// *************************************************************************** *
// *                                                                           *
// *                      Mentor Graphics Corporation                          *
// *                          All rights reserved                              *
// *                                                                           *
// *************************************************************************** *
// *                                                                           *
// * Description:         CANDB File                                           *
// * Generated at:        2021-09-06 14:00                                     *
// * System:              LPCsystem_MAIN                                       *
// * Network:             LPC1CAN                                              *
// *                                                                           *
// *************************************************************************** *
// *                                                                           *
// *             THIS CONFIGURATION MIGHT CONTAIN SOME ERRORS                  *
// *              IF THE INPUT MODEL WAS NOT PROPERLY FORMED!                  *
// *                    Do Not Use this File directly!                         *
// *                                                                           *
// *************************************************************************** *
VERSION "LPC1CAN"

NS_ :

BS_ :

BU_ :  LPC LPCdp LPCETC

BO_ 336 LpcdpLpc1canFr01_100ms : 48 LPCdp
 SG_ AccrPedlPsdSts : 360|1@0+ (1,0) [0|1] "" LPC
 SG_ AccrPedlPsdSts_UB : 361|1@0+ (1,0) [0|1] "" LPC
 SG_ BltRmnTelltl : 26|1@0+ (1,0) [0|1] "" LPC
 SG_ BltRmnTelltl_UB : 25|1@0+ (1,0) [0|1] "" LPC
 SG_ ChdProtnActvnReq_UB : 113|1@0+ (1,0) [0|1] "" LPC
 SG_ ChdProtnActvnReqDoorDrvrRe : 116|1@0+ (1,0) [0|1] "" LPC
 SG_ ChdProtnActvnReqDoorPass : 115|1@0+ (1,0) [0|1] "" LPC
 SG_ ChdProtnActvnReqDoorPassRe : 114|1@0+ (1,0) [0|1] "" LPC
 SG_ DblLckDi : 100|1@0+ (1,0) [0|1] "" LPC
 SG_ DblLckDi_UB : 99|1@0+ (1,0) [0|1] "" LPC
 SG_ DrvrDesDir1 : 108|3@0+ (1,0) [0|7] "" LPC
 SG_ DrvrDesDir1_UB : 105|1@0+ (1,0) [0|1] "" LPC
 SG_ DynCfgStrWhlPosnForUSS : 98|1@0+ (1,0) [0|1] "" LPC
 SG_ DynCfgStrWhlPosnForUSS_UB : 205|1@0+ (1,0) [0|1] "" LPC
 SG_ DynCfgVehTypForUSS : 311|16@0+ (1,0) [0|65535] "" LPC
 SG_ DynCfgVehTypForUSS_UB : 327|1@0+ (1,0) [0|1] "" LPC
 SG_ FrntWiprReq : 1|2@0+ (1,0) [0|3] "" LPC
 SG_ FrntWiprReq_UB : 2|1@0+ (1,0) [0|1] "" LPC
 SG_ FwdLookCamHeatingReq : 6|1@0+ (1,0) [0|1] "" LPC
 SG_ FwdLookCamHeatingReq_UB : 7|1@0+ (1,0) [0|1] "" LPC
 SG_ GlobalRealTimeGS : 279|32@0+ (1.0,0.0) [0.0|4294967295.0] "Unitless" LPC
 SG_ GlobalRealTimeGS_UB : 206|1@0+ (1,0) [0|1] "" LPC
 SG_ GlvBoxRelsBtnPsd : 23|1@0+ (1,0) [0|1] "" LPC
 SG_ GlvBoxRelsBtnPsd_UB : 24|1@0+ (1,0) [0|1] "" LPC
 SG_ HMISts : 84|2@0+ (1,0) [0|3] "" LPC
 SG_ HMISts_UB : 207|1@0+ (1,0) [0|1] "" LPC
 SG_ LcmaIndcnDrvr : 4|2@0+ (1,0) [0|3] "" LPC
 SG_ LcmaIndcnDrvr_UB : 5|1@0+ (1,0) [0|1] "" LPC
 SG_ LcmaIndcnPass : 39|2@0+ (1,0) [0|3] "" LPC
 SG_ LcmaIndcnPass_UB : 33|1@0+ (1,0) [0|1] "" LPC
 SG_ LockgExtReq_UB : 326|1@0+ (1,0) [0|1] "" LPC
 SG_ LockgExtReqLockActv : 351|4@0+ (1,0) [0|15] "" LPC
 SG_ LockgExtReqLockDly : 359|8@0+ (0.01,0.0) [0.0|2.5500000000000003] "Unitless" LPC
 SG_ LockgExtReqLockRep : 347|4@0- (1.0,0.0) [-8.0|7.0] "Unitless" LPC
 SG_ LockgPrsnlReq : 9|2@0+ (1,0) [0|3] "" LPC
 SG_ LockgPrsnlReq_UB : 10|1@0+ (1,0) [0|1] "" LPC
 SG_ LockgSetgFb_UB : 80|1@0+ (1,0) [0|1] "" LPC
 SG_ LockgSetgFbAudibleFeedback : 82|1@0+ (1,0) [0|1] "" LPC
 SG_ LockgSetgFbVisibleFeedback : 81|1@0+ (1,0) [0|1] "" LPC
 SG_ LockgSetgPas_UB : 91|1@0+ (1,0) [0|1] "" LPC
 SG_ LockgSetgPasLockBySpeed : 95|1@0+ (1,0) [0|1] "" LPC
 SG_ LockgSetgPasLockWalkAway : 94|1@0+ (1,0) [0|1] "" LPC
 SG_ LockgSetgPasUnlockApproach : 93|1@0+ (1,0) [0|1] "" LPC
 SG_ LockgSetgSngDoorUnlck : 92|1@0+ (1,0) [0|1] "" LPC
 SG_ LockgSetgSngDoorUnlck_UB : 32|1@0+ (1,0) [0|1] "" LPC
 SG_ MirrAutoDimSetg : 31|1@0+ (1,0) [0|1] "" LPC
 SG_ MirrAutoDimSetg_UB : 30|1@0+ (1,0) [0|1] "" LPC
 SG_ MirrCmdRecAtDrvr_UB : 16|1@0+ (1,0) [0|1] "" LPC
 SG_ MirrCmdRecAtDrvrMirrFoldCmd : 12|2@0+ (1,0) [0|3] "" LPC
 SG_ MirrCmdRecAtDrvrMirrPosAdjCmd : 15|3@0+ (1,0) [0|7] "" LPC
 SG_ MirrCmdRecAtPass_UB : 22|1@0+ (1,0) [0|1] "" LPC
 SG_ MirrCmdRecAtPassMirrFoldCmd : 21|2@0+ (1,0) [0|3] "" LPC
 SG_ MirrCmdRecAtPassMirrPosAdjCmd : 19|3@0+ (1,0) [0|7] "" LPC
 SG_ MirrDfrstType : 179|2@0+ (1,0) [0|3] "" LPC
 SG_ MirrDfrstType_UB : 177|1@0+ (1,0) [0|1] "" LPC
 SG_ MirrorDefrosterReq : 28|2@0+ (1,0) [0|3] "" LPC
 SG_ MirrorDefrosterReq_UB : 29|1@0+ (1,0) [0|1] "" LPC
 SG_ MirrorFuncCarCfg_UB : 180|1@0+ (1,0) [0|1] "" LPC
 SG_ MirrorFuncCarCfgExtRearViewMirrorType : 191|3@0+ (1,0) [0|7] "" LPC
 SG_ MirrorFuncCarCfgRearViewMirrorDimType : 188|3@0+ (1,0) [0|7] "" LPC
 SG_ MirrorFuncCarCfgRearViewMirrorMemType : 185|2@0+ (1,0) [0|3] "" LPC
 SG_ MirrPosnSensTrgtValDrvr_UB : 117|1@0+ (1,0) [0|1] "" LPC
 SG_ MirrPosnSensTrgtValDrvrMirrSensXPos : 127|16@0+ (1.0,0.0) [0.0|65535.0] "Unitless" LPC
 SG_ MirrPosnSensTrgtValDrvrMirrSensYPos : 143|16@0+ (1.0,0.0) [0.0|65535.0] "Unitless" LPC
 SG_ MirrPosnSensTrgtValPass_UB : 118|1@0+ (1,0) [0|1] "" LPC
 SG_ MirrPosnSensTrgtValPassMirrSensXPos : 47|16@0+ (1.0,0.0) [0.0|65535.0] "Unitless" LPC
 SG_ MirrPosnSensTrgtValPassMirrSensYPos : 63|16@0+ (1.0,0.0) [0.0|65535.0] "Unitless" LPC
 SG_ OutsideTemperatureGS : 335|16@0+ (1.0,0.0) [0.0|65535.0] "Unitless" LPC
 SG_ OutsideTemperatureGS_UB : 325|1@0+ (1,0) [0|1] "" LPC
 SG_ PassAirbLmpReq_UB : 176|1@0+ (1,0) [0|1] "" LPC
 SG_ PassAirbLmpReqChks : 152|8@1+ (1.0,0.0) [0.0|255.0] "Unitless" LPC
 SG_ PassAirbLmpReqCntr : 160|4@1+ (1.0,0.0) [0.0|15.0] "Unitless" LPC
 SG_ PassAirbLmpReqPassAirbLmpReq : 168|2@1+ (1,0) [0|3] "" LPC
 SG_ RainSnsrLiThdCmd : 323|4@0+ (5.0,-40.0) [-40.0|35.0] "%" LPC
 SG_ RainSnsrLiThdCmd_UB : 324|1@0+ (1,0) [0|1] "" LPC
 SG_ SnsrLiSnvty : 103|3@0+ (1,0) [0|7] "" LPC
 SG_ SnsrLiSnvty_UB : 119|1@0+ (1,0) [0|1] "" LPC
 SG_ SteerWhlLocCarCfgForDCU : 183|2@0+ (1,0) [0|3] "" LPC
 SG_ SteerWhlLocCarCfgForDCU_UB : 181|1@0+ (1,0) [0|1] "" LPC
 SG_ TotalDistanceGS : 215|32@0+ (1.0,0.0) [0.0|4294967295.0] "Unitless" LPC
 SG_ TotalDistanceGS_UB : 112|1@0+ (1,0) [0|1] "" LPC
 SG_ TrlrLampChkReq : 79|2@0+ (1,0) [0|3] "" LPC
 SG_ TrlrLampChkReq_UB : 77|1@0+ (1,0) [0|1] "" LPC
 SG_ TrOpenerBtnAcvtnReq : 97|2@0+ (1,0) [0|3] "" LPC
 SG_ TrOpenerBtnAcvtnReq_UB : 104|1@0+ (1,0) [0|1] "" LPC
 SG_ TwbrFoldFromHMI : 86|2@0+ (1,0) [0|3] "" LPC
 SG_ TwbrFoldFromHMI_UB : 87|1@0+ (1,0) [0|1] "" LPC
 SG_ TwliBriSts : 76|1@0+ (1,0) [0|1] "" LPC
 SG_ TwliBriSts_UB : 75|1@0+ (1,0) [0|1] "" LPC
 SG_ UsageModeGS : 247|8@0+ (1.0,0.0) [0.0|255.0] "Unitless" LPC
 SG_ UsageModeGS_UB : 201|1@0+ (1,0) [0|1] "" LPC
 SG_ VehAlrmDstbc : 271|8@0+ (1.0,0.0) [0.0|255.0] "Unitless" LPC
 SG_ VehAlrmDstbc_UB : 204|1@0+ (1,0) [0|1] "" LPC
 SG_ VehAlrmExtReq : 110|2@0+ (1,0) [0|3] "" LPC
 SG_ VehAlrmExtReq_UB : 111|1@0+ (1,0) [0|1] "" LPC
 SG_ VehAlrmPasDeactvnReq : 73|2@0+ (1,0) [0|3] "" LPC
 SG_ VehAlrmPasDeactvnReq_UB : 74|1@0+ (1,0) [0|1] "" LPC
 SG_ VehAlrmRednSts : 89|2@0+ (1,0) [0|3] "" LPC
 SG_ VehAlrmRednSts_UB : 90|1@0+ (1,0) [0|1] "" LPC
 SG_ VehicleBatteryVoltageGS : 255|8@0+ (1.0,0.0) [0.0|255.0] "Unitless" LPC
 SG_ VehicleBatteryVoltageGS_UB : 202|1@0+ (1,0) [0|1] "" LPC
 SG_ VehicleSpeedGS : 263|8@0+ (1.0,0.0) [0.0|255.0] "Unitless" LPC
 SG_ VehicleSpeedGS_UB : 203|1@0+ (1,0) [0|1] "" LPC
 SG_ VehTypeIfSPA2 : 37|3@0+ (1,0) [0|7] "" LPC
 SG_ VehTypeIfSPA2_UB : 34|1@0+ (1,0) [0|1] "" LPC
 SG_ WindowsFuncCarCfg_UB : 200|1@0+ (1,0) [0|1] "" LPC
 SG_ WindowsFuncCarCfgPinchProtectionLvl : 199|2@0+ (1,0) [0|3] "" LPC
 SG_ WindowsFuncCarCfgReserved0 : 197|2@0+ (1,0) [0|3] "" LPC
 SG_ WindowsFuncCarCfgTailgateWindowTintType : 195|2@0+ (1,0) [0|3] "" LPC
 SG_ WindowsFuncCarCfgWindowsGlassType : 193|2@0+ (1,0) [0|3] "" LPC

BO_ 338 LpcdpLpc1canFr02_10ms : 64 LPCdp
 SG_ ApduRespLpcFromIntrEth_UB : 449|1@0+ (1,0) [0|1] "" LPC
 SG_ ApduRespLpcFromIntrEthByte0 : 31|8@0+ (1.0,0.0) [0.0|255.0] "Unitless" LPC
 SG_ ApduRespLpcFromIntrEthByte1 : 39|8@0+ (1.0,0.0) [0.0|255.0] "Unitless" LPC
 SG_ ApduRespLpcFromIntrEthByte2 : 47|8@0+ (1.0,0.0) [0.0|255.0] "Unitless" LPC
 SG_ ApduRespLpcFromIntrEthByte3 : 55|8@0+ (1.0,0.0) [0.0|255.0] "Unitless" LPC
 SG_ ApduRespLpcFromIntrEthByte4 : 63|8@0+ (1.0,0.0) [0.0|255.0] "Unitless" LPC
 SG_ ApduRespLpcFromIntrEthByte5 : 71|8@0+ (1.0,0.0) [0.0|255.0] "Unitless" LPC
 SG_ ApduRespLpcFromIntrEthByte6 : 79|8@0+ (1.0,0.0) [0.0|255.0] "Unitless" LPC
 SG_ ApduRespLpcFromIntrEthByte7 : 87|8@0+ (1.0,0.0) [0.0|255.0] "Unitless" LPC
 SG_ ApplIdStsIntrEth : 379|3@0+ (1,0) [0|7] "" LPC
 SG_ ApplIdStsIntrEth_UB : 376|1@0+ (1,0) [0|1] "" LPC
 SG_ BltLockStDrvr : 419|1@0+ (1,0) [0|1] "" LPC
 SG_ BltLockStDrvr_UB : 418|1@0+ (1,0) [0|1] "" LPC
 SG_ CarModeSync_UB : 424|1@0+ (1,0) [0|1] "" LPC
 SG_ CarModeSyncCarMode : 431|4@0+ (1,0) [0|15] "" LPC
 SG_ CarModeSyncCarModeSubtype : 427|3@0+ (1,0) [0|7] "" LPC
 SG_ CrashModeSync : 417|1@0+ (1,0) [0|1] "" LPC
 SG_ CrashModeSync_UB : 416|1@0+ (1,0) [0|1] "" LPC
 SG_ GearLvlIndcn : 434|3@0+ (1,0) [0|7] "" LPC
 SG_ GearLvlIndcn_UB : 435|1@0+ (1,0) [0|1] "" LPC
 SG_ IntrBriStsAmb : 367|4@0+ (1.0,0.0) [0.0|15.0] "Unitless" LPC
 SG_ IntrBriStsAmb_UB : 445|1@0+ (1,0) [0|1] "" LPC
 SG_ IntrBriStsCsd : 363|4@0+ (1.0,0.0) [0.0|15.0] "Unitless" LPC
 SG_ IntrBriStsCsd_UB : 444|1@0+ (1,0) [0|1] "" LPC
 SG_ IntrBriStsDim : 375|4@0+ (1.0,0.0) [0.0|15.0] "Unitless" LPC
 SG_ IntrBriStsDim_UB : 443|1@0+ (1,0) [0|1] "" LPC
 SG_ IntrBriStsHud : 371|4@0+ (1.0,0.0) [0.0|15.0] "Unitless" LPC
 SG_ IntrBriStsHud_UB : 442|1@0+ (1,0) [0|1] "" LPC
 SG_ IntrBriStsSwt : 383|4@0+ (1.0,0.0) [0.0|15.0] "Unitless" LPC
 SG_ IntrBriStsSwt_UB : 441|1@0+ (1,0) [0|1] "" LPC
 SG_ IntrLiUsrPrsnt_UB : 440|1@0+ (1,0) [0|1] "" LPC
 SG_ IntrLiUsrPrsntDrvrSeat : 391|2@0+ (1,0) [0|3] "" LPC
 SG_ IntrLiUsrPrsntPassSeat : 389|2@0+ (1,0) [0|3] "" LPC
 SG_ IntrLiUsrPrsntReCentrSeat2nd : 387|2@0+ (1,0) [0|3] "" LPC
 SG_ IntrLiUsrPrsntReDrvrSeat2nd : 385|2@0+ (1,0) [0|3] "" LPC
 SG_ IntrLiUsrPrsntReDrvrSeat3nd : 399|2@0+ (1,0) [0|3] "" LPC
 SG_ IntrLiUsrPrsntRePassSeat2nd : 397|2@0+ (1,0) [0|3] "" LPC
 SG_ IntrLiUsrPrsntRePassSeat3nd : 395|2@0+ (1,0) [0|3] "" LPC
 SG_ IntrLiUsrPrsntTrAr : 393|2@0+ (1,0) [0|3] "" LPC
 SG_ PinionAg_UB : 7|1@0+ (1,0) [0|1] "" LPC
 SG_ PinionAgPinionSteerAg1 : 6|15@0- (0.0009765625,0.0) [-14.5|14.5] "rad" LPC
 SG_ PinionAgPinionSteerAg1Qf : 17|2@0+ (1,0) [0|3] "" LPC
 SG_ PowerControllerRlySync_UB : 454|1@0+ (1,0) [0|1] "" LPC
 SG_ PowerControllerRlySyncADPMWakeUpSync : 168|1@1+ (1,0) [0|1] "" LPC
 SG_ PowerControllerRlySyncAUDWakeUpSync : 169|1@1+ (1,0) [0|1] "" LPC
 SG_ PowerControllerRlySyncChks : 152|8@1+ (1.0,0.0) [0.0|255.0] "Unitless" LPC
 SG_ PowerControllerRlySyncClimateActuatorRelaySync : 170|1@1+ (1,0) [0|1] "" LPC
 SG_ PowerControllerRlySyncCntr : 160|4@1+ (1.0,0.0) [0.0|15.0] "Unitless" LPC
 SG_ PowerControllerRlySyncDIMWakeUpSync : 171|1@1+ (1,0) [0|1] "" LPC
 SG_ PowerControllerRlySyncExteriorLightRelaySync : 172|1@1+ (1,0) [0|1] "" LPC
 SG_ PowerControllerRlySyncIgnitionPowerRelaySync : 173|1@1+ (1,0) [0|1] "" LPC
 SG_ PowerControllerRlySyncSUMWakeUpSync : 174|1@1+ (1,0) [0|1] "" LPC
 SG_ PreApduSndIntrEth : 407|1@0+ (1,0) [0|1] "" LPC
 SG_ PreApduSndIntrEth_UB : 406|1@0+ (1,0) [0|1] "" LPC
 SG_ ServiceModeSync : 405|1@0+ (1,0) [0|1] "" LPC
 SG_ ServiceModeSync_UB : 404|1@0+ (1,0) [0|1] "" LPC
 SG_ SingleWipeReq : 437|2@0+ (1,0) [0|3] "" LPC
 SG_ SingleWipeReq_UB : 451|1@0+ (1,0) [0|1] "" LPC
 SG_ UsageAuthDriverAuthChk1 : 183|32@0+ (1.0,0.0) [0.0|4294967295.0] "Unitless" LPC
 SG_ UsageAuthDriverAuthChk1_UB : 453|1@0+ (1,0) [0|1] "" LPC
 SG_ UsageAuthDriverAuthChk2 : 215|32@0+ (1.0,0.0) [0.0|4294967295.0] "Unitless" LPC
 SG_ UsageAuthDriverAuthChk2_UB : 452|1@0+ (1,0) [0|1] "" LPC
 SG_ UsageModeAvailableSync : 403|1@0+ (1,0) [0|1] "" LPC
 SG_ UsageModeAvailableSync_UB : 402|1@0+ (1,0) [0|1] "" LPC
 SG_ UsageModeAwakeSync : 401|1@0+ (1,0) [0|1] "" LPC
 SG_ UsageModeAwakeSync_UB : 400|1@0+ (1,0) [0|1] "" LPC
 SG_ UsageModeConvenienceSync : 415|1@0+ (1,0) [0|1] "" LPC
 SG_ UsageModeConvenienceSync_UB : 414|1@0+ (1,0) [0|1] "" LPC
 SG_ UsageModeDrivingSync : 413|1@0+ (1,0) [0|1] "" LPC
 SG_ UsageModeDrivingSync_UB : 412|1@0+ (1,0) [0|1] "" LPC
 SG_ UsageModeMovableSync : 411|1@0+ (1,0) [0|1] "" LPC
 SG_ UsageModeMovableSync_UB : 410|1@0+ (1,0) [0|1] "" LPC
 SG_ UsageModeResponsiveSync : 409|1@0+ (1,0) [0|1] "" LPC
 SG_ UsageModeResponsiveSync_UB : 408|1@0+ (1,0) [0|1] "" LPC
 SG_ VehModMngmntSigDCU_UB : 450|1@0+ (1,0) [0|1] "" LPC
 SG_ VehModMngmntSigDCUCarModeSts : 479|3@0+ (1,0) [0|7] "" LPC
 SG_ VehModMngmntSigDCUCarModeSubType : 473|2@0+ (1,0) [0|3] "" LPC
 SG_ VehModMngmntSigDCUElecEnergyLvlDCU : 487|2@0+ (1,0) [0|3] "" LPC
 SG_ VehModMngmntSigDCUElecPowerLvlDCU : 485|3@0+ (1,0) [0|7] "" LPC
 SG_ VehModMngmntSigDCUReserved1 : 463|8@0+ (1.0,0.0) [0.0|255.0] "Unitless" LPC
 SG_ VehModMngmntSigDCUReserved2 : 471|8@0+ (1.0,0.0) [0.0|255.0] "Unitless" LPC
 SG_ VehModMngmntSigDCUUsageModeSts : 476|3@0+ (1,0) [0|7] "" LPC
 SG_ WinFunctnAvailbltySig : 423|3@0+ (1,0) [0|7] "" LPC
 SG_ WinFunctnAvailbltySig_UB : 420|1@0+ (1,0) [0|1] "" LPC

BO_ 340 LpcdpLpc1canFr04_10ms : 64 LPCdp
 SG_ ExLiLpHiDefZone1_UB : 440|1@0+ (1,0) [0|1] "" LPC
 SG_ ExLiLpHiDefZone1BottomAg : 7|9@0- (0.0015,0.0) [-0.384|0.3825] "rad" LPC
 SG_ ExLiLpHiDefZone1GradWdth : 14|9@0- (0.0015,0.0) [-0.384|0.3825] "rad" LPC
 SG_ ExLiLpHiDefZone1LeAgPrpty : 21|3@0+ (1.0,0.0) [0.0|7.0] "Unitless" LPC
 SG_ ExLiLpHiDefZone1LeLampLeAg : 17|10@0- (0.0015,0.0) [-0.768|0.7665000000000001] "rad" LPC
 SG_ ExLiLpHiDefZone1LeLampRiAg : 47|10@0- (0.0015,0.0) [-0.768|0.7665000000000001] "rad" LPC
 SG_ ExLiLpHiDefZone1ObjctZoneIntens : 39|8@0+ (1.0,0.0) [0.0|255.0] "Unitless" LPC
 SG_ ExLiLpHiDefZone1RiAgPrpty : 53|3@0+ (1.0,0.0) [0.0|7.0] "Unitless" LPC
 SG_ ExLiLpHiDefZone1RiLampLeAg : 49|10@0- (0.0015,0.0) [-0.768|0.7665000000000001] "rad" LPC
 SG_ ExLiLpHiDefZone1RiLampRiAg : 71|10@0- (0.0015,0.0) [-0.768|0.7665000000000001] "rad" LPC
 SG_ ExLiLpHiDefZone1TopAg : 77|9@0- (0.0015,0.0) [-0.384|0.3825] "rad" LPC
 SG_ ExLiLpHiDefZone2_UB : 441|1@0+ (1,0) [0|1] "" LPC
 SG_ ExLiLpHiDefZone2BottomAg : 95|9@0- (0.0015,0.0) [-0.384|0.3825] "rad" LPC
 SG_ ExLiLpHiDefZone2GradWdth : 102|9@0- (0.0015,0.0) [-0.384|0.3825] "rad" LPC
 SG_ ExLiLpHiDefZone2LeAgPrpty : 109|3@0+ (1.0,0.0) [0.0|7.0] "Unitless" LPC
 SG_ ExLiLpHiDefZone2LeLampLeAg : 105|10@0- (0.0015,0.0) [-0.768|0.7665000000000001] "rad" LPC
 SG_ ExLiLpHiDefZone2LeLampRiAg : 135|10@0- (0.0015,0.0) [-0.768|0.7665000000000001] "rad" LPC
 SG_ ExLiLpHiDefZone2ObjctZoneIntens : 127|8@0+ (1.0,0.0) [0.0|255.0] "Unitless" LPC
 SG_ ExLiLpHiDefZone2RiAgPrpty : 141|3@0+ (1.0,0.0) [0.0|7.0] "Unitless" LPC
 SG_ ExLiLpHiDefZone2RiLampLeAg : 137|10@0- (0.0015,0.0) [-0.768|0.7665000000000001] "rad" LPC
 SG_ ExLiLpHiDefZone2RiLampRiAg : 159|10@0- (0.0015,0.0) [-0.768|0.7665000000000001] "rad" LPC
 SG_ ExLiLpHiDefZone2TopAg : 165|9@0- (0.0015,0.0) [-0.384|0.3825] "rad" LPC
 SG_ ExLiLpHiDefZone3_UB : 442|1@0+ (1,0) [0|1] "" LPC
 SG_ ExLiLpHiDefZone3BottomAg : 183|9@0- (0.0015,0.0) [-0.384|0.3825] "rad" LPC
 SG_ ExLiLpHiDefZone3GradWdth : 190|9@0- (0.0015,0.0) [-0.384|0.3825] "rad" LPC
 SG_ ExLiLpHiDefZone3LeAgPrpty : 197|3@0+ (1.0,0.0) [0.0|7.0] "Unitless" LPC
 SG_ ExLiLpHiDefZone3LeLampLeAg : 193|10@0- (0.0015,0.0) [-0.768|0.7665000000000001] "rad" LPC
 SG_ ExLiLpHiDefZone3LeLampRiAg : 223|10@0- (0.0015,0.0) [-0.768|0.7665000000000001] "rad" LPC
 SG_ ExLiLpHiDefZone3ObjctZoneIntens : 215|8@0+ (1.0,0.0) [0.0|255.0] "Unitless" LPC
 SG_ ExLiLpHiDefZone3RiAgPrpty : 229|3@0+ (1.0,0.0) [0.0|7.0] "Unitless" LPC
 SG_ ExLiLpHiDefZone3RiLampLeAg : 225|10@0- (0.0015,0.0) [-0.768|0.7665000000000001] "rad" LPC
 SG_ ExLiLpHiDefZone3RiLampRiAg : 247|10@0- (0.0015,0.0) [-0.768|0.7665000000000001] "rad" LPC
 SG_ ExLiLpHiDefZone3TopAg : 253|9@0- (0.0015,0.0) [-0.384|0.3825] "rad" LPC
 SG_ ExLiLpHiDefZone4_UB : 443|1@0+ (1,0) [0|1] "" LPC
 SG_ ExLiLpHiDefZone4BottomAg : 271|9@0- (0.0015,0.0) [-0.384|0.3825] "rad" LPC
 SG_ ExLiLpHiDefZone4GradWdth : 278|9@0- (0.0015,0.0) [-0.384|0.3825] "rad" LPC
 SG_ ExLiLpHiDefZone4LeAgPrpty : 285|3@0+ (1.0,0.0) [0.0|7.0] "Unitless" LPC
 SG_ ExLiLpHiDefZone4LeLampLeAg : 281|10@0- (0.0015,0.0) [-0.768|0.7665000000000001] "rad" LPC
 SG_ ExLiLpHiDefZone4LeLampRiAg : 311|10@0- (0.0015,0.0) [-0.768|0.7665000000000001] "rad" LPC
 SG_ ExLiLpHiDefZone4ObjctZoneIntens : 303|8@0+ (1.0,0.0) [0.0|255.0] "Unitless" LPC
 SG_ ExLiLpHiDefZone4RiAgPrpty : 317|3@0+ (1.0,0.0) [0.0|7.0] "Unitless" LPC
 SG_ ExLiLpHiDefZone4RiLampLeAg : 313|10@0- (0.0015,0.0) [-0.768|0.7665000000000001] "rad" LPC
 SG_ ExLiLpHiDefZone4RiLampRiAg : 335|10@0- (0.0015,0.0) [-0.768|0.7665000000000001] "rad" LPC
 SG_ ExLiLpHiDefZone4TopAg : 341|9@0- (0.0015,0.0) [-0.384|0.3825] "rad" LPC
 SG_ ExLiLpHiDefZone5_UB : 444|1@0+ (1,0) [0|1] "" LPC
 SG_ ExLiLpHiDefZone5BottomAg : 359|9@0- (0.0015,0.0) [-0.384|0.3825] "rad" LPC
 SG_ ExLiLpHiDefZone5GradWdth : 366|9@0- (0.0015,0.0) [-0.384|0.3825] "rad" LPC
 SG_ ExLiLpHiDefZone5LeAgPrpty : 373|3@0+ (1.0,0.0) [0.0|7.0] "Unitless" LPC
 SG_ ExLiLpHiDefZone5LeLampLeAg : 369|10@0- (0.0015,0.0) [-0.768|0.7665000000000001] "rad" LPC
 SG_ ExLiLpHiDefZone5LeLampRiAg : 399|10@0- (0.0015,0.0) [-0.768|0.7665000000000001] "rad" LPC
 SG_ ExLiLpHiDefZone5ObjctZoneIntens : 391|8@0+ (1.0,0.0) [0.0|255.0] "Unitless" LPC
 SG_ ExLiLpHiDefZone5RiAgPrpty : 405|3@0+ (1.0,0.0) [0.0|7.0] "Unitless" LPC
 SG_ ExLiLpHiDefZone5RiLampLeAg : 401|10@0- (0.0015,0.0) [-0.768|0.7665000000000001] "rad" LPC
 SG_ ExLiLpHiDefZone5RiLampRiAg : 423|10@0- (0.0015,0.0) [-0.768|0.7665000000000001] "rad" LPC
 SG_ ExLiLpHiDefZone5TopAg : 429|9@0- (0.0015,0.0) [-0.384|0.3825] "rad" LPC

BO_ 341 LpcdpLpc1canFr05_10ms : 48 LPCdp
 SG_ ExLiLpHiDefHozlLe_UB : 267|1@0+ (1,0) [0|1] "" LPC
 SG_ ExLiLpHiDefHozlLeDLPHozlLeEna : 284|1@0+ (1,0) [0|1] "" LPC
 SG_ ExLiLpHiDefHozlLeDLPHozlLeReq : 279|11@0+ (0.0004,-0.4094) [-0.4094|0.4094000000000001] "rad" LPC
 SG_ ExLiLpHiDefHozlRi_UB : 268|1@0+ (1,0) [0|1] "" LPC
 SG_ ExLiLpHiDefHozlRiDLPHozlRiEna : 300|1@0+ (1,0) [0|1] "" LPC
 SG_ ExLiLpHiDefHozlRiDLPHozlRiReq : 295|11@0+ (0.0004,-0.4094) [-0.4094|0.4094000000000001] "rad" LPC
 SG_ ExLiLpHiDefLiLe_UB : 269|1@0+ (1,0) [0|1] "" LPC
 SG_ ExLiLpHiDefLiLeDLPLeShape : 311|5@0+ (1.0,0.0) [0.0|31.0] "Unitless" LPC
 SG_ ExLiLpHiDefLiLeDLPLeSlope : 304|9@0+ (0.01,0.0) [0.0|5.11] "s" LPC
 SG_ ExLiLpHiDefLiLeDLPLeTransition : 327|4@0+ (1.0,0.0) [0.0|15.0] "Unitless" LPC
 SG_ ExLiLpHiDefLiLeTrafficSide : 306|2@0+ (1,0) [0|3] "" LPC
 SG_ ExLiLpHiDefLiRi_UB : 270|1@0+ (1,0) [0|1] "" LPC
 SG_ ExLiLpHiDefLiRiDLPRiShape : 335|5@0+ (1.0,0.0) [0.0|31.0] "Unitless" LPC
 SG_ ExLiLpHiDefLiRiDLPRiSlope : 328|9@0+ (0.01,0.0) [0.0|5.11] "s" LPC
 SG_ ExLiLpHiDefLiRiDLPRiTransition : 351|4@0+ (1.0,0.0) [0.0|15.0] "Unitless" LPC
 SG_ ExLiLpHiDefLiRiTrafficSide : 330|2@0+ (1,0) [0|3] "" LPC
 SG_ ExLiLpHiDefZone6_UB : 264|1@0+ (1,0) [0|1] "" LPC
 SG_ ExLiLpHiDefZone6BottomAg : 7|9@0- (0.0015,0.0) [-0.384|0.3825] "rad" LPC
 SG_ ExLiLpHiDefZone6GradWdth : 14|9@0- (0.0015,0.0) [-0.384|0.3825] "rad" LPC
 SG_ ExLiLpHiDefZone6LeAgPrpty : 21|3@0+ (1.0,0.0) [0.0|7.0] "Unitless" LPC
 SG_ ExLiLpHiDefZone6LeLampLeAg : 17|10@0- (0.0015,0.0) [-0.768|0.7665000000000001] "rad" LPC
 SG_ ExLiLpHiDefZone6LeLampRiAg : 47|10@0- (0.0015,0.0) [-0.768|0.7665000000000001] "rad" LPC
 SG_ ExLiLpHiDefZone6ObjctZoneIntens : 39|8@0+ (1.0,0.0) [0.0|255.0] "Unitless" LPC
 SG_ ExLiLpHiDefZone6RiAgPrpty : 53|3@0+ (1.0,0.0) [0.0|7.0] "Unitless" LPC
 SG_ ExLiLpHiDefZone6RiLampLeAg : 49|10@0- (0.0015,0.0) [-0.768|0.7665000000000001] "rad" LPC
 SG_ ExLiLpHiDefZone6RiLampRiAg : 71|10@0- (0.0015,0.0) [-0.768|0.7665000000000001] "rad" LPC
 SG_ ExLiLpHiDefZone6TopAg : 77|9@0- (0.0015,0.0) [-0.384|0.3825] "rad" LPC
 SG_ ExLiLpHiDefZone7_UB : 265|1@0+ (1,0) [0|1] "" LPC
 SG_ ExLiLpHiDefZone7BottomAg : 95|9@0- (0.0015,0.0) [-0.384|0.3825] "rad" LPC
 SG_ ExLiLpHiDefZone7GradWdth : 102|9@0- (0.0015,0.0) [-0.384|0.3825] "rad" LPC
 SG_ ExLiLpHiDefZone7LeAgPrpty : 109|3@0+ (1.0,0.0) [0.0|7.0] "Unitless" LPC
 SG_ ExLiLpHiDefZone7LeLampLeAg : 105|10@0- (0.0015,0.0) [-0.768|0.7665000000000001] "rad" LPC
 SG_ ExLiLpHiDefZone7LeLampRiAg : 135|10@0- (0.0015,0.0) [-0.768|0.7665000000000001] "rad" LPC
 SG_ ExLiLpHiDefZone7ObjctZoneIntens : 127|8@0+ (1.0,0.0) [0.0|255.0] "Unitless" LPC
 SG_ ExLiLpHiDefZone7RiAgPrpty : 141|3@0+ (1.0,0.0) [0.0|7.0] "Unitless" LPC
 SG_ ExLiLpHiDefZone7RiLampLeAg : 137|10@0- (0.0015,0.0) [-0.768|0.7665000000000001] "rad" LPC
 SG_ ExLiLpHiDefZone7RiLampRiAg : 159|10@0- (0.0015,0.0) [-0.768|0.7665000000000001] "rad" LPC
 SG_ ExLiLpHiDefZone7TopAg : 165|9@0- (0.0015,0.0) [-0.384|0.3825] "rad" LPC
 SG_ ExLiLpHiDefZone8_UB : 266|1@0+ (1,0) [0|1] "" LPC
 SG_ ExLiLpHiDefZone8BottomAg : 183|9@0- (0.0015,0.0) [-0.384|0.3825] "rad" LPC
 SG_ ExLiLpHiDefZone8GradWdth : 190|9@0- (0.0015,0.0) [-0.384|0.3825] "rad" LPC
 SG_ ExLiLpHiDefZone8LeAgPrpty : 197|3@0+ (1.0,0.0) [0.0|7.0] "Unitless" LPC
 SG_ ExLiLpHiDefZone8LeLampLeAg : 193|10@0- (0.0015,0.0) [-0.768|0.7665000000000001] "rad" LPC
 SG_ ExLiLpHiDefZone8LeLampRiAg : 223|10@0- (0.0015,0.0) [-0.768|0.7665000000000001] "rad" LPC
 SG_ ExLiLpHiDefZone8ObjctZoneIntens : 215|8@0+ (1.0,0.0) [0.0|255.0] "Unitless" LPC
 SG_ ExLiLpHiDefZone8RiAgPrpty : 229|3@0+ (1.0,0.0) [0.0|7.0] "Unitless" LPC
 SG_ ExLiLpHiDefZone8RiLampLeAg : 225|10@0- (0.0015,0.0) [-0.768|0.7665000000000001] "rad" LPC
 SG_ ExLiLpHiDefZone8RiLampRiAg : 247|10@0- (0.0015,0.0) [-0.768|0.7665000000000001] "rad" LPC
 SG_ ExLiLpHiDefZone8TopAg : 253|9@0- (0.0015,0.0) [-0.384|0.3825] "rad" LPC

BO_ 342 LpcdpLpc1canFr06_20ms : 64 LPCdp
 SG_ DoorModuleCarCfg_UB : 48|1@0+ (1,0) [0|1] "" LPC
 SG_ DoorModuleCarCfgDDMMountInfo : 63|2@0+ (1,0) [0|3] "" LPC
 SG_ DoorModuleCarCfgPDMMountInfo : 61|2@0+ (1,0) [0|3] "" LPC
 SG_ DoorModuleCarCfgRDDMMountInfo : 59|2@0+ (1,0) [0|3] "" LPC
 SG_ DoorModuleCarCfgRPDMMountInfo : 57|2@0+ (1,0) [0|3] "" LPC
 SG_ ExLiHpHdlampConcealLe_UB : 175|1@0+ (1,0) [0|1] "" LPC
 SG_ ExLiHpHdlampConcealLeChks : 352|8@1+ (1.0,0.0) [0.0|255.0] "Unitless" LPC
 SG_ ExLiHpHdlampConcealLeCntr : 360|4@1+ (1.0,0.0) [0.0|15.0] "Unitless" LPC
 SG_ ExLiHpHdlampConcealLeEna : 378|1@1+ (1,0) [0|1] "" LPC
 SG_ ExLiHpHdlampConcealLeMotSply : 379|1@1+ (1,0) [0|1] "" LPC
 SG_ ExLiHpHdlampConcealLePosnReq : 376|2@1+ (1,0) [0|3] "" LPC
 SG_ ExLiHpHdlampConcealLeRefForce : 380|1@1+ (1,0) [0|1] "" LPC
 SG_ ExLiHpHdlampConcealLeRefOk : 381|1@1+ (1,0) [0|1] "" LPC
 SG_ ExLiHpHdlampConcealLeSpd : 368|8@1+ (0.01,0.0) [0.0|2.5500000000000003] "s" LPC
 SG_ ExLiHpHdlampConcealRi_UB : 161|1@0+ (1,0) [0|1] "" LPC
 SG_ ExLiHpHdlampConcealRiChks : 384|8@1+ (1.0,0.0) [0.0|255.0] "Unitless" LPC
 SG_ ExLiHpHdlampConcealRiCntr : 392|4@1+ (1.0,0.0) [0.0|15.0] "Unitless" LPC
 SG_ ExLiHpHdlampConcealRiEna : 410|1@1+ (1,0) [0|1] "" LPC
 SG_ ExLiHpHdlampConcealRiMotSply : 411|1@1+ (1,0) [0|1] "" LPC
 SG_ ExLiHpHdlampConcealRiPosnReq : 408|2@1+ (1,0) [0|3] "" LPC
 SG_ ExLiHpHdlampConcealRiRefForce : 412|1@1+ (1,0) [0|1] "" LPC
 SG_ ExLiHpHdlampConcealRiRefOk : 413|1@1+ (1,0) [0|1] "" LPC
 SG_ ExLiHpHdlampConcealRiSpd : 400|8@1+ (0.01,0.0) [0.0|2.5500000000000003] "s" LPC
 SG_ ExLiHpHdlampDrlPosLe_UB : 436|1@0+ (1,0) [0|1] "" LPC
 SG_ ExLiHpHdlampDrlPosLeFocus : 423|4@0+ (1.0,0.0) [0.0|15.0] "Unitless" LPC
 SG_ ExLiHpHdlampDrlPosLeShape : 438|2@0+ (1,0) [0|3] "" LPC
 SG_ ExLiHpHdlampDrlPosLeSlope : 431|9@0+ (0.01,0.0) [0.0|5.11] "s" LPC
 SG_ ExLiHpHdlampDrlPosLeTransition : 419|4@0+ (1.0,0.0) [0.0|15.0] "Unitless" LPC
 SG_ ExLiHpHdlampDrlPosRi_UB : 460|1@0+ (1,0) [0|1] "" LPC
 SG_ ExLiHpHdlampDrlPosRiFocus : 447|4@0+ (1.0,0.0) [0.0|15.0] "Unitless" LPC
 SG_ ExLiHpHdlampDrlPosRiShape : 462|2@0+ (1,0) [0|3] "" LPC
 SG_ ExLiHpHdlampDrlPosRiSlope : 455|9@0+ (0.01,0.0) [0.0|5.11] "s" LPC
 SG_ ExLiHpHdlampDrlPosRiTransition : 443|4@0+ (1.0,0.0) [0.0|15.0] "Unitless" LPC
 SG_ ExLiHpHdlampSmlLe_UB : 473|1@0+ (1,0) [0|1] "" LPC
 SG_ ExLiHpHdlampSmlLeSideMkrLe : 474|1@0+ (1,0) [0|1] "" LPC
 SG_ ExLiHpHdlampSmlLeSideMkrLeFocus : 478|4@0+ (1.0,0.0) [0.0|15.0] "Unitless" LPC
 SG_ ExLiHpHdlampSmlLeSideMkrLeSlope : 471|9@0+ (0.01,0.0) [0.0|5.11] "s" LPC
 SG_ ExLiHpHdlampSmlRi_UB : 489|1@0+ (1,0) [0|1] "" LPC
 SG_ ExLiHpHdlampSmlRiSideMkrRi : 490|1@0+ (1,0) [0|1] "" LPC
 SG_ ExLiHpHdlampSmlRiSideMkrRiFocus : 494|4@0+ (1.0,0.0) [0.0|15.0] "Unitless" LPC
 SG_ ExLiHpHdlampSmlRiSideMkrRiSlope : 487|9@0+ (0.01,0.0) [0.0|5.11] "s" LPC
 SG_ ExLiHpHiDefCalibrationStsLe : 435|2@0+ (1,0) [0|3] "" LPC
 SG_ ExLiHpHiDefCalibrationStsLe_UB : 433|1@0+ (1,0) [0|1] "" LPC
 SG_ ExLiHpHiDefCalibrationStsRi : 459|2@0+ (1,0) [0|3] "" LPC
 SG_ ExLiHpHiDefCalibrationStsRi_UB : 457|1@0+ (1,0) [0|1] "" LPC
 SG_ ExLiHpRearSmlLi : 432|1@0+ (1,0) [0|1] "" LPC
 SG_ ExLiHpRearSmlLi_UB : 456|1@0+ (1,0) [0|1] "" LPC
 SG_ ExLiHpTrlrLiActvn_UB : 36|1@0+ (1,0) [0|1] "" LPC
 SG_ ExLiHpTrlrLiActvnBrk : 40|1@0+ (1,0) [0|1] "" LPC
 SG_ ExLiHpTrlrLiActvnFog : 41|1@0+ (1,0) [0|1] "" LPC
 SG_ ExLiHpTrlrLiActvnPosn : 42|1@0+ (1,0) [0|1] "" LPC
 SG_ ExLiHpTrlrLiActvnRvsg : 43|1@0+ (1,0) [0|1] "" LPC
 SG_ ExLiLpHdlampLiLe_UB : 170|1@0+ (1,0) [0|1] "" LPC
 SG_ ExLiLpHdlampLiLeBeamLeFocus : 208|4@1+ (1.0,0.0) [0.0|15.0] "Unitless" LPC
 SG_ ExLiLpHdlampLiLeBeamLeShape : 212|4@1+ (1,0) [0|15] "" LPC
 SG_ ExLiLpHdlampLiLeBeamLeSlope : 224|9@1+ (0.01,0.0) [0.0|5.11] "s" LPC
 SG_ ExLiLpHdlampLiLeBeamLeSymbol : 216|4@1+ (1.0,0.0) [0.0|15.0] "Unitless" LPC
 SG_ ExLiLpHdlampLiLeBeamLeTransition : 220|4@1+ (1.0,0.0) [0.0|15.0] "Unitless" LPC
 SG_ ExLiLpHdlampLiLeHeadlampLeChks : 192|8@1+ (1.0,0.0) [0.0|255.0] "Unitless" LPC
 SG_ ExLiLpHdlampLiLeHeadlampLeCntr : 200|4@1+ (1.0,0.0) [0.0|15.0] "Unitless" LPC
 SG_ ExLiLpHdlampLiLeLiTrfcSide : 233|2@1+ (1,0) [0|3] "" LPC
 SG_ ExLiLpHdlampLiRi_UB : 172|1@0+ (1,0) [0|1] "" LPC
 SG_ ExLiLpHdlampLiRiBeamRiFocus : 256|4@1+ (1.0,0.0) [0.0|15.0] "Unitless" LPC
 SG_ ExLiLpHdlampLiRiBeamRiShape : 260|4@1+ (1,0) [0|15] "" LPC
 SG_ ExLiLpHdlampLiRiBeamRiSlope : 272|9@1+ (0.01,0.0) [0.0|5.11] "s" LPC
 SG_ ExLiLpHdlampLiRiBeamRiSymbol : 264|4@1+ (1.0,0.0) [0.0|15.0] "Unitless" LPC
 SG_ ExLiLpHdlampLiRiBeamRiTransition : 268|4@1+ (1.0,0.0) [0.0|15.0] "Unitless" LPC
 SG_ ExLiLpHdlampLiRiHeadlampRiChks : 240|8@1+ (1.0,0.0) [0.0|255.0] "Unitless" LPC
 SG_ ExLiLpHdlampLiRiHeadlampRiCntr : 248|4@1+ (1.0,0.0) [0.0|15.0] "Unitless" LPC
 SG_ ExLiLpHdlampLiRiLiTrfcSide : 281|2@1+ (1,0) [0|3] "" LPC
 SG_ ExLiLpHdlampLvlLe_UB : 169|1@0+ (1,0) [0|1] "" LPC
 SG_ ExLiLpHdlampLvlLeLvlLeChks : 288|8@1+ (1.0,0.0) [0.0|255.0] "Unitless" LPC
 SG_ ExLiLpHdlampLvlLeLvlLeCntr : 296|4@1+ (1.0,0.0) [0.0|15.0] "Unitless" LPC
 SG_ ExLiLpHdlampLvlLeLvlLeEna : 315|1@1+ (1,0) [0|1] "" LPC
 SG_ ExLiLpHdlampLvlLeLvlLeMotSply : 318|1@1+ (1,0) [0|1] "" LPC
 SG_ ExLiLpHdlampLvlLeLvlLeRefForce : 316|1@1+ (1,0) [0|1] "" LPC
 SG_ ExLiLpHdlampLvlLeLvlLeRefOk : 317|1@1+ (1,0) [0|1] "" LPC
 SG_ ExLiLpHdlampLvlLeLvlLeReq : 304|11@1+ (0.0002,-0.204) [-0.204|0.20540000000000005] "rad" LPC
 SG_ ExLiLpHdlampLvlRi_UB : 168|1@0+ (1,0) [0|1] "" LPC
 SG_ ExLiLpHdlampLvlRiLvlRiChks : 320|8@1+ (1.0,0.0) [0.0|255.0] "Unitless" LPC
 SG_ ExLiLpHdlampLvlRiLvlRiCntr : 328|4@1+ (1.0,0.0) [0.0|15.0] "Unitless" LPC
 SG_ ExLiLpHdlampLvlRiLvlRiEna : 347|1@1+ (1,0) [0|1] "" LPC
 SG_ ExLiLpHdlampLvlRiLvlRiMotSply : 350|1@1+ (1,0) [0|1] "" LPC
 SG_ ExLiLpHdlampLvlRiLvlRiRefForce : 348|1@1+ (1,0) [0|1] "" LPC
 SG_ ExLiLpHdlampLvlRiLvlRiRefOk : 349|1@1+ (1,0) [0|1] "" LPC
 SG_ ExLiLpHdlampLvlRiLvlRiReq : 336|11@1+ (0.0002,-0.204) [-0.204|0.20540000000000005] "rad" LPC
 SG_ FrntWhlAg_UB : 67|1@0+ (1,0) [0|1] "" LPC
 SG_ FrntWhlAgFrntWhlAg : 79|15@0+ (0.00005249,-0.85) [-0.85|0.8500461200000001] "rad" LPC
 SG_ FrntWhlAgMaxWhlAg : 95|15@0+ (0.00005249,-0.85) [-0.85|0.8500461200000001] "rad" LPC
 SG_ LCMACarCfg_UB : 68|1@0+ (1,0) [0|1] "" LPC
 SG_ LCMACarCfgBlisInfoSys : 71|3@0+ (1,0) [0|7] "" LPC
 SG_ PAPGearShiftrIntv : 12|3@0+ (1,0) [0|7] "" LPC
 SG_ PAPGearShiftrIntv_UB : 173|1@0+ (1,0) [0|1] "" LPC
 SG_ PAPLoSpdMod : 34|3@0+ (1,0) [0|7] "" LPC
 SG_ PAPLoSpdMod_UB : 35|1@0+ (1,0) [0|1] "" LPC
 SG_ ReFogLi_UB : 171|1@0+ (1,0) [0|1] "" LPC
 SG_ ReFogLiIntensity : 118|7@0+ (1.0,0.0) [0.0|100.0] "%" LPC
 SG_ ReFogLiReq : 105|3@0+ (1,0) [0|7] "" LPC
 SG_ ReFogLiSlope : 111|6@0+ (0.1,0.0) [0.0|6.300000000000001] "s" LPC
 SG_ RegLi_UB : 176|1@0+ (1,0) [0|1] "" LPC
 SG_ RegLiReq : 177|1@0+ (1,0) [0|1] "" LPC
 SG_ RegLiSlope : 183|6@0+ (0.1,0.0) [0.0|6.300000000000001] "s" LPC
 SG_ RePosLi_UB : 160|1@0+ (1,0) [0|1] "" LPC
 SG_ RePosLiChks : 128|8@1+ (1.0,0.0) [0.0|255.0] "Unitless" LPC
 SG_ RePosLiCntr : 136|4@1+ (1.0,0.0) [0.0|15.0] "Unitless" LPC
 SG_ RePosLiReq : 144|2@1+ (1,0) [0|3] "" LPC
 SG_ RePosLiSlope : 146|6@1+ (0.1,0.0) [0.0|6.300000000000001] "s" LPC
 SG_ RePosLiTransition : 152|4@1+ (1.0,0.0) [0.0|15.0] "Unitless" LPC
 SG_ RevLi_UB : 184|1@0+ (1,0) [0|1] "" LPC
 SG_ RevLiReq : 185|1@0+ (1,0) [0|1] "" LPC
 SG_ RevLiSlope : 191|6@0+ (0.1,0.0) [0.0|6.300000000000001] "s" LPC
 SG_ RoadIncln_UB : 174|1@0+ (1,0) [0|1] "" LPC
 SG_ RoadInclnQly : 9|2@0+ (1,0) [0|3] "" LPC
 SG_ RoadInclnRoadIncln : 23|16@0- (0.000030518,0.0) [-0.9999833060000001|0.9999833060000001] "rad" LPC
 SG_ WasherFrontReq : 55|2@0+ (1,0) [0|3] "" LPC
 SG_ WasherFrontReq_UB : 53|1@0+ (1,0) [0|1] "" LPC
 SG_ WasherRearReq : 52|2@0+ (1,0) [0|3] "" LPC
 SG_ WasherRearReq_UB : 50|1@0+ (1,0) [0|1] "" LPC
 SG_ WiprFrntSrvModReq : 39|2@0+ (1,0) [0|3] "" LPC
 SG_ WiprFrntSrvModReq_UB : 37|1@0+ (1,0) [0|1] "" LPC
 SG_ WiprMotIntlCmd : 66|3@0+ (1,0) [0|7] "" LPC
 SG_ WiprMotIntlCmd_UB : 49|1@0+ (1,0) [0|1] "" LPC

BO_ 343 LpcdpLpc1canFr07_10ms : 48 LPCdp
 SG_ ExLiLpHdlampKoz1_UB : 7|1@0+ (1,0) [0|1] "" LPC
 SG_ ExLiLpHdlampKoz1BottomAg : 0|9@0- (0.0015,0.0) [-0.384|0.3825] "rad" LPC
 SG_ ExLiLpHdlampKoz1LeAgPrpty : 6|3@0+ (1.0,0.0) [0.0|7.0] "Unitless" LPC
 SG_ ExLiLpHdlampKoz1LeLampLeAg : 17|10@0- (0.0015,0.0) [-0.768|0.7665000000000001] "rad" LPC
 SG_ ExLiLpHdlampKoz1LeLampRiAg : 33|10@0- (0.0015,0.0) [-0.768|0.7665000000000001] "rad" LPC
 SG_ ExLiLpHdlampKoz1RiAgPrpty : 3|3@0+ (1.0,0.0) [0.0|7.0] "Unitless" LPC
 SG_ ExLiLpHdlampKoz1RiLampLeAg : 49|10@0- (0.0015,0.0) [-0.768|0.7665000000000001] "rad" LPC
 SG_ ExLiLpHdlampKoz1RiLampRiAg : 65|10@0- (0.0015,0.0) [-0.768|0.7665000000000001] "rad" LPC
 SG_ ExLiLpHdlampKoz2_UB : 87|1@0+ (1,0) [0|1] "" LPC
 SG_ ExLiLpHdlampKoz2BottomAg : 80|9@0- (0.0015,0.0) [-0.384|0.3825] "rad" LPC
 SG_ ExLiLpHdlampKoz2LeAgPrpty : 86|3@0+ (1.0,0.0) [0.0|7.0] "Unitless" LPC
 SG_ ExLiLpHdlampKoz2LeLampLeAg : 97|10@0- (0.0015,0.0) [-0.768|0.7665000000000001] "rad" LPC
 SG_ ExLiLpHdlampKoz2LeLampRiAg : 113|10@0- (0.0015,0.0) [-0.768|0.7665000000000001] "rad" LPC
 SG_ ExLiLpHdlampKoz2RiAgPrpty : 83|3@0+ (1.0,0.0) [0.0|7.0] "Unitless" LPC
 SG_ ExLiLpHdlampKoz2RiLampLeAg : 129|10@0- (0.0015,0.0) [-0.768|0.7665000000000001] "rad" LPC
 SG_ ExLiLpHdlampKoz2RiLampRiAg : 145|10@0- (0.0015,0.0) [-0.768|0.7665000000000001] "rad" LPC
 SG_ ExLiLpHdlampKoz3_UB : 167|1@0+ (1,0) [0|1] "" LPC
 SG_ ExLiLpHdlampKoz3BottomAg : 160|9@0- (0.0015,0.0) [-0.384|0.3825] "rad" LPC
 SG_ ExLiLpHdlampKoz3LeAgPrpty : 166|3@0+ (1.0,0.0) [0.0|7.0] "Unitless" LPC
 SG_ ExLiLpHdlampKoz3LeLampLeAg : 177|10@0- (0.0015,0.0) [-0.768|0.7665000000000001] "rad" LPC
 SG_ ExLiLpHdlampKoz3LeLampRiAg : 193|10@0- (0.0015,0.0) [-0.768|0.7665000000000001] "rad" LPC
 SG_ ExLiLpHdlampKoz3RiAgPrpty : 163|3@0+ (1.0,0.0) [0.0|7.0] "Unitless" LPC
 SG_ ExLiLpHdlampKoz3RiLampLeAg : 209|10@0- (0.0015,0.0) [-0.768|0.7665000000000001] "rad" LPC
 SG_ ExLiLpHdlampKoz3RiLampRiAg : 225|10@0- (0.0015,0.0) [-0.768|0.7665000000000001] "rad" LPC
 SG_ ExLiLpHdlampKoz4_UB : 247|1@0+ (1,0) [0|1] "" LPC
 SG_ ExLiLpHdlampKoz4BottomAg : 240|9@0- (0.0015,0.0) [-0.384|0.3825] "rad" LPC
 SG_ ExLiLpHdlampKoz4LeAgPrpty : 246|3@0+ (1.0,0.0) [0.0|7.0] "Unitless" LPC
 SG_ ExLiLpHdlampKoz4LeLampLeAg : 257|10@0- (0.0015,0.0) [-0.768|0.7665000000000001] "rad" LPC
 SG_ ExLiLpHdlampKoz4LeLampRiAg : 273|10@0- (0.0015,0.0) [-0.768|0.7665000000000001] "rad" LPC
 SG_ ExLiLpHdlampKoz4RiAgPrpty : 243|3@0+ (1.0,0.0) [0.0|7.0] "Unitless" LPC
 SG_ ExLiLpHdlampKoz4RiLampLeAg : 289|10@0- (0.0015,0.0) [-0.768|0.7665000000000001] "rad" LPC
 SG_ ExLiLpHdlampKoz4RiLampRiAg : 305|10@0- (0.0015,0.0) [-0.768|0.7665000000000001] "rad" LPC
 SG_ ExLiLpHdlampKoz5_UB : 327|1@0+ (1,0) [0|1] "" LPC
 SG_ ExLiLpHdlampKoz5BottomAg : 320|9@0- (0.0015,0.0) [-0.384|0.3825] "rad" LPC
 SG_ ExLiLpHdlampKoz5LeAgPrpty : 326|3@0+ (1.0,0.0) [0.0|7.0] "Unitless" LPC
 SG_ ExLiLpHdlampKoz5LeLampLeAg : 337|10@0- (0.0015,0.0) [-0.768|0.7665000000000001] "rad" LPC
 SG_ ExLiLpHdlampKoz5LeLampRiAg : 357|10@0- (0.0015,0.0) [-0.768|0.7665000000000001] "rad" LPC
 SG_ ExLiLpHdlampKoz5RiAgPrpty : 323|3@0+ (1.0,0.0) [0.0|7.0] "Unitless" LPC
 SG_ ExLiLpHdlampKoz5RiLampLeAg : 363|10@0- (0.0015,0.0) [-0.768|0.7665000000000001] "rad" LPC
 SG_ ExLiLpHdlampKoz5RiLampRiAg : 369|10@0- (0.0015,0.0) [-0.768|0.7665000000000001] "rad" LPC

BO_ 344 LpcdpLpc1canFr08_10ms : 48 LPCdp
 SG_ ExLiHpHdlampDim1_UB : 328|1@0+ (1,0) [0|1] "" LPC
 SG_ ExLiHpHdlampDim1BottomAg : 0|9@0- (0.0015,0.0) [-0.384|0.3825] "rad" LPC
 SG_ ExLiHpHdlampDim1LeAgPrpty : 3|3@0+ (1.0,0.0) [0.0|7.0] "Unitless" LPC
 SG_ ExLiHpHdlampDim1LeLampLeAg : 17|10@0- (0.0015,0.0) [-0.768|0.7665000000000001] "rad" LPC
 SG_ ExLiHpHdlampDim1LeLampRiAg : 33|10@0- (0.0015,0.0) [-0.768|0.7665000000000001] "rad" LPC
 SG_ ExLiHpHdlampDim1ObjctZoneIntens : 55|8@0+ (1.0,0.0) [0.0|255.0] "Unitless" LPC
 SG_ ExLiHpHdlampDim1RiAgPrpty : 6|3@0+ (1.0,0.0) [0.0|7.0] "Unitless" LPC
 SG_ ExLiHpHdlampDim1RiLampLeAg : 57|10@0- (0.0015,0.0) [-0.768|0.7665000000000001] "rad" LPC
 SG_ ExLiHpHdlampDim1RiLampRiAg : 73|10@0- (0.0015,0.0) [-0.768|0.7665000000000001] "rad" LPC
 SG_ ExLiHpHdlampDim2_UB : 329|1@0+ (1,0) [0|1] "" LPC
 SG_ ExLiHpHdlampDim2BottomAg : 88|9@0- (0.0015,0.0) [-0.384|0.3825] "rad" LPC
 SG_ ExLiHpHdlampDim2LeAgPrpty : 91|3@0+ (1.0,0.0) [0.0|7.0] "Unitless" LPC
 SG_ ExLiHpHdlampDim2LeLampLeAg : 105|10@0- (0.0015,0.0) [-0.768|0.7665000000000001] "rad" LPC
 SG_ ExLiHpHdlampDim2LeLampRiAg : 121|10@0- (0.0015,0.0) [-0.768|0.7665000000000001] "rad" LPC
 SG_ ExLiHpHdlampDim2ObjctZoneIntens : 143|8@0+ (1.0,0.0) [0.0|255.0] "Unitless" LPC
 SG_ ExLiHpHdlampDim2RiAgPrpty : 94|3@0+ (1.0,0.0) [0.0|7.0] "Unitless" LPC
 SG_ ExLiHpHdlampDim2RiLampLeAg : 145|10@0- (0.0015,0.0) [-0.768|0.7665000000000001] "rad" LPC
 SG_ ExLiHpHdlampDim2RiLampRiAg : 161|10@0- (0.0015,0.0) [-0.768|0.7665000000000001] "rad" LPC
 SG_ ExLiHpHdlampDim3_UB : 330|1@0+ (1,0) [0|1] "" LPC
 SG_ ExLiHpHdlampDim3BottomAg : 176|9@0- (0.0015,0.0) [-0.384|0.3825] "rad" LPC
 SG_ ExLiHpHdlampDim3LeAgPrpty : 179|3@0+ (1.0,0.0) [0.0|7.0] "Unitless" LPC
 SG_ ExLiHpHdlampDim3LeLampLeAg : 193|10@0- (0.0015,0.0) [-0.768|0.7665000000000001] "rad" LPC
 SG_ ExLiHpHdlampDim3LeLampRiAg : 209|10@0- (0.0015,0.0) [-0.768|0.7665000000000001] "rad" LPC
 SG_ ExLiHpHdlampDim3ObjctZoneIntens : 231|8@0+ (1.0,0.0) [0.0|255.0] "Unitless" LPC
 SG_ ExLiHpHdlampDim3RiAgPrpty : 182|3@0+ (1.0,0.0) [0.0|7.0] "Unitless" LPC
 SG_ ExLiHpHdlampDim3RiLampLeAg : 233|10@0- (0.0015,0.0) [-0.768|0.7665000000000001] "rad" LPC
 SG_ ExLiHpHdlampDim3RiLampRiAg : 249|10@0- (0.0015,0.0) [-0.768|0.7665000000000001] "rad" LPC
 SG_ ExLiLpHdlampCornLe_UB : 331|1@0+ (1,0) [0|1] "" LPC
 SG_ ExLiLpHdlampCornLeFocus : 268|4@0+ (1.0,0.0) [0.0|15.0] "Unitless" LPC
 SG_ ExLiLpHdlampCornLeReq : 269|1@0+ (1,0) [0|1] "" LPC
 SG_ ExLiLpHdlampCornLeSlope : 264|9@0+ (0.01,0.0) [0.0|5.11] "s" LPC
 SG_ ExLiLpHdlampCornRi_UB : 332|1@0+ (1,0) [0|1] "" LPC
 SG_ ExLiLpHdlampCornRiFocus : 284|4@0+ (1.0,0.0) [0.0|15.0] "Unitless" LPC
 SG_ ExLiLpHdlampCornRiReq : 285|1@0+ (1,0) [0|1] "" LPC
 SG_ ExLiLpHdlampCornRiSlope : 280|9@0+ (0.01,0.0) [0.0|5.11] "s" LPC
 SG_ ExLiLpHdlampHozlLe_UB : 333|1@0+ (1,0) [0|1] "" LPC
 SG_ ExLiLpHdlampHozlLeHozlLeEna : 301|1@0+ (1,0) [0|1] "" LPC
 SG_ ExLiLpHdlampHozlLeHozlLeMotSply : 302|1@0+ (1,0) [0|1] "" LPC
 SG_ ExLiLpHdlampHozlLeHozlLeRefForce : 300|1@0+ (1,0) [0|1] "" LPC
 SG_ ExLiLpHdlampHozlLeHozlLeRefOk : 299|1@0+ (1,0) [0|1] "" LPC
 SG_ ExLiLpHdlampHozlLeHozlLeReq : 298|11@0+ (0.0004,-0.4094) [-0.4094|0.4094000000000001] "rad" LPC
 SG_ ExLiLpHdlampHozlRi_UB : 334|1@0+ (1,0) [0|1] "" LPC
 SG_ ExLiLpHdlampHozlRiHozlRiEna : 317|1@0+ (1,0) [0|1] "" LPC
 SG_ ExLiLpHdlampHozlRiHozlRiMotSply : 318|1@0+ (1,0) [0|1] "" LPC
 SG_ ExLiLpHdlampHozlRiHozlRiRefForce : 316|1@0+ (1,0) [0|1] "" LPC
 SG_ ExLiLpHdlampHozlRiHozlRiRefOk : 315|1@0+ (1,0) [0|1] "" LPC
 SG_ ExLiLpHdlampHozlRiHozlRiReq : 314|11@0+ (0.0004,-0.4094) [-0.4094|0.4094000000000001] "rad" LPC

BO_ 345 LpcdpLpc1canFr09_10ms : 48 LPCdp
 SG_ ExLiHpTurnIndcrLiReq_UB : 288|1@0+ (1,0) [0|1] "" LPC
 SG_ ExLiHpTurnIndcrLiReqActivePeriodTime : 216|16@1+ (1.0,0.0) [0.0|65535.0] "Unitless" LPC
 SG_ ExLiHpTurnIndcrLiReqChks : 0|16@1+ (1.0,0.0) [0.0|65535.0] "Unitless" LPC
 SG_ ExLiHpTurnIndcrLiReqCntr : 16|8@1+ (1.0,0.0) [0.0|255.0] "Unitless" LPC
 SG_ ExLiHpTurnIndcrLiReqDirection : 264|3@1+ (1,0) [0|7] "" LPC
 SG_ ExLiHpTurnIndcrLiReqInactivePeriodTime : 232|16@1+ (1.0,0.0) [0.0|65535.0] "Unitless" LPC
 SG_ ExLiHpTurnIndcrLiReqIndcrSeqDownTi : 248|8@1+ (0.01,0.0) [0.0|2.5500000000000003] "s" LPC
 SG_ ExLiHpTurnIndcrLiReqIndcrSeqUpTi : 256|8@1+ (0.01,0.0) [0.0|2.5500000000000003] "s" LPC
 SG_ ExLiHpTurnIndcrLiReqSlopeDwnTi : 272|6@1+ (0.1,0.0) [0.0|6.300000000000001] "s" LPC
 SG_ ExLiHpTurnIndcrLiReqSlopeUpTi : 280|6@1+ (0.1,0.0) [0.0|6.300000000000001] "s" LPC
 SG_ ExLiHpTurnIndcrLiReqSyncOffTiNanoS : 24|32@1+ (1.0,0.0) [0.0|4294967295.0] "Unitless" LPC
 SG_ ExLiHpTurnIndcrLiReqSyncOffTiS : 56|64@1+ (1.0,0.0) [0.0|604799999.0] "Unitless" LPC
 SG_ ExLiHpTurnIndcrLiReqSyncOnTiNanS : 120|32@1+ (1.0,0.0) [0.0|4294967295.0] "Unitless" LPC
 SG_ ExLiHpTurnIndcrLiReqSyncOnTiS : 152|64@1+ (1.0,0.0) [0.0|604799999.0] "Unitless" LPC
 SG_ ExLiHpTurnIndcrLiReqTransition : 267|4@1+ (1.0,0.0) [0.0|15.0] "Unitless" LPC

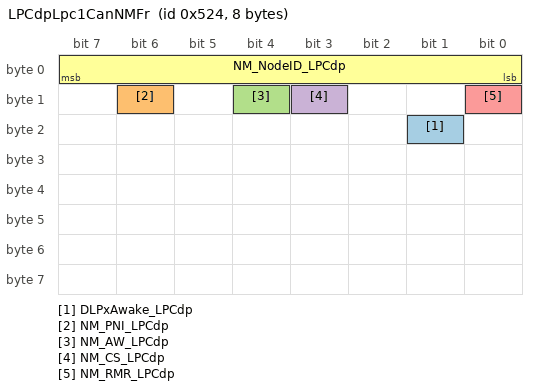
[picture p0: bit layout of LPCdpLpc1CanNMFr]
BO_ 1316 LPCdpLpc1CanNMFr : 8 LPCdp
 SG_ DLPxAwake_LPCdp : 17|1@0+ (1,0) [0|0] "" LPC
 SG_ NM_PNI_LPCdp : 14|1@0+ (1,0) [0|0] "" LPC
 SG_ NM_AW_LPCdp : 12|1@0+ (1,0) [0|0] "" LPC
 SG_ NM_CS_LPCdp : 11|1@0+ (1,0) [0|0] "" LPC
 SG_ NM_RMR_LPCdp : 8|1@0+ (1,0) [0|0] "" LPC
 SG_ NM_NodeID_LPCdp : 7|8@0+ (1,0) [0|0] "" LPC

// Node Comments
CM_ BU_ LPC "Low Power Controller";
CM_ BU_ LPCdp "LPCdp - Low Power Controller device proxy";

// Signal Comments
CM_ SG_ 336 BltRmnTelltl "Trigger for when the safety belt reminder telltale in the OHC shall be lit";
CM_ SG_ 336 ChdProtnActvnReqDoorDrvrRe "Child protection on/off for driver door rear";
CM_ SG_ 336 ChdProtnActvnReqDoorPass "Child protection on/off for passenger door";
CM_ SG_ 336 ChdProtnActvnReqDoorPassRe "Child protection on/off for passenger door rear";
CM_ SG_ 336 DynCfgStrWhlPosnForUSS "Steering Wheel position";
CM_ SG_ 336 DynCfgVehTypForUSS "Vehicle Type";
CM_ SG_ 336 FwdLookCamHeatingReq "Heating request from VCU";
CM_ SG_ 336 GlvBoxRelsBtnPsd "Button status to release glovebox.

NotPsd - No request to open
Psd - Request to open";
CM_ SG_ 336 LcmaIndcnPass "Indicates if a  LCMA warning shall be shown to the driver or not.";
CM_ SG_ 336 LockgExtReqLockActv "Locking command";
CM_ SG_ 336 LockgExtReqLockDly "Lock delay";
CM_ SG_ 336 LockgExtReqLockRep "Lock repeat";
CM_ SG_ 336 LockgPrsnlReq "Activation and deactivation of private locking.";
CM_ SG_ 336 LockgSetgFbAudibleFeedback "Audible lock/unlock feedback";
CM_ SG_ 336 LockgSetgFbVisibleFeedback "Visible lock/unlock feedback";
CM_ SG_ 336 LockgSetgPasLockBySpeed "Automatic locking by speed";
CM_ SG_ 336 LockgSetgPasLockWalkAway "Walk away locking";
CM_ SG_ 336 LockgSetgPasUnlockApproach "Unlock at approach";
CM_ SG_ 336 LockgSetgSngDoorUnlck "Setting for single door unlock";
CM_ SG_ 336 MirrCmdRecAtDrvrMirrFoldCmd "Mirror fold command";
CM_ SG_ 336 MirrCmdRecAtDrvrMirrPosAdjCmd "Mirror position Adjustment command";
CM_ SG_ 336 MirrCmdRecAtPassMirrFoldCmd "Mirror fold command";
CM_ SG_ 336 MirrCmdRecAtPassMirrPosAdjCmd "Mirror position Adjustment command";
CM_ SG_ 336 MirrorFuncCarCfgExtRearViewMirrorType "The exterior rear view mirror type";
CM_ SG_ 336 MirrorFuncCarCfgRearViewMirrorDimType "Inner and outer mirror dimming charecteristic";
CM_ SG_ 336 MirrorFuncCarCfgRearViewMirrorMemType "Indicates whether or not vehicle is equipped with memory in rear view mirrors.";
CM_ SG_ 336 MirrPosnSensTrgtValDrvrMirrSensXPos " sensor value of X axis";
CM_ SG_ 336 MirrPosnSensTrgtValDrvrMirrSensYPos "sensor value of Y axis";
CM_ SG_ 336 MirrPosnSensTrgtValPassMirrSensXPos " sensor value of X axis";
CM_ SG_ 336 MirrPosnSensTrgtValPassMirrSensYPos "sensor value of Y axis";
CM_ SG_ 336 TrlrLampChkReq "Distribution of trailer lamp check activation from DIM
";
CM_ SG_ 336 TrOpenerBtnAcvtnReq "Request from button to open, close or stop tailgate";
CM_ SG_ 336 TwbrFoldFromHMI "Signal to fold in/out towbar from HMI";
CM_ SG_ 336 TwliBriSts "Day/night status signal. ";
CM_ SG_ 336 VehAlrmExtReq "Requests from VCU application to LPC for the alarm.";
CM_ SG_ 336 VehAlrmPasDeactvnReq "Passive arming deactivated";
CM_ SG_ 336 VehAlrmRednSts "Indicates if reduced guard for alarm is the chosen setting.";
CM_ SG_ 336 WindowsFuncCarCfgPinchProtectionLvl "To represent if the car is to be sold at a market where pinch protection legal requirements, such as FMVSS188:S5, are applicable.";
CM_ SG_ 336 WindowsFuncCarCfgReserved0 "reseved for future";
CM_ SG_ 336 WindowsFuncCarCfgTailgateWindowTintType "To be able to compensate the dimming of the rear view mirrors the Mirror Autodimming system needs to know tinting properties of the tailgate window.";
CM_ SG_ 336 WindowsFuncCarCfgWindowsGlassType "For the door control units to calibrate their pinch protection for the windows they need to know the window glass type.";
CM_ SG_ 338 BltLockStDrvr "Driver Belt Status";
CM_ SG_ 338 CarModeSyncCarMode "Car mode in SPA2";
CM_ SG_ 338 CarModeSyncCarModeSubtype "Substate for current carmode";
CM_ SG_ 338 GearLvlIndcn "Gear Level Status for interior light control.";
CM_ SG_ 338 IntrLiUsrPrsntDrvrSeat "Front Driver Seat";
CM_ SG_ 338 IntrLiUsrPrsntPassSeat "Front Passenger Seat ";
CM_ SG_ 338 IntrLiUsrPrsntReCentrSeat2nd "Rear Center Seat 2nd row";
CM_ SG_ 338 IntrLiUsrPrsntReDrvrSeat2nd "Rear Driver Seat 2nd row";
CM_ SG_ 338 IntrLiUsrPrsntReDrvrSeat3nd "Rear Driver Seat 3nd row";
CM_ SG_ 338 IntrLiUsrPrsntRePassSeat2nd "Rear Passenger Seat 2nd row";
CM_ SG_ 338 IntrLiUsrPrsntRePassSeat3nd "Rear Passenger Seat 3nd row";
CM_ SG_ 338 IntrLiUsrPrsntTrAr "Trunk Area";
CM_ SG_ 338 PinionAgPinionSteerAg1 "Calculated pinion steer angle at the front steering device";
CM_ SG_ 338 PinionAgPinionSteerAg1Qf "Quality factor for PinionSteerAg1";
CM_ SG_ 338 PowerControllerRlySyncADPMWakeUpSync "ADPM wake up  from VCU to LPC";
CM_ SG_ 338 PowerControllerRlySyncAUDWakeUpSync "AUD wake up  from VCU to LPC";
CM_ SG_ 338 PowerControllerRlySyncChks "Checksum check";
CM_ SG_ 338 PowerControllerRlySyncClimateActuatorRelaySync "ClimateActuatorRelay from VCU to LPC";
CM_ SG_ 338 PowerControllerRlySyncCntr "Check Counter";
CM_ SG_ 338 PowerControllerRlySyncDIMWakeUpSync "DIM wake up  from VCU to LPC";
CM_ SG_ 338 PowerControllerRlySyncExteriorLightRelaySync "Exterior Light Relay  from VCU to LPC";
CM_ SG_ 338 PowerControllerRlySyncIgnitionPowerRelaySync "Ignition Power Relay  from VCU to LPC";
CM_ SG_ 338 PowerControllerRlySyncSUMWakeUpSync "SUM wake up  from VCU to LPC";
CM_ SG_ 338 VehModMngmntSigDCUCarModeSts "Vehicle Car Mode Type";
CM_ SG_ 338 VehModMngmntSigDCUCarModeSubType "CarMode Sub type";
CM_ SG_ 338 VehModMngmntSigDCUElecEnergyLvlDCU "DifferentEnergyLevelOfVehicle";
CM_ SG_ 338 VehModMngmntSigDCUElecPowerLvlDCU "DifferentPowerLevelsOftheVehicle";
CM_ SG_ 338 VehModMngmntSigDCUReserved1 "Reserved for future use";
CM_ SG_ 338 VehModMngmntSigDCUReserved2 "Reserved for future use";
CM_ SG_ 338 VehModMngmntSigDCUUsageModeSts "UsageMode for DCU send from VCU";
CM_ SG_ 340 ExLiLpHiDefZone1BottomAg "Bottom Angle";
CM_ SG_ 340 ExLiLpHiDefZone1GradWdth "Width gradient of KOZ  for HD module";
CM_ SG_ 340 ExLiLpHiDefZone1LeAgPrpty "Left angle object type";
CM_ SG_ 340 ExLiLpHiDefZone1LeLampLeAg "Left Lamp Left Angle";
CM_ SG_ 340 ExLiLpHiDefZone1LeLampRiAg "Left Lamp Right Angle";
CM_ SG_ 340 ExLiLpHiDefZone1ObjctZoneIntens "Intensity level within an object Zone. 255 = 100%, 0 = 0% light intensity ";
CM_ SG_ 340 ExLiLpHiDefZone1RiAgPrpty "Right angle object type";
CM_ SG_ 340 ExLiLpHiDefZone1RiLampLeAg "Right Lamp Left Angle";
CM_ SG_ 340 ExLiLpHiDefZone1RiLampRiAg "Right Lamp Right Angle";
CM_ SG_ 340 ExLiLpHiDefZone1TopAg "Top Angle";
CM_ SG_ 340 ExLiLpHiDefZone2BottomAg "Bottom Angle";
CM_ SG_ 340 ExLiLpHiDefZone2GradWdth "Width gradient of KOZ  for HD module";
CM_ SG_ 340 ExLiLpHiDefZone2LeAgPrpty "Left angle object type";
CM_ SG_ 340 ExLiLpHiDefZone2LeLampLeAg "Left Lamp Left Angle";
CM_ SG_ 340 ExLiLpHiDefZone2LeLampRiAg "Left Lamp Right Angle";
CM_ SG_ 340 ExLiLpHiDefZone2ObjctZoneIntens "Intensity level within an object Zone. 255 = 100%, 0 = 0% light intensity ";
CM_ SG_ 340 ExLiLpHiDefZone2RiAgPrpty "Right angle object type";
CM_ SG_ 340 ExLiLpHiDefZone2RiLampLeAg "Right Lamp Left Angle";
CM_ SG_ 340 ExLiLpHiDefZone2RiLampRiAg "Right Lamp Right Angle";
CM_ SG_ 340 ExLiLpHiDefZone2TopAg "Top Angle";
CM_ SG_ 340 ExLiLpHiDefZone3BottomAg "Bottom Angle";
CM_ SG_ 340 ExLiLpHiDefZone3GradWdth "Width gradient of KOZ  for HD module";
CM_ SG_ 340 ExLiLpHiDefZone3LeAgPrpty "Left angle object type";
CM_ SG_ 340 ExLiLpHiDefZone3LeLampLeAg "Left Lamp Left Angle";
CM_ SG_ 340 ExLiLpHiDefZone3LeLampRiAg "Left Lamp Right Angle";
CM_ SG_ 340 ExLiLpHiDefZone3ObjctZoneIntens "Intensity level within an object Zone. 255 = 100%, 0 = 0% light intensity ";
CM_ SG_ 340 ExLiLpHiDefZone3RiAgPrpty "Right angle object type";
CM_ SG_ 340 ExLiLpHiDefZone3RiLampLeAg "Right Lamp Left Angle";
CM_ SG_ 340 ExLiLpHiDefZone3RiLampRiAg "Right Lamp Right Angle";
CM_ SG_ 340 ExLiLpHiDefZone3TopAg "Top Angle";
CM_ SG_ 340 ExLiLpHiDefZone4BottomAg "Bottom Angle";
CM_ SG_ 340 ExLiLpHiDefZone4GradWdth "Width gradient of KOZ  for HD module";
CM_ SG_ 340 ExLiLpHiDefZone4LeAgPrpty "Left angle object type";
CM_ SG_ 340 ExLiLpHiDefZone4LeLampLeAg "Left Lamp Left Angle";
CM_ SG_ 340 ExLiLpHiDefZone4LeLampRiAg "Left Lamp Right Angle";
CM_ SG_ 340 ExLiLpHiDefZone4ObjctZoneIntens "Intensity level within an object Zone. 255 = 100%, 0 = 0% light intensity ";
CM_ SG_ 340 ExLiLpHiDefZone4RiAgPrpty "Right angle object type";
CM_ SG_ 340 ExLiLpHiDefZone4RiLampLeAg "Right Lamp Left Angle";
CM_ SG_ 340 ExLiLpHiDefZone4RiLampRiAg "Right Lamp Right Angle";
CM_ SG_ 340 ExLiLpHiDefZone4TopAg "Top Angle";
CM_ SG_ 340 ExLiLpHiDefZone5BottomAg "Bottom Angle";
CM_ SG_ 340 ExLiLpHiDefZone5GradWdth "Width gradient of KOZ  for HD module";
CM_ SG_ 340 ExLiLpHiDefZone5LeAgPrpty "Left angle object type";
CM_ SG_ 340 ExLiLpHiDefZone5LeLampLeAg "Left Lamp Left Angle";
CM_ SG_ 340 ExLiLpHiDefZone5LeLampRiAg "Left Lamp Right Angle";
CM_ SG_ 340 ExLiLpHiDefZone5ObjctZoneIntens "Intensity level within an object Zone. 255 = 100%, 0 = 0% light intensity ";
CM_ SG_ 340 ExLiLpHiDefZone5RiAgPrpty "Right angle object type";
CM_ SG_ 340 ExLiLpHiDefZone5RiLampLeAg "Right Lamp Left Angle";
CM_ SG_ 340 ExLiLpHiDefZone5RiLampRiAg "Right Lamp Right Angle";
CM_ SG_ 340 ExLiLpHiDefZone5TopAg "Top Angle";
CM_ SG_ 341 ExLiLpHiDefHozlLeDLPHozlLeEna "swiveling enable";
CM_ SG_ 341 ExLiLpHiDefHozlLeDLPHozlLeReq "DLP swiveling";
CM_ SG_ 341 ExLiLpHiDefHozlRiDLPHozlRiEna "swiveling enable";
CM_ SG_ 341 ExLiLpHiDefHozlRiDLPHozlRiReq "DLP swiveling";
CM_ SG_ 341 ExLiLpHiDefLiLeDLPLeShape "Request of DLP beam shape";
CM_ SG_ 341 ExLiLpHiDefLiLeDLPLeSlope "Request of beam shape dimming duration";
CM_ SG_ 341 ExLiLpHiDefLiLeDLPLeTransition "Transition behaviour when changing beam shape. E.g. animated 'curtains'";
CM_ SG_ 341 ExLiLpHiDefLiLeTrafficSide "Provides information on what traffic side it is.";
CM_ SG_ 341 ExLiLpHiDefLiRiDLPRiShape "Request of DLP beam shape";
CM_ SG_ 341 ExLiLpHiDefLiRiDLPRiSlope "Request of beam shape dimming duration";
CM_ SG_ 341 ExLiLpHiDefLiRiDLPRiTransition "Transition behaviour when changing beam shape. E.g. animated 'curtains'";
CM_ SG_ 341 ExLiLpHiDefLiRiTrafficSide "Provides information on what traffic side it is.";
CM_ SG_ 341 ExLiLpHiDefZone6BottomAg "Bottom Angle";
CM_ SG_ 341 ExLiLpHiDefZone6GradWdth "Width gradient of KOZ  for HD module";
CM_ SG_ 341 ExLiLpHiDefZone6LeAgPrpty "Left angle object type";
CM_ SG_ 341 ExLiLpHiDefZone6LeLampLeAg "Left Lamp Left Angle";
CM_ SG_ 341 ExLiLpHiDefZone6LeLampRiAg "Left Lamp Right Angle";
CM_ SG_ 341 ExLiLpHiDefZone6ObjctZoneIntens "Intensity level within an object Zone. 255 = 100%, 0 = 0% light intensity ";
CM_ SG_ 341 ExLiLpHiDefZone6RiAgPrpty "Right angle object type";
CM_ SG_ 341 ExLiLpHiDefZone6RiLampLeAg "Right Lamp Left Angle";
CM_ SG_ 341 ExLiLpHiDefZone6RiLampRiAg "Right Lamp Right Angle";
CM_ SG_ 341 ExLiLpHiDefZone6TopAg "Top Angle";
CM_ SG_ 341 ExLiLpHiDefZone7BottomAg "Bottom Angle";
CM_ SG_ 341 ExLiLpHiDefZone7GradWdth "Width gradient of KOZ  for HD module";
CM_ SG_ 341 ExLiLpHiDefZone7LeAgPrpty "Left angle object type";
CM_ SG_ 341 ExLiLpHiDefZone7LeLampLeAg "Left Lamp Left Angle";
CM_ SG_ 341 ExLiLpHiDefZone7LeLampRiAg "Left Lamp Right Angle";
CM_ SG_ 341 ExLiLpHiDefZone7ObjctZoneIntens "Intensity level within an object Zone. 255 = 100%, 0 = 0% light intensity ";
CM_ SG_ 341 ExLiLpHiDefZone7RiAgPrpty "Right angle object type";
CM_ SG_ 341 ExLiLpHiDefZone7RiLampLeAg "Right Lamp Left Angle";
CM_ SG_ 341 ExLiLpHiDefZone7RiLampRiAg "Right Lamp Right Angle";
CM_ SG_ 341 ExLiLpHiDefZone7TopAg "Top Angle";
CM_ SG_ 341 ExLiLpHiDefZone8BottomAg "Bottom Angle";
CM_ SG_ 341 ExLiLpHiDefZone8GradWdth "Width gradient of KOZ  for HD module";
CM_ SG_ 341 ExLiLpHiDefZone8LeAgPrpty "Left angle object type";
CM_ SG_ 341 ExLiLpHiDefZone8LeLampLeAg "Left Lamp Left Angle";
CM_ SG_ 341 ExLiLpHiDefZone8LeLampRiAg "Left Lamp Right Angle";
CM_ SG_ 341 ExLiLpHiDefZone8ObjctZoneIntens "Intensity level within an object Zone. 255 = 100%, 0 = 0% light intensity ";
CM_ SG_ 341 ExLiLpHiDefZone8RiAgPrpty "Right angle object type";
CM_ SG_ 341 ExLiLpHiDefZone8RiLampLeAg "Right Lamp Left Angle";
CM_ SG_ 341 ExLiLpHiDefZone8RiLampRiAg "Right Lamp Right Angle";
CM_ SG_ 341 ExLiLpHiDefZone8TopAg "Top Angle";
CM_ SG_ 342 DoorModuleCarCfgDDMMountInfo "Driver Door mount information";
CM_ SG_ 342 DoorModuleCarCfgPDMMountInfo "PassengerDoor  mounted information";
CM_ SG_ 342 DoorModuleCarCfgRDDMMountInfo "RearDriverDoor mount information";
CM_ SG_ 342 DoorModuleCarCfgRPDMMountInfo "RearPassengerDoor Mounted information";
CM_ SG_ 342 ExLiHpHdlampConcealLeChks "Checksum";
CM_ SG_ 342 ExLiHpHdlampConcealLeCntr "Counter";
CM_ SG_ 342 ExLiHpHdlampConcealLeEna "Head lamp concealment device enabled/disabled";
CM_ SG_ 342 ExLiHpHdlampConcealLeMotSply "Head lamp concealment device stepper motor hold current ON/OFF";
CM_ SG_ 342 ExLiHpHdlampConcealLePosnReq "Head lamp concealment device opening or closing request";
CM_ SG_ 342 ExLiHpHdlampConcealLeRefForce "Head lamp concealment device forced reference run";
CM_ SG_ 342 ExLiHpHdlampConcealLeRefOk "Head lamp concealment device reference run allowed/ not allowed";
CM_ SG_ 342 ExLiHpHdlampConcealLeSpd "Head lamp concealment device opening or closing speed";
CM_ SG_ 342 ExLiHpHdlampConcealRiChks "Checksum";
CM_ SG_ 342 ExLiHpHdlampConcealRiCntr "Counter";
CM_ SG_ 342 ExLiHpHdlampConcealRiEna "Head lamp concealment device enabled/disabled";
CM_ SG_ 342 ExLiHpHdlampConcealRiMotSply "Head lamp concealment device stepper motor hold current ON/OFF";
CM_ SG_ 342 ExLiHpHdlampConcealRiPosnReq "Head lamp concealment device opening or closing request";
CM_ SG_ 342 ExLiHpHdlampConcealRiRefForce "Head lamp concealment device forced reference run";
CM_ SG_ 342 ExLiHpHdlampConcealRiRefOk "Head lamp concealment device reference run allowed/ not allowed";
CM_ SG_ 342 ExLiHpHdlampConcealRiSpd "Head lamp concealment device opening or closing speed";
CM_ SG_ 342 ExLiHpHdlampDrlPosLeFocus "Light intensity adjustment daytime running light and position light";
CM_ SG_ 342 ExLiHpHdlampDrlPosLeShape "Request for turning on or off day time running light and position light";
CM_ SG_ 342 ExLiHpHdlampDrlPosLeSlope "Request for dimming of daytime running light and position light";
CM_ SG_ 342 ExLiHpHdlampDrlPosLeTransition "Transition patterns of daytime running light and position light";
CM_ SG_ 342 ExLiHpHdlampDrlPosRiFocus "Light intensity adjustment daytime running light and position light";
CM_ SG_ 342 ExLiHpHdlampDrlPosRiShape "Request for turning on or off day time running light and position light";
CM_ SG_ 342 ExLiHpHdlampDrlPosRiSlope "Request for dimming of daytime running light and position light";
CM_ SG_ 342 ExLiHpHdlampDrlPosRiTransition "Transition patterns of daytime running light and position light";
CM_ SG_ 342 ExLiHpHdlampSmlLeSideMkrLe "Turning on or off the Side Marker light";
CM_ SG_ 342 ExLiHpHdlampSmlLeSideMkrLeFocus "Adjustment of light intensity";
CM_ SG_ 342 ExLiHpHdlampSmlLeSideMkrLeSlope "Request dimming of side marker light";
CM_ SG_ 342 ExLiHpHdlampSmlRiSideMkrRi "Turning on or off the Side Marker light";
CM_ SG_ 342 ExLiHpHdlampSmlRiSideMkrRiFocus "Adjustment of light intensity";
CM_ SG_ 342 ExLiHpHdlampSmlRiSideMkrRiSlope "Request dimming of side marker light";
CM_ SG_ 342 ExLiHpHiDefCalibrationStsLe "HD calibration status. ";
CM_ SG_ 342 ExLiHpHiDefCalibrationStsRi "HD calibration status right. ";
CM_ SG_ 342 ExLiHpTrlrLiActvnBrk "Request brake light on or off";
CM_ SG_ 342 ExLiHpTrlrLiActvnFog "Request fog light on or off";
CM_ SG_ 342 ExLiHpTrlrLiActvnPosn "Request position light on or off";
CM_ SG_ 342 ExLiHpTrlrLiActvnRvsg "Request reverse light on or off";
CM_ SG_ 342 ExLiLpHdlampLiLeBeamLeFocus "focus mode (light intesnity distrubution) as adjustment of beamshape; country road/town light etc.";
CM_ SG_ 342 ExLiLpHdlampLiLeBeamLeShape "Request for Pixel Beam Shapes.";
CM_ SG_ 342 ExLiLpHdlampLiLeBeamLeSlope "Request of Beam shape dimming duration";
CM_ SG_ 342 ExLiLpHdlampLiLeBeamLeSymbol "Request for Symbol";
CM_ SG_ 342 ExLiLpHdlampLiLeBeamLeTransition "Transition behaviour (e.g. 'animation') when changing beam shape. ";
CM_ SG_ 342 ExLiLpHdlampLiLeHeadlampLeChks "Checksum";
CM_ SG_ 342 ExLiLpHdlampLiLeHeadlampLeCntr "Counter";
CM_ SG_ 342 ExLiLpHdlampLiLeLiTrfcSide "Provides information on what traffic side it is ";
CM_ SG_ 342 ExLiLpHdlampLiRiBeamRiFocus "focus mode (light intesnity distrubution) as adjustment of beamshape; country road/town light etc.";
CM_ SG_ 342 ExLiLpHdlampLiRiBeamRiShape "Request for Pixel Beam Shapes.";
CM_ SG_ 342 ExLiLpHdlampLiRiBeamRiSlope "Request of Beam shape dimming duration";
CM_ SG_ 342 ExLiLpHdlampLiRiBeamRiSymbol "Request for Symbol";
CM_ SG_ 342 ExLiLpHdlampLiRiBeamRiTransition "Transition behaviour (e.g. 'animation') when changing beam shape. ";
CM_ SG_ 342 ExLiLpHdlampLiRiHeadlampRiChks "Checksum";
CM_ SG_ 342 ExLiLpHdlampLiRiHeadlampRiCntr "Counter";
CM_ SG_ 342 ExLiLpHdlampLiRiLiTrfcSide "Provides information on what traffic side it is ";
CM_ SG_ 342 ExLiLpHdlampLvlLeLvlLeChks "Checksum";
CM_ SG_ 342 ExLiLpHdlampLvlLeLvlLeCntr "Counter";
CM_ SG_ 342 ExLiLpHdlampLvlLeLvlLeEna "Head lamp leveling enable";
CM_ SG_ 342 ExLiLpHdlampLvlLeLvlLeMotSply "Head lamp leveling motor supply";
CM_ SG_ 342 ExLiLpHdlampLvlLeLvlLeRefForce "Head lamp forced reference run";
CM_ SG_ 342 ExLiLpHdlampLvlLeLvlLeRefOk "Head lamp leveling reference run allowed";
CM_ SG_ 342 ExLiLpHdlampLvlLeLvlLeReq "Head lamp leveling angle request";
CM_ SG_ 342 ExLiLpHdlampLvlRiLvlRiChks "Checksum";
CM_ SG_ 342 ExLiLpHdlampLvlRiLvlRiCntr "Counter";
CM_ SG_ 342 ExLiLpHdlampLvlRiLvlRiEna "Head lamp leveling enable";
CM_ SG_ 342 ExLiLpHdlampLvlRiLvlRiMotSply "Head lamp leveling motor supply";
CM_ SG_ 342 ExLiLpHdlampLvlRiLvlRiRefForce "Head lamp forced reference run";
CM_ SG_ 342 ExLiLpHdlampLvlRiLvlRiRefOk "Head lamp leveling reference run allowed";
CM_ SG_ 342 ExLiLpHdlampLvlRiLvlRiReq "Head lamp leveling angle request";
CM_ SG_ 342 FrntWhlAgFrntWhlAg "Current Angle of Front Wheel";
CM_ SG_ 342 FrntWhlAgMaxWhlAg "Maximum Wheel Angle as per current configuration";
CM_ SG_ 342 LCMACarCfgBlisInfoSys "BLIND SPOT INFORMATION SYSTEM";
CM_ SG_ 342 ReFogLiIntensity "Percentage of intensity";
CM_ SG_ 342 ReFogLiReq "Request for Fog Light";
CM_ SG_ 342 ReFogLiSlope "Slope time";
CM_ SG_ 342 RegLiReq "Request On or Off";
CM_ SG_ 342 RegLiSlope "Sets slope time";
CM_ SG_ 342 RePosLiChks "Check Sum";
CM_ SG_ 342 RePosLiCntr "Counter";
CM_ SG_ 342 RePosLiReq "Request Type For position Lights";
CM_ SG_ 342 RePosLiSlope "Ramping Request for position Light";
CM_ SG_ 342 RePosLiTransition "Pattern Requested on Position Light";
CM_ SG_ 342 RevLiReq "Request On or Off";
CM_ SG_ 342 RevLiSlope "Sets slope time";
CM_ SG_ 342 RoadInclnQly "Quality information for road inclination";
CM_ SG_ 342 RoadInclnRoadIncln "Road inclination";
CM_ SG_ 342 WiprFrntSrvModReq "Control of the windscreen wiper service position.
";
CM_ SG_ 342 WiprMotIntlCmd "Interval/rain sensor rensitivity ring setting on the wiper stalk as selected by the driver.";
CM_ SG_ 343 ExLiLpHdlampKoz1BottomAg "Bottom Angle";
CM_ SG_ 343 ExLiLpHdlampKoz1LeAgPrpty "Left angle object type";
CM_ SG_ 343 ExLiLpHdlampKoz1LeLampLeAg "Left Lamp Left Angle";
CM_ SG_ 343 ExLiLpHdlampKoz1LeLampRiAg "Left Lamp Right Angle";
CM_ SG_ 343 ExLiLpHdlampKoz1RiAgPrpty "Right angle object type";
CM_ SG_ 343 ExLiLpHdlampKoz1RiLampLeAg "Right Lamp Left Angle";
CM_ SG_ 343 ExLiLpHdlampKoz1RiLampRiAg "Right Lamp Right Angle";
CM_ SG_ 343 ExLiLpHdlampKoz2BottomAg "Bottom Angle";
CM_ SG_ 343 ExLiLpHdlampKoz2LeAgPrpty "Left angle object type";
CM_ SG_ 343 ExLiLpHdlampKoz2LeLampLeAg "Left Lamp Left Angle";
CM_ SG_ 343 ExLiLpHdlampKoz2LeLampRiAg "Left Lamp Right Angle";
CM_ SG_ 343 ExLiLpHdlampKoz2RiAgPrpty "Right angle object type";
CM_ SG_ 343 ExLiLpHdlampKoz2RiLampLeAg "Right Lamp Left Angle";
CM_ SG_ 343 ExLiLpHdlampKoz2RiLampRiAg "Right Lamp Right Angle";
CM_ SG_ 343 ExLiLpHdlampKoz3BottomAg "Bottom Angle";
CM_ SG_ 343 ExLiLpHdlampKoz3LeAgPrpty "Left angle object type";
CM_ SG_ 343 ExLiLpHdlampKoz3LeLampLeAg "Left Lamp Left Angle";
CM_ SG_ 343 ExLiLpHdlampKoz3LeLampRiAg "Left Lamp Right Angle";
CM_ SG_ 343 ExLiLpHdlampKoz3RiAgPrpty "Right angle object type";
CM_ SG_ 343 ExLiLpHdlampKoz3RiLampLeAg "Right Lamp Left Angle";
CM_ SG_ 343 ExLiLpHdlampKoz3RiLampRiAg "Right Lamp Right Angle";
CM_ SG_ 343 ExLiLpHdlampKoz4BottomAg "Bottom Angle";
CM_ SG_ 343 ExLiLpHdlampKoz4LeAgPrpty "Left angle object type";
CM_ SG_ 343 ExLiLpHdlampKoz4LeLampLeAg "Left Lamp Left Angle";
CM_ SG_ 343 ExLiLpHdlampKoz4LeLampRiAg "Left Lamp Right Angle";
CM_ SG_ 343 ExLiLpHdlampKoz4RiAgPrpty "Right angle object type";
CM_ SG_ 343 ExLiLpHdlampKoz4RiLampLeAg "Right Lamp Left Angle";
CM_ SG_ 343 ExLiLpHdlampKoz4RiLampRiAg "Right Lamp Right Angle";
CM_ SG_ 343 ExLiLpHdlampKoz5BottomAg "Bottom Angle";
CM_ SG_ 343 ExLiLpHdlampKoz5LeAgPrpty "Left angle object type";
CM_ SG_ 343 ExLiLpHdlampKoz5LeLampLeAg "Left Lamp Left Angle";
CM_ SG_ 343 ExLiLpHdlampKoz5LeLampRiAg "Left Lamp Right Angle";
CM_ SG_ 343 ExLiLpHdlampKoz5RiAgPrpty "Right angle object type";
CM_ SG_ 343 ExLiLpHdlampKoz5RiLampLeAg "Right Lamp Left Angle";
CM_ SG_ 343 ExLiLpHdlampKoz5RiLampRiAg "Right Lamp Right Angle";
CM_ SG_ 344 ExLiHpHdlampDim1BottomAg "Bottom Angle";
CM_ SG_ 344 ExLiHpHdlampDim1LeAgPrpty "Left angle object type";
CM_ SG_ 344 ExLiHpHdlampDim1LeLampLeAg "Left Lamp Left Angle";
CM_ SG_ 344 ExLiHpHdlampDim1LeLampRiAg "Left Lamp Right Angle";
CM_ SG_ 344 ExLiHpHdlampDim1ObjctZoneIntens "Intensity level within an object zone. 255 = 100%, 0 = 0% light intensity";
CM_ SG_ 344 ExLiHpHdlampDim1RiAgPrpty "Right angle object type";
CM_ SG_ 344 ExLiHpHdlampDim1RiLampLeAg "Right Lamp Left Angle";
CM_ SG_ 344 ExLiHpHdlampDim1RiLampRiAg "Right Lamp Right Angle";
CM_ SG_ 344 ExLiHpHdlampDim2BottomAg "Bottom Angle";
CM_ SG_ 344 ExLiHpHdlampDim2LeAgPrpty "Left angle object type";
CM_ SG_ 344 ExLiHpHdlampDim2LeLampLeAg "Left Lamp Left Angle";
CM_ SG_ 344 ExLiHpHdlampDim2LeLampRiAg "Left Lamp Right Angle";
CM_ SG_ 344 ExLiHpHdlampDim2ObjctZoneIntens "Intensity level within an object zone. 255 = 100%, 0 = 0% light intensity";
CM_ SG_ 344 ExLiHpHdlampDim2RiAgPrpty "Right angle object type";
CM_ SG_ 344 ExLiHpHdlampDim2RiLampLeAg "Right Lamp Left Angle";
CM_ SG_ 344 ExLiHpHdlampDim2RiLampRiAg "Right Lamp Right Angle";
CM_ SG_ 344 ExLiHpHdlampDim3BottomAg "Bottom Angle";
CM_ SG_ 344 ExLiHpHdlampDim3LeAgPrpty "Left angle object type";
CM_ SG_ 344 ExLiHpHdlampDim3LeLampLeAg "Left Lamp Left Angle";
CM_ SG_ 344 ExLiHpHdlampDim3LeLampRiAg "Left Lamp Right Angle";
CM_ SG_ 344 ExLiHpHdlampDim3ObjctZoneIntens "Intensity level within an object zone. 255 = 100%, 0 = 0% light intensity";
CM_ SG_ 344 ExLiHpHdlampDim3RiAgPrpty "Right angle object type";
CM_ SG_ 344 ExLiHpHdlampDim3RiLampLeAg "Right Lamp Left Angle";
CM_ SG_ 344 ExLiHpHdlampDim3RiLampRiAg "Right Lamp Right Angle";
CM_ SG_ 344 ExLiLpHdlampCornLeFocus "Light intensity level adjustment";
CM_ SG_ 344 ExLiLpHdlampCornLeReq "Turn on or off cornering light";
CM_ SG_ 344 ExLiLpHdlampCornLeSlope "Request of Cornering light dimming duration";
CM_ SG_ 344 ExLiLpHdlampCornRiFocus "Light intensity level adjustment";
CM_ SG_ 344 ExLiLpHdlampCornRiReq "Turn on or off cornering light";
CM_ SG_ 344 ExLiLpHdlampCornRiSlope "Request of Cornering light dimming duration";
CM_ SG_ 345 ExLiHpTurnIndcrLiReqActivePeriodTime "Light ON time";
CM_ SG_ 345 ExLiHpTurnIndcrLiReqChks "Checksum";
CM_ SG_ 345 ExLiHpTurnIndcrLiReqCntr "Counter";
CM_ SG_ 345 ExLiHpTurnIndcrLiReqDirection "Turn Indicator Light Request";
CM_ SG_ 345 ExLiHpTurnIndcrLiReqInactivePeriodTime "Light OFF time";
CM_ SG_ 345 ExLiHpTurnIndcrLiReqIndcrSeqDownTi "Idicator Sequential down time";
CM_ SG_ 345 ExLiHpTurnIndcrLiReqIndcrSeqUpTi "Indicator Sequential Up Time";
CM_ SG_ 345 ExLiHpTurnIndcrLiReqSlopeDwnTi "Slope Down Time for Direction Indicators";
CM_ SG_ 345 ExLiHpTurnIndcrLiReqSlopeUpTi "Slope Up Time for direction indicators";
CM_ SG_ 345 ExLiHpTurnIndcrLiReqSyncOffTiNanoS "Synchronos time to deactivate Nano Seconds";
CM_ SG_ 345 ExLiHpTurnIndcrLiReqSyncOffTiS "Synchronos time to deactivate Seconds";
CM_ SG_ 345 ExLiHpTurnIndcrLiReqSyncOnTiNanS "Time Sync Signal Nano Seconds";
CM_ SG_ 345 ExLiHpTurnIndcrLiReqSyncOnTiS "Time Sync Signal Seconds";
CM_ SG_ 345 ExLiHpTurnIndcrLiReqTransition "Animation Request";

// Attribute definitions
BA_DEF_  "BaudRateCANFD" FLOAT 1000 10000000; // [bps]
BA_DEF_  "Baudrate" INT 1000 1000000; // [bps]
BA_DEF_  "BusType" STRING;
BA_DEF_  "DBName" STRING;
BA_DEF_  "ProtocolType" STRING;
BA_DEF_ BU_ "NmAsrNode" ENUM "No","Yes";
BA_DEF_ BU_ "NmAsrNodeIdentifier" INT 0 255;
BA_DEF_ BO_ "CANFD_BRS" ENUM "0","1";
BA_DEF_ BO_ "GenMsgCycleTime" INT 0 65536; // [ms]
BA_DEF_ BO_ "GenMsgDelayTime" INT 0 65536; // [ms]
BA_DEF_ BO_ "GenMsgSendType" ENUM "cyclic", "spontaneous", "not-used", "not-used", "not-used", "cyclicAndSpontaneous", "not-used", "cyclicIfActive", "NoMsgSendType"; // [us]
BA_DEF_ BO_ "GenMsgStartDelayTime" INT 0 65536; // [ms]
BA_DEF_ BO_ "VFrameFormat" ENUM "StandardCAN","ExtendedCAN","reserved","J1939PG","reserved","reserved","reserved","reserved","reserved","reserved","reserved","reserved","reserved","reserved","StandardCAN_FD","ExtendedCAN_FD";
BA_DEF_ SG_ "GenSigSendType" ENUM "Cyclic","OnWrite","OnWriteWithRepetition","OnChange","OnChangeWithRepetition","IfActive","IfActiveWithRepetition","NoSigSendType";
BA_DEF_ SG_ "GenSigStartValue" HEX 0 80000000;
BA_DEF_ BO_ "GenMsgILSupport" ENUM "No","Yes";
BA_DEF_ BO_ "NmAsrMessage" ENUM "No","Yes";
BA_DEF_  "NmAsrBaseAddress" HEX 0 536870911;
BA_DEF_  "NmAsrMessageCount" INT 0 255;
BA_DEF_ BU_ "NodeLayerModules" STRING;
BA_DEF_ BU_ "ILused" ENUM "No","Yes";
BA_DEF_ SG_ "GenSigFuncType" ENUM "NoFunction","n/a","n/a","n/a","n/a","n/a","n/a","n/a","n/a","n/a","n/a","n/a","n/a","n/a","n/a","CHK","CNTR","n/a","n/a","n/a","CNTR_AR_01","CRC_AR_01_BOTH","CRC_AR_01_ALT","CRC_AR_01_LOW","CRC_AR_01_NIBBLE","CNTR_AR_04","CRC_AR_04A","CNTR_AR_05","CRC_AR_05";
BA_DEF_ SG_ "GenSigDataID" STRING;

BA_DEF_DEF_ "BusType" "";
BA_DEF_DEF_ "DBName" "";
BA_DEF_DEF_ "ProtocolType" "";
BA_DEF_DEF_ "NmAsrNode" "No";
BA_DEF_DEF_ "NmAsrNodeIdentifier" 0;
BA_DEF_DEF_ "CANFD_BRS" "1";
BA_DEF_DEF_ "GenSigStartValue" 0;
BA_DEF_DEF_ "VFrameFormat" "J1939PG";
BA_DEF_DEF_ "GenSigSendType" "NoSigSendType";
BA_DEF_DEF_ "GenMsgCycleTime" 0;
BA_DEF_DEF_ "GenMsgDelayTime" 0;
BA_DEF_DEF_ "GenMsgStartDelayTime" 0;
BA_DEF_DEF_ "GenMsgSendType" "NoMsgSendType";
BA_DEF_DEF_ "GenMsgILSupport" "Yes";
BA_DEF_DEF_ "NmAsrMessage" "No";
BA_DEF_DEF_ "NmAsrBaseAddress" 1280;
BA_DEF_DEF_ "NmAsrMessageCount" 64;
BA_DEF_DEF_ "NodeLayerModules" "CANoeILNLSPA.dll";
BA_DEF_DEF_ "ILused" "Yes";
BA_DEF_DEF_ "GenSigFuncType" "NoFunction";
BA_DEF_DEF_ "GenSigDataID" "";

BA_ "BaudRateCANFD" 2000000;
BA_ "Baudrate" 500000;
BA_ "BusType" "CAN FD";
BA_ "DBName" "LPC1CAN";
BA_ "ProtocolType" "CAN";
// Network
BA_ "NmAsrMessageCount" 125;
// ECU: LPC
BA_ "NmAsrNode" BU_ LPC 1;
BA_ "NmAsrNodeIdentifier" BU_ LPC 112;
BA_ "NodeLayerModules" BU_ LPC "CANoeILNLSPA.dll,AsrNM33.dll";
// ECU: LPCETC
BA_ "ILused" BU_ LPCETC 0;
// ECU: LPCdp
BA_ "NmAsrNode" BU_ LPCdp 1;
BA_ "NmAsrNodeIdentifier" BU_ LPCdp 113;
BA_ "NodeLayerModules" BU_ LPCdp "CANoeILNLSPA.dll,AsrNM33.dll";
// Frame: LPCdpLpc1CanNMFr
BA_ "GenMsgDelayTime" BO_ 1316 20.000;
BA_ "GenMsgSendType" BO_ 1316 1;
BA_ "VFrameFormat" BO_ 1316 14;
// Frame: LpcdpLpc1canFr01_100ms
BA_ "GenMsgCycleTime" BO_ 336 100.000;
BA_ "GenMsgSendType" BO_ 336 0;
BA_ "VFrameFormat" BO_ 336 14;
// Frame: LpcdpLpc1canFr02_10ms
BA_ "GenMsgCycleTime" BO_ 338 10.000;
BA_ "GenMsgSendType" BO_ 338 0;
BA_ "VFrameFormat" BO_ 338 14;
// Frame: LpcdpLpc1canFr04_10ms
BA_ "GenMsgCycleTime" BO_ 340 10.000;
BA_ "GenMsgSendType" BO_ 340 0;
BA_ "VFrameFormat" BO_ 340 14;
// Frame: LpcdpLpc1canFr05_10ms
BA_ "GenMsgCycleTime" BO_ 341 10.000;
BA_ "GenMsgSendType" BO_ 341 0;
BA_ "VFrameFormat" BO_ 341 14;
// Frame: LpcdpLpc1canFr06_20ms
BA_ "GenMsgCycleTime" BO_ 342 20.000;
BA_ "GenMsgSendType" BO_ 342 0;
BA_ "VFrameFormat" BO_ 342 14;
// Frame: LpcdpLpc1canFr07_10ms
BA_ "GenMsgCycleTime" BO_ 343 10.000;
BA_ "GenMsgSendType" BO_ 343 0;
BA_ "VFrameFormat" BO_ 343 14;
// Frame: LpcdpLpc1canFr08_10ms
BA_ "GenMsgCycleTime" BO_ 344 10.000;
BA_ "GenMsgSendType" BO_ 344 0;
BA_ "VFrameFormat" BO_ 344 14;
// Frame: LpcdpLpc1canFr09_10ms
BA_ "GenMsgCycleTime" BO_ 345 10.000;
BA_ "GenMsgSendType" BO_ 345 0;
BA_ "VFrameFormat" BO_ 345 14;
BA_ "GenMsgILSupport" BO_ 1316 0;
BA_ "NmAsrMessage" BO_ 1316 1;
BA_ "GenSigSendType" SG_ 336 AccrPedlPsdSts 0;
BA_ "GenSigSendType" SG_ 338 ApduRespLpcFromIntrEthByte0 1;
BA_ "GenSigSendType" SG_ 338 ApduRespLpcFromIntrEthByte1 1;
BA_ "GenSigSendType" SG_ 338 ApduRespLpcFromIntrEthByte2 1;
BA_ "GenSigSendType" SG_ 338 ApduRespLpcFromIntrEthByte3 1;
BA_ "GenSigSendType" SG_ 338 ApduRespLpcFromIntrEthByte4 1;
BA_ "GenSigSendType" SG_ 338 ApduRespLpcFromIntrEthByte5 1;
BA_ "GenSigSendType" SG_ 338 ApduRespLpcFromIntrEthByte6 1;
BA_ "GenSigSendType" SG_ 338 ApduRespLpcFromIntrEthByte7 1;
BA_ "GenSigSendType" SG_ 338 ApplIdStsIntrEth 0;
BA_ "GenSigStartValue" SG_ 338 ApplIdStsIntrEth 7;
BA_ "GenSigSendType" SG_ 338 BltLockStDrvr 0;
BA_ "GenSigSendType" SG_ 336 BltRmnTelltl 0;
BA_ "GenSigSendType" SG_ 338 CarModeSyncCarMode 0;
BA_ "GenSigSendType" SG_ 338 CarModeSyncCarModeSubtype 0;
BA_ "GenSigSendType" SG_ 336 ChdProtnActvnReqDoorDrvrRe 0;
BA_ "GenSigSendType" SG_ 336 ChdProtnActvnReqDoorPass 0;
BA_ "GenSigSendType" SG_ 336 ChdProtnActvnReqDoorPassRe 0;
BA_ "GenSigSendType" SG_ 338 CrashModeSync 0;
BA_ "GenSigSendType" SG_ 336 DblLckDi 0;
BA_ "GenSigSendType" SG_ 342 DoorModuleCarCfgDDMMountInfo 0;
BA_ "GenSigSendType" SG_ 342 DoorModuleCarCfgPDMMountInfo 0;
BA_ "GenSigSendType" SG_ 342 DoorModuleCarCfgRDDMMountInfo 0;
BA_ "GenSigSendType" SG_ 342 DoorModuleCarCfgRPDMMountInfo 0;
BA_ "GenSigSendType" SG_ 336 DrvrDesDir1 0;
BA_ "GenSigSendType" SG_ 336 DynCfgStrWhlPosnForUSS 0;
BA_ "GenSigSendType" SG_ 336 DynCfgVehTypForUSS 0;
BA_ "GenSigDataID" SG_ 342 ExLiHpHdlampConcealLeChks "0xB0B";
BA_ "GenSigFuncType" SG_ 342 ExLiHpHdlampConcealLeChks 21;
BA_ "GenSigSendType" SG_ 342 ExLiHpHdlampConcealLeChks 0;
BA_ "GenSigFuncType" SG_ 342 ExLiHpHdlampConcealLeCntr 20;
BA_ "GenSigSendType" SG_ 342 ExLiHpHdlampConcealLeCntr 0;
BA_ "GenSigSendType" SG_ 342 ExLiHpHdlampConcealLeEna 0;
BA_ "GenSigSendType" SG_ 342 ExLiHpHdlampConcealLeMotSply 0;
BA_ "GenSigSendType" SG_ 342 ExLiHpHdlampConcealLePosnReq 0;
BA_ "GenSigSendType" SG_ 342 ExLiHpHdlampConcealLeRefForce 0;
BA_ "GenSigSendType" SG_ 342 ExLiHpHdlampConcealLeRefOk 0;
BA_ "GenSigSendType" SG_ 342 ExLiHpHdlampConcealLeSpd 0;
BA_ "GenSigDataID" SG_ 342 ExLiHpHdlampConcealRiChks "0xB0D";
BA_ "GenSigFuncType" SG_ 342 ExLiHpHdlampConcealRiChks 21;
BA_ "GenSigSendType" SG_ 342 ExLiHpHdlampConcealRiChks 0;
BA_ "GenSigFuncType" SG_ 342 ExLiHpHdlampConcealRiCntr 20;
BA_ "GenSigSendType" SG_ 342 ExLiHpHdlampConcealRiCntr 0;
BA_ "GenSigSendType" SG_ 342 ExLiHpHdlampConcealRiEna 0;
BA_ "GenSigSendType" SG_ 342 ExLiHpHdlampConcealRiMotSply 0;
BA_ "GenSigSendType" SG_ 342 ExLiHpHdlampConcealRiPosnReq 0;
BA_ "GenSigSendType" SG_ 342 ExLiHpHdlampConcealRiRefForce 0;
BA_ "GenSigSendType" SG_ 342 ExLiHpHdlampConcealRiRefOk 0;
BA_ "GenSigSendType" SG_ 342 ExLiHpHdlampConcealRiSpd 0;
BA_ "GenSigSendType" SG_ 344 ExLiHpHdlampDim1BottomAg 0;
BA_ "GenSigSendType" SG_ 344 ExLiHpHdlampDim1LeAgPrpty 0;
BA_ "GenSigSendType" SG_ 344 ExLiHpHdlampDim1LeLampLeAg 0;
BA_ "GenSigSendType" SG_ 344 ExLiHpHdlampDim1LeLampRiAg 0;
BA_ "GenSigSendType" SG_ 344 ExLiHpHdlampDim1ObjctZoneIntens 0;
BA_ "GenSigSendType" SG_ 344 ExLiHpHdlampDim1RiAgPrpty 0;
BA_ "GenSigSendType" SG_ 344 ExLiHpHdlampDim1RiLampLeAg 0;
BA_ "GenSigSendType" SG_ 344 ExLiHpHdlampDim1RiLampRiAg 0;
BA_ "GenSigSendType" SG_ 344 ExLiHpHdlampDim2BottomAg 0;
BA_ "GenSigSendType" SG_ 344 ExLiHpHdlampDim2LeAgPrpty 0;
BA_ "GenSigSendType" SG_ 344 ExLiHpHdlampDim2LeLampLeAg 0;
BA_ "GenSigSendType" SG_ 344 ExLiHpHdlampDim2LeLampRiAg 0;
BA_ "GenSigSendType" SG_ 344 ExLiHpHdlampDim2ObjctZoneIntens 0;
BA_ "GenSigSendType" SG_ 344 ExLiHpHdlampDim2RiAgPrpty 0;
BA_ "GenSigSendType" SG_ 344 ExLiHpHdlampDim2RiLampLeAg 0;
BA_ "GenSigSendType" SG_ 344 ExLiHpHdlampDim2RiLampRiAg 0;
BA_ "GenSigSendType" SG_ 344 ExLiHpHdlampDim3BottomAg 0;
BA_ "GenSigSendType" SG_ 344 ExLiHpHdlampDim3LeAgPrpty 0;
BA_ "GenSigSendType" SG_ 344 ExLiHpHdlampDim3LeLampLeAg 0;
BA_ "GenSigSendType" SG_ 344 ExLiHpHdlampDim3LeLampRiAg 0;
BA_ "GenSigSendType" SG_ 344 ExLiHpHdlampDim3ObjctZoneIntens 0;
BA_ "GenSigSendType" SG_ 344 ExLiHpHdlampDim3RiAgPrpty 0;
BA_ "GenSigSendType" SG_ 344 ExLiHpHdlampDim3RiLampLeAg 0;
BA_ "GenSigSendType" SG_ 344 ExLiHpHdlampDim3RiLampRiAg 0;
BA_ "GenSigSendType" SG_ 342 ExLiHpHdlampDrlPosLeFocus 0;
BA_ "GenSigSendType" SG_ 342 ExLiHpHdlampDrlPosLeShape 0;
BA_ "GenSigSendType" SG_ 342 ExLiHpHdlampDrlPosLeSlope 0;
BA_ "GenSigSendType" SG_ 342 ExLiHpHdlampDrlPosLeTransition 0;
BA_ "GenSigSendType" SG_ 342 ExLiHpHdlampDrlPosRiFocus 0;
BA_ "GenSigSendType" SG_ 342 ExLiHpHdlampDrlPosRiShape 0;
BA_ "GenSigSendType" SG_ 342 ExLiHpHdlampDrlPosRiSlope 0;
BA_ "GenSigSendType" SG_ 342 ExLiHpHdlampDrlPosRiTransition 0;
BA_ "GenSigSendType" SG_ 342 ExLiHpHdlampSmlLeSideMkrLe 0;
BA_ "GenSigSendType" SG_ 342 ExLiHpHdlampSmlLeSideMkrLeFocus 0;
BA_ "GenSigSendType" SG_ 342 ExLiHpHdlampSmlLeSideMkrLeSlope 0;
BA_ "GenSigSendType" SG_ 342 ExLiHpHdlampSmlRiSideMkrRi 0;
BA_ "GenSigSendType" SG_ 342 ExLiHpHdlampSmlRiSideMkrRiFocus 0;
BA_ "GenSigSendType" SG_ 342 ExLiHpHdlampSmlRiSideMkrRiSlope 0;
BA_ "GenSigSendType" SG_ 342 ExLiHpHiDefCalibrationStsLe 0;
BA_ "GenSigSendType" SG_ 342 ExLiHpHiDefCalibrationStsRi 0;
BA_ "GenSigSendType" SG_ 342 ExLiHpRearSmlLi 0;
BA_ "GenSigSendType" SG_ 342 ExLiHpTrlrLiActvnBrk 0;
BA_ "GenSigSendType" SG_ 342 ExLiHpTrlrLiActvnFog 0;
BA_ "GenSigSendType" SG_ 342 ExLiHpTrlrLiActvnPosn 0;
BA_ "GenSigSendType" SG_ 342 ExLiHpTrlrLiActvnRvsg 0;
BA_ "GenSigSendType" SG_ 345 ExLiHpTurnIndcrLiReqActivePeriodTime 0;
BA_ "GenSigDataID" SG_ 345 ExLiHpTurnIndcrLiReqChks "0x86E";
BA_ "GenSigFuncType" SG_ 345 ExLiHpTurnIndcrLiReqChks 28;
BA_ "GenSigSendType" SG_ 345 ExLiHpTurnIndcrLiReqChks 0;
BA_ "GenSigFuncType" SG_ 345 ExLiHpTurnIndcrLiReqCntr 27;
BA_ "GenSigSendType" SG_ 345 ExLiHpTurnIndcrLiReqCntr 0;
BA_ "GenSigSendType" SG_ 345 ExLiHpTurnIndcrLiReqDirection 0;
BA_ "GenSigSendType" SG_ 345 ExLiHpTurnIndcrLiReqInactivePeriodTime 0;
BA_ "GenSigSendType" SG_ 345 ExLiHpTurnIndcrLiReqIndcrSeqDownTi 0;
BA_ "GenSigSendType" SG_ 345 ExLiHpTurnIndcrLiReqIndcrSeqUpTi 0;
BA_ "GenSigSendType" SG_ 345 ExLiHpTurnIndcrLiReqSlopeDwnTi 0;
BA_ "GenSigSendType" SG_ 345 ExLiHpTurnIndcrLiReqSlopeUpTi 0;
BA_ "GenSigSendType" SG_ 345 ExLiHpTurnIndcrLiReqSyncOffTiNanoS 0;
BA_ "GenSigSendType" SG_ 345 ExLiHpTurnIndcrLiReqSyncOffTiS 0;
BA_ "GenSigSendType" SG_ 345 ExLiHpTurnIndcrLiReqSyncOnTiNanS 0;
BA_ "GenSigSendType" SG_ 345 ExLiHpTurnIndcrLiReqSyncOnTiS 0;
BA_ "GenSigSendType" SG_ 345 ExLiHpTurnIndcrLiReqTransition 0;
BA_ "GenSigSendType" SG_ 344 ExLiLpHdlampCornLeFocus 0;
BA_ "GenSigSendType" SG_ 344 ExLiLpHdlampCornLeReq 0;
BA_ "GenSigSendType" SG_ 344 ExLiLpHdlampCornLeSlope 0;
BA_ "GenSigSendType" SG_ 344 ExLiLpHdlampCornRiFocus 0;
BA_ "GenSigSendType" SG_ 344 ExLiLpHdlampCornRiReq 0;
BA_ "GenSigSendType" SG_ 344 ExLiLpHdlampCornRiSlope 0;
BA_ "GenSigSendType" SG_ 344 ExLiLpHdlampHozlLeHozlLeEna 0;
BA_ "GenSigSendType" SG_ 344 ExLiLpHdlampHozlLeHozlLeMotSply 0;
BA_ "GenSigSendType" SG_ 344 ExLiLpHdlampHozlLeHozlLeRefForce 0;
BA_ "GenSigSendType" SG_ 344 ExLiLpHdlampHozlLeHozlLeRefOk 0;
BA_ "GenSigSendType" SG_ 344 ExLiLpHdlampHozlLeHozlLeReq 0;
BA_ "GenSigStartValue" SG_ 344 ExLiLpHdlampHozlLeHozlLeReq 1023;
BA_ "GenSigSendType" SG_ 344 ExLiLpHdlampHozlRiHozlRiEna 0;
BA_ "GenSigSendType" SG_ 344 ExLiLpHdlampHozlRiHozlRiMotSply 0;
BA_ "GenSigSendType" SG_ 344 ExLiLpHdlampHozlRiHozlRiRefForce 0;
BA_ "GenSigSendType" SG_ 344 ExLiLpHdlampHozlRiHozlRiRefOk 0;
BA_ "GenSigSendType" SG_ 344 ExLiLpHdlampHozlRiHozlRiReq 0;
BA_ "GenSigStartValue" SG_ 344 ExLiLpHdlampHozlRiHozlRiReq 1023;
BA_ "GenSigSendType" SG_ 343 ExLiLpHdlampKoz1BottomAg 0;
BA_ "GenSigSendType" SG_ 343 ExLiLpHdlampKoz1LeAgPrpty 0;
BA_ "GenSigSendType" SG_ 343 ExLiLpHdlampKoz1LeLampLeAg 0;
BA_ "GenSigSendType" SG_ 343 ExLiLpHdlampKoz1LeLampRiAg 0;
BA_ "GenSigSendType" SG_ 343 ExLiLpHdlampKoz1RiAgPrpty 0;
BA_ "GenSigSendType" SG_ 343 ExLiLpHdlampKoz1RiLampLeAg 0;
BA_ "GenSigSendType" SG_ 343 ExLiLpHdlampKoz1RiLampRiAg 0;
BA_ "GenSigSendType" SG_ 343 ExLiLpHdlampKoz2BottomAg 0;
BA_ "GenSigSendType" SG_ 343 ExLiLpHdlampKoz2LeAgPrpty 0;
BA_ "GenSigSendType" SG_ 343 ExLiLpHdlampKoz2LeLampLeAg 0;
BA_ "GenSigSendType" SG_ 343 ExLiLpHdlampKoz2LeLampRiAg 0;
BA_ "GenSigSendType" SG_ 343 ExLiLpHdlampKoz2RiAgPrpty 0;
BA_ "GenSigSendType" SG_ 343 ExLiLpHdlampKoz2RiLampLeAg 0;
BA_ "GenSigSendType" SG_ 343 ExLiLpHdlampKoz2RiLampRiAg 0;
BA_ "GenSigSendType" SG_ 343 ExLiLpHdlampKoz3BottomAg 0;
BA_ "GenSigSendType" SG_ 343 ExLiLpHdlampKoz3LeAgPrpty 0;
BA_ "GenSigSendType" SG_ 343 ExLiLpHdlampKoz3LeLampLeAg 0;
BA_ "GenSigSendType" SG_ 343 ExLiLpHdlampKoz3LeLampRiAg 0;
BA_ "GenSigSendType" SG_ 343 ExLiLpHdlampKoz3RiAgPrpty 0;
BA_ "GenSigSendType" SG_ 343 ExLiLpHdlampKoz3RiLampLeAg 0;
BA_ "GenSigSendType" SG_ 343 ExLiLpHdlampKoz3RiLampRiAg 0;
BA_ "GenSigSendType" SG_ 343 ExLiLpHdlampKoz4BottomAg 0;
BA_ "GenSigSendType" SG_ 343 ExLiLpHdlampKoz4LeAgPrpty 0;
BA_ "GenSigSendType" SG_ 343 ExLiLpHdlampKoz4LeLampLeAg 0;
BA_ "GenSigSendType" SG_ 343 ExLiLpHdlampKoz4LeLampRiAg 0;
BA_ "GenSigSendType" SG_ 343 ExLiLpHdlampKoz4RiAgPrpty 0;
BA_ "GenSigSendType" SG_ 343 ExLiLpHdlampKoz4RiLampLeAg 0;
BA_ "GenSigSendType" SG_ 343 ExLiLpHdlampKoz4RiLampRiAg 0;
BA_ "GenSigSendType" SG_ 343 ExLiLpHdlampKoz5BottomAg 0;
BA_ "GenSigSendType" SG_ 343 ExLiLpHdlampKoz5LeAgPrpty 0;
BA_ "GenSigSendType" SG_ 343 ExLiLpHdlampKoz5LeLampLeAg 0;
BA_ "GenSigSendType" SG_ 343 ExLiLpHdlampKoz5LeLampRiAg 0;
BA_ "GenSigSendType" SG_ 343 ExLiLpHdlampKoz5RiAgPrpty 0;
BA_ "GenSigSendType" SG_ 343 ExLiLpHdlampKoz5RiLampLeAg 0;
BA_ "GenSigSendType" SG_ 343 ExLiLpHdlampKoz5RiLampRiAg 0;
BA_ "GenSigSendType" SG_ 342 ExLiLpHdlampLiLeBeamLeFocus 0;
BA_ "GenSigSendType" SG_ 342 ExLiLpHdlampLiLeBeamLeShape 0;
BA_ "GenSigSendType" SG_ 342 ExLiLpHdlampLiLeBeamLeSlope 0;
BA_ "GenSigSendType" SG_ 342 ExLiLpHdlampLiLeBeamLeSymbol 0;
BA_ "GenSigSendType" SG_ 342 ExLiLpHdlampLiLeBeamLeTransition 0;
BA_ "GenSigDataID" SG_ 342 ExLiLpHdlampLiLeHeadlampLeChks "0x777";
BA_ "GenSigFuncType" SG_ 342 ExLiLpHdlampLiLeHeadlampLeChks 21;
BA_ "GenSigSendType" SG_ 342 ExLiLpHdlampLiLeHeadlampLeChks 0;
BA_ "GenSigFuncType" SG_ 342 ExLiLpHdlampLiLeHeadlampLeCntr 20;
BA_ "GenSigSendType" SG_ 342 ExLiLpHdlampLiLeHeadlampLeCntr 0;
BA_ "GenSigSendType" SG_ 342 ExLiLpHdlampLiLeLiTrfcSide 0;
BA_ "GenSigSendType" SG_ 342 ExLiLpHdlampLiRiBeamRiFocus 0;
BA_ "GenSigSendType" SG_ 342 ExLiLpHdlampLiRiBeamRiShape 0;
BA_ "GenSigSendType" SG_ 342 ExLiLpHdlampLiRiBeamRiSlope 0;
BA_ "GenSigSendType" SG_ 342 ExLiLpHdlampLiRiBeamRiSymbol 0;
BA_ "GenSigSendType" SG_ 342 ExLiLpHdlampLiRiBeamRiTransition 0;
BA_ "GenSigDataID" SG_ 342 ExLiLpHdlampLiRiHeadlampRiChks "0x77A";
BA_ "GenSigFuncType" SG_ 342 ExLiLpHdlampLiRiHeadlampRiChks 21;
BA_ "GenSigSendType" SG_ 342 ExLiLpHdlampLiRiHeadlampRiChks 0;
BA_ "GenSigFuncType" SG_ 342 ExLiLpHdlampLiRiHeadlampRiCntr 20;
BA_ "GenSigSendType" SG_ 342 ExLiLpHdlampLiRiHeadlampRiCntr 0;
BA_ "GenSigSendType" SG_ 342 ExLiLpHdlampLiRiLiTrfcSide 0;
BA_ "GenSigDataID" SG_ 342 ExLiLpHdlampLvlLeLvlLeChks "0x778";
BA_ "GenSigFuncType" SG_ 342 ExLiLpHdlampLvlLeLvlLeChks 21;
BA_ "GenSigSendType" SG_ 342 ExLiLpHdlampLvlLeLvlLeChks 0;
BA_ "GenSigFuncType" SG_ 342 ExLiLpHdlampLvlLeLvlLeCntr 20;
BA_ "GenSigSendType" SG_ 342 ExLiLpHdlampLvlLeLvlLeCntr 0;
BA_ "GenSigSendType" SG_ 342 ExLiLpHdlampLvlLeLvlLeEna 0;
BA_ "GenSigSendType" SG_ 342 ExLiLpHdlampLvlLeLvlLeMotSply 0;
BA_ "GenSigSendType" SG_ 342 ExLiLpHdlampLvlLeLvlLeRefForce 0;
BA_ "GenSigSendType" SG_ 342 ExLiLpHdlampLvlLeLvlLeRefOk 0;
BA_ "GenSigSendType" SG_ 342 ExLiLpHdlampLvlLeLvlLeReq 0;
BA_ "GenSigStartValue" SG_ 342 ExLiLpHdlampLvlLeLvlLeReq 1020;
BA_ "GenSigDataID" SG_ 342 ExLiLpHdlampLvlRiLvlRiChks "0x77B";
BA_ "GenSigFuncType" SG_ 342 ExLiLpHdlampLvlRiLvlRiChks 21;
BA_ "GenSigSendType" SG_ 342 ExLiLpHdlampLvlRiLvlRiChks 0;
BA_ "GenSigFuncType" SG_ 342 ExLiLpHdlampLvlRiLvlRiCntr 20;
BA_ "GenSigSendType" SG_ 342 ExLiLpHdlampLvlRiLvlRiCntr 0;
BA_ "GenSigSendType" SG_ 342 ExLiLpHdlampLvlRiLvlRiEna 0;
BA_ "GenSigSendType" SG_ 342 ExLiLpHdlampLvlRiLvlRiMotSply 0;
BA_ "GenSigSendType" SG_ 342 ExLiLpHdlampLvlRiLvlRiRefForce 0;
BA_ "GenSigSendType" SG_ 342 ExLiLpHdlampLvlRiLvlRiRefOk 0;
BA_ "GenSigSendType" SG_ 342 ExLiLpHdlampLvlRiLvlRiReq 0;
BA_ "GenSigStartValue" SG_ 342 ExLiLpHdlampLvlRiLvlRiReq 1020;
BA_ "GenSigSendType" SG_ 341 ExLiLpHiDefHozlLeDLPHozlLeEna 0;
BA_ "GenSigSendType" SG_ 341 ExLiLpHiDefHozlLeDLPHozlLeReq 0;
BA_ "GenSigStartValue" SG_ 341 ExLiLpHiDefHozlLeDLPHozlLeReq 1023;
BA_ "GenSigSendType" SG_ 341 ExLiLpHiDefHozlRiDLPHozlRiEna 0;
BA_ "GenSigSendType" SG_ 341 ExLiLpHiDefHozlRiDLPHozlRiReq 0;
BA_ "GenSigStartValue" SG_ 341 ExLiLpHiDefHozlRiDLPHozlRiReq 1023;
BA_ "GenSigSendType" SG_ 341 ExLiLpHiDefLiLeDLPLeShape 0;
BA_ "GenSigSendType" SG_ 341 ExLiLpHiDefLiLeDLPLeSlope 0;
BA_ "GenSigSendType" SG_ 341 ExLiLpHiDefLiLeDLPLeTransition 0;
BA_ "GenSigSendType" SG_ 341 ExLiLpHiDefLiLeTrafficSide 0;
BA_ "GenSigSendType" SG_ 341 ExLiLpHiDefLiRiDLPRiShape 0;
BA_ "GenSigSendType" SG_ 341 ExLiLpHiDefLiRiDLPRiSlope 0;
BA_ "GenSigSendType" SG_ 341 ExLiLpHiDefLiRiDLPRiTransition 0;
BA_ "GenSigSendType" SG_ 341 ExLiLpHiDefLiRiTrafficSide 0;
BA_ "GenSigSendType" SG_ 340 ExLiLpHiDefZone1BottomAg 0;
BA_ "GenSigSendType" SG_ 340 ExLiLpHiDefZone1GradWdth 0;
BA_ "GenSigSendType" SG_ 340 ExLiLpHiDefZone1LeAgPrpty 0;
BA_ "GenSigSendType" SG_ 340 ExLiLpHiDefZone1LeLampLeAg 0;
BA_ "GenSigSendType" SG_ 340 ExLiLpHiDefZone1LeLampRiAg 0;
BA_ "GenSigSendType" SG_ 340 ExLiLpHiDefZone1ObjctZoneIntens 0;
BA_ "GenSigSendType" SG_ 340 ExLiLpHiDefZone1RiAgPrpty 0;
BA_ "GenSigSendType" SG_ 340 ExLiLpHiDefZone1RiLampLeAg 0;
BA_ "GenSigSendType" SG_ 340 ExLiLpHiDefZone1RiLampRiAg 0;
BA_ "GenSigSendType" SG_ 340 ExLiLpHiDefZone1TopAg 0;
BA_ "GenSigSendType" SG_ 340 ExLiLpHiDefZone2BottomAg 0;
BA_ "GenSigSendType" SG_ 340 ExLiLpHiDefZone2GradWdth 0;
BA_ "GenSigSendType" SG_ 340 ExLiLpHiDefZone2LeAgPrpty 0;
BA_ "GenSigSendType" SG_ 340 ExLiLpHiDefZone2LeLampLeAg 0;
BA_ "GenSigSendType" SG_ 340 ExLiLpHiDefZone2LeLampRiAg 0;
BA_ "GenSigSendType" SG_ 340 ExLiLpHiDefZone2ObjctZoneIntens 0;
BA_ "GenSigSendType" SG_ 340 ExLiLpHiDefZone2RiAgPrpty 0;
BA_ "GenSigSendType" SG_ 340 ExLiLpHiDefZone2RiLampLeAg 0;
BA_ "GenSigSendType" SG_ 340 ExLiLpHiDefZone2RiLampRiAg 0;
BA_ "GenSigSendType" SG_ 340 ExLiLpHiDefZone2TopAg 0;
BA_ "GenSigSendType" SG_ 340 ExLiLpHiDefZone3BottomAg 0;
BA_ "GenSigSendType" SG_ 340 ExLiLpHiDefZone3GradWdth 0;
BA_ "GenSigSendType" SG_ 340 ExLiLpHiDefZone3LeAgPrpty 0;
BA_ "GenSigSendType" SG_ 340 ExLiLpHiDefZone3LeLampLeAg 0;
BA_ "GenSigSendType" SG_ 340 ExLiLpHiDefZone3LeLampRiAg 0;
BA_ "GenSigSendType" SG_ 340 ExLiLpHiDefZone3ObjctZoneIntens 0;
BA_ "GenSigSendType" SG_ 340 ExLiLpHiDefZone3RiAgPrpty 0;
BA_ "GenSigSendType" SG_ 340 ExLiLpHiDefZone3RiLampLeAg 0;
BA_ "GenSigSendType" SG_ 340 ExLiLpHiDefZone3RiLampRiAg 0;
BA_ "GenSigSendType" SG_ 340 ExLiLpHiDefZone3TopAg 0;
BA_ "GenSigSendType" SG_ 340 ExLiLpHiDefZone4BottomAg 0;
BA_ "GenSigSendType" SG_ 340 ExLiLpHiDefZone4GradWdth 0;
BA_ "GenSigSendType" SG_ 340 ExLiLpHiDefZone4LeAgPrpty 0;
BA_ "GenSigSendType" SG_ 340 ExLiLpHiDefZone4LeLampLeAg 0;
BA_ "GenSigSendType" SG_ 340 ExLiLpHiDefZone4LeLampRiAg 0;
BA_ "GenSigSendType" SG_ 340 ExLiLpHiDefZone4ObjctZoneIntens 0;
BA_ "GenSigSendType" SG_ 340 ExLiLpHiDefZone4RiAgPrpty 0;
BA_ "GenSigSendType" SG_ 340 ExLiLpHiDefZone4RiLampLeAg 0;
BA_ "GenSigSendType" SG_ 340 ExLiLpHiDefZone4RiLampRiAg 0;
BA_ "GenSigSendType" SG_ 340 ExLiLpHiDefZone4TopAg 0;
BA_ "GenSigSendType" SG_ 340 ExLiLpHiDefZone5BottomAg 0;
BA_ "GenSigSendType" SG_ 340 ExLiLpHiDefZone5GradWdth 0;
BA_ "GenSigSendType" SG_ 340 ExLiLpHiDefZone5LeAgPrpty 0;
BA_ "GenSigSendType" SG_ 340 ExLiLpHiDefZone5LeLampLeAg 0;
BA_ "GenSigSendType" SG_ 340 ExLiLpHiDefZone5LeLampRiAg 0;
BA_ "GenSigSendType" SG_ 340 ExLiLpHiDefZone5ObjctZoneIntens 0;
BA_ "GenSigSendType" SG_ 340 ExLiLpHiDefZone5RiAgPrpty 0;
BA_ "GenSigSendType" SG_ 340 ExLiLpHiDefZone5RiLampLeAg 0;
BA_ "GenSigSendType" SG_ 340 ExLiLpHiDefZone5RiLampRiAg 0;
BA_ "GenSigSendType" SG_ 340 ExLiLpHiDefZone5TopAg 0;
BA_ "GenSigSendType" SG_ 341 ExLiLpHiDefZone6BottomAg 0;
BA_ "GenSigSendType" SG_ 341 ExLiLpHiDefZone6GradWdth 0;
BA_ "GenSigSendType" SG_ 341 ExLiLpHiDefZone6LeAgPrpty 0;
BA_ "GenSigSendType" SG_ 341 ExLiLpHiDefZone6LeLampLeAg 0;
BA_ "GenSigSendType" SG_ 341 ExLiLpHiDefZone6LeLampRiAg 0;
BA_ "GenSigSendType" SG_ 341 ExLiLpHiDefZone6ObjctZoneIntens 0;
BA_ "GenSigSendType" SG_ 341 ExLiLpHiDefZone6RiAgPrpty 0;
BA_ "GenSigSendType" SG_ 341 ExLiLpHiDefZone6RiLampLeAg 0;
BA_ "GenSigSendType" SG_ 341 ExLiLpHiDefZone6RiLampRiAg 0;
BA_ "GenSigSendType" SG_ 341 ExLiLpHiDefZone6TopAg 0;
BA_ "GenSigSendType" SG_ 341 ExLiLpHiDefZone7BottomAg 0;
BA_ "GenSigSendType" SG_ 341 ExLiLpHiDefZone7GradWdth 0;
BA_ "GenSigSendType" SG_ 341 ExLiLpHiDefZone7LeAgPrpty 0;
BA_ "GenSigSendType" SG_ 341 ExLiLpHiDefZone7LeLampLeAg 0;
BA_ "GenSigSendType" SG_ 341 ExLiLpHiDefZone7LeLampRiAg 0;
BA_ "GenSigSendType" SG_ 341 ExLiLpHiDefZone7ObjctZoneIntens 0;
BA_ "GenSigSendType" SG_ 341 ExLiLpHiDefZone7RiAgPrpty 0;
BA_ "GenSigSendType" SG_ 341 ExLiLpHiDefZone7RiLampLeAg 0;
BA_ "GenSigSendType" SG_ 341 ExLiLpHiDefZone7RiLampRiAg 0;
BA_ "GenSigSendType" SG_ 341 ExLiLpHiDefZone7TopAg 0;
BA_ "GenSigSendType" SG_ 341 ExLiLpHiDefZone8BottomAg 0;
BA_ "GenSigSendType" SG_ 341 ExLiLpHiDefZone8GradWdth 0;
BA_ "GenSigSendType" SG_ 341 ExLiLpHiDefZone8LeAgPrpty 0;
BA_ "GenSigSendType" SG_ 341 ExLiLpHiDefZone8LeLampLeAg 0;
BA_ "GenSigSendType" SG_ 341 ExLiLpHiDefZone8LeLampRiAg 0;
BA_ "GenSigSendType" SG_ 341 ExLiLpHiDefZone8ObjctZoneIntens 0;
BA_ "GenSigSendType" SG_ 341 ExLiLpHiDefZone8RiAgPrpty 0;
BA_ "GenSigSendType" SG_ 341 ExLiLpHiDefZone8RiLampLeAg 0;
BA_ "GenSigSendType" SG_ 341 ExLiLpHiDefZone8RiLampRiAg 0;
BA_ "GenSigSendType" SG_ 341 ExLiLpHiDefZone8TopAg 0;
BA_ "GenSigSendType" SG_ 342 FrntWhlAgFrntWhlAg 0;
BA_ "GenSigSendType" SG_ 342 FrntWhlAgMaxWhlAg 0;
BA_ "GenSigSendType" SG_ 336 FrntWiprReq 0;
BA_ "GenSigStartValue" SG_ 336 FrntWiprReq 1;
BA_ "GenSigSendType" SG_ 336 FwdLookCamHeatingReq 0;
BA_ "GenSigSendType" SG_ 338 GearLvlIndcn 0;
BA_ "GenSigSendType" SG_ 336 GlobalRealTimeGS 0;
BA_ "GenSigSendType" SG_ 336 GlvBoxRelsBtnPsd 1;
BA_ "GenSigSendType" SG_ 336 HMISts 0;
BA_ "GenSigStartValue" SG_ 336 HMISts 1;
BA_ "GenSigSendType" SG_ 338 IntrBriStsAmb 0;
BA_ "GenSigStartValue" SG_ 338 IntrBriStsAmb 10;
BA_ "GenSigSendType" SG_ 338 IntrBriStsCsd 0;
BA_ "GenSigStartValue" SG_ 338 IntrBriStsCsd 10;
BA_ "GenSigSendType" SG_ 338 IntrBriStsDim 0;
BA_ "GenSigStartValue" SG_ 338 IntrBriStsDim 10;
BA_ "GenSigSendType" SG_ 338 IntrBriStsHud 0;
BA_ "GenSigStartValue" SG_ 338 IntrBriStsHud 10;
BA_ "GenSigSendType" SG_ 338 IntrBriStsSwt 0;
BA_ "GenSigStartValue" SG_ 338 IntrBriStsSwt 10;
BA_ "GenSigSendType" SG_ 338 IntrLiUsrPrsntDrvrSeat 0;
BA_ "GenSigSendType" SG_ 338 IntrLiUsrPrsntPassSeat 0;
BA_ "GenSigSendType" SG_ 338 IntrLiUsrPrsntReCentrSeat2nd 0;
BA_ "GenSigSendType" SG_ 338 IntrLiUsrPrsntReDrvrSeat2nd 0;
BA_ "GenSigSendType" SG_ 338 IntrLiUsrPrsntReDrvrSeat3nd 0;
BA_ "GenSigSendType" SG_ 338 IntrLiUsrPrsntRePassSeat2nd 0;
BA_ "GenSigSendType" SG_ 338 IntrLiUsrPrsntRePassSeat3nd 0;
BA_ "GenSigSendType" SG_ 338 IntrLiUsrPrsntTrAr 0;
BA_ "GenSigSendType" SG_ 342 LCMACarCfgBlisInfoSys 0;
BA_ "GenSigSendType" SG_ 336 LcmaIndcnDrvr 0;
BA_ "GenSigSendType" SG_ 336 LcmaIndcnPass 0;
BA_ "GenSigSendType" SG_ 336 LockgExtReqLockActv 0;
BA_ "GenSigSendType" SG_ 336 LockgExtReqLockDly 0;
BA_ "GenSigSendType" SG_ 336 LockgExtReqLockRep 0;
BA_ "GenSigStartValue" SG_ 336 LockgExtReqLockRep 1;
BA_ "GenSigSendType" SG_ 336 LockgPrsnlReq 0;
BA_ "GenSigSendType" SG_ 336 LockgSetgFbAudibleFeedback 0;
BA_ "GenSigSendType" SG_ 336 LockgSetgFbVisibleFeedback 0;
BA_ "GenSigSendType" SG_ 336 LockgSetgPasLockBySpeed 0;
BA_ "GenSigSendType" SG_ 336 LockgSetgPasLockWalkAway 0;
BA_ "GenSigSendType" SG_ 336 LockgSetgPasUnlockApproach 0;
BA_ "GenSigSendType" SG_ 336 LockgSetgSngDoorUnlck 0;
BA_ "GenSigSendType" SG_ 336 MirrAutoDimSetg 0;
BA_ "GenSigSendType" SG_ 336 MirrCmdRecAtDrvrMirrFoldCmd 0;
BA_ "GenSigSendType" SG_ 336 MirrCmdRecAtDrvrMirrPosAdjCmd 0;
BA_ "GenSigSendType" SG_ 336 MirrCmdRecAtPassMirrFoldCmd 0;
BA_ "GenSigSendType" SG_ 336 MirrCmdRecAtPassMirrPosAdjCmd 0;
BA_ "GenSigSendType" SG_ 336 MirrDfrstType 0;
BA_ "GenSigSendType" SG_ 336 MirrPosnSensTrgtValDrvrMirrSensXPos 0;
BA_ "GenSigSendType" SG_ 336 MirrPosnSensTrgtValDrvrMirrSensYPos 0;
BA_ "GenSigSendType" SG_ 336 MirrPosnSensTrgtValPassMirrSensXPos 0;
BA_ "GenSigSendType" SG_ 336 MirrPosnSensTrgtValPassMirrSensYPos 0;
BA_ "GenSigSendType" SG_ 336 MirrorDefrosterReq 0;
BA_ "GenSigSendType" SG_ 336 MirrorFuncCarCfgExtRearViewMirrorType 0;
BA_ "GenSigSendType" SG_ 336 MirrorFuncCarCfgRearViewMirrorDimType 0;
BA_ "GenSigSendType" SG_ 336 MirrorFuncCarCfgRearViewMirrorMemType 0;
BA_ "GenSigSendType" SG_ 336 OutsideTemperatureGS 0;
BA_ "GenSigSendType" SG_ 342 PAPGearShiftrIntv 0;
BA_ "GenSigSendType" SG_ 342 PAPLoSpdMod 0;
BA_ "GenSigDataID" SG_ 336 PassAirbLmpReqChks "0x9B0";
BA_ "GenSigFuncType" SG_ 336 PassAirbLmpReqChks 21;
BA_ "GenSigSendType" SG_ 336 PassAirbLmpReqChks 0;
BA_ "GenSigFuncType" SG_ 336 PassAirbLmpReqCntr 20;
BA_ "GenSigSendType" SG_ 336 PassAirbLmpReqCntr 0;
BA_ "GenSigSendType" SG_ 336 PassAirbLmpReqPassAirbLmpReq 0;
BA_ "GenSigSendType" SG_ 338 PinionAgPinionSteerAg1 0;
BA_ "GenSigSendType" SG_ 338 PinionAgPinionSteerAg1Qf 0;
BA_ "GenSigSendType" SG_ 338 PowerControllerRlySyncADPMWakeUpSync 0;
BA_ "GenSigSendType" SG_ 338 PowerControllerRlySyncAUDWakeUpSync 0;
BA_ "GenSigDataID" SG_ 338 PowerControllerRlySyncChks "0x9D6";
BA_ "GenSigFuncType" SG_ 338 PowerControllerRlySyncChks 21;
BA_ "GenSigSendType" SG_ 338 PowerControllerRlySyncChks 0;
BA_ "GenSigSendType" SG_ 338 PowerControllerRlySyncClimateActuatorRelaySync 0;
BA_ "GenSigFuncType" SG_ 338 PowerControllerRlySyncCntr 20;
BA_ "GenSigSendType" SG_ 338 PowerControllerRlySyncCntr 0;
BA_ "GenSigSendType" SG_ 338 PowerControllerRlySyncDIMWakeUpSync 0;
BA_ "GenSigSendType" SG_ 338 PowerControllerRlySyncExteriorLightRelaySync 0;
BA_ "GenSigSendType" SG_ 338 PowerControllerRlySyncIgnitionPowerRelaySync 0;
BA_ "GenSigSendType" SG_ 338 PowerControllerRlySyncSUMWakeUpSync 0;
BA_ "GenSigSendType" SG_ 338 PreApduSndIntrEth 0;
BA_ "GenSigSendType" SG_ 336 RainSnsrLiThdCmd 0;
BA_ "GenSigStartValue" SG_ 336 RainSnsrLiThdCmd 8;
BA_ "GenSigSendType" SG_ 342 ReFogLiIntensity 0;
BA_ "GenSigSendType" SG_ 342 ReFogLiReq 0;
BA_ "GenSigSendType" SG_ 342 ReFogLiSlope 0;
BA_ "GenSigDataID" SG_ 342 RePosLiChks "0xA52";
BA_ "GenSigFuncType" SG_ 342 RePosLiChks 21;
BA_ "GenSigSendType" SG_ 342 RePosLiChks 0;
BA_ "GenSigFuncType" SG_ 342 RePosLiCntr 20;
BA_ "GenSigSendType" SG_ 342 RePosLiCntr 0;
BA_ "GenSigSendType" SG_ 342 RePosLiReq 0;
BA_ "GenSigSendType" SG_ 342 RePosLiSlope 0;
BA_ "GenSigSendType" SG_ 342 RePosLiTransition 0;
BA_ "GenSigSendType" SG_ 342 RegLiReq 0;
BA_ "GenSigSendType" SG_ 342 RegLiSlope 0;
BA_ "GenSigSendType" SG_ 342 RevLiReq 0;
BA_ "GenSigSendType" SG_ 342 RevLiSlope 0;
BA_ "GenSigSendType" SG_ 342 RoadInclnQly 0;
BA_ "GenSigStartValue" SG_ 342 RoadInclnQly 1;
BA_ "GenSigSendType" SG_ 342 RoadInclnRoadIncln 0;
BA_ "GenSigSendType" SG_ 338 ServiceModeSync 0;
BA_ "GenSigSendType" SG_ 338 SingleWipeReq 0;
BA_ "GenSigSendType" SG_ 336 SnsrLiSnvty 0;
BA_ "GenSigSendType" SG_ 336 SteerWhlLocCarCfgForDCU 0;
BA_ "GenSigSendType" SG_ 336 TotalDistanceGS 0;
BA_ "GenSigSendType" SG_ 336 TrOpenerBtnAcvtnReq 0;
BA_ "GenSigSendType" SG_ 336 TrlrLampChkReq 1;
BA_ "GenSigSendType" SG_ 336 TwbrFoldFromHMI 1;
BA_ "GenSigSendType" SG_ 336 TwliBriSts 0;
BA_ "GenSigSendType" SG_ 338 UsageAuthDriverAuthChk1 0;
BA_ "GenSigSendType" SG_ 338 UsageAuthDriverAuthChk2 0;
BA_ "GenSigSendType" SG_ 338 UsageModeAvailableSync 0;
BA_ "GenSigSendType" SG_ 338 UsageModeAwakeSync 0;
BA_ "GenSigSendType" SG_ 338 UsageModeConvenienceSync 0;
BA_ "GenSigSendType" SG_ 338 UsageModeDrivingSync 0;
BA_ "GenSigSendType" SG_ 336 UsageModeGS 0;
BA_ "GenSigSendType" SG_ 338 UsageModeMovableSync 0;
BA_ "GenSigSendType" SG_ 338 UsageModeResponsiveSync 0;
BA_ "GenSigSendType" SG_ 336 VehAlrmDstbc 0;
BA_ "GenSigSendType" SG_ 336 VehAlrmExtReq 0;
BA_ "GenSigSendType" SG_ 336 VehAlrmPasDeactvnReq 0;
BA_ "GenSigSendType" SG_ 336 VehAlrmRednSts 0;
BA_ "GenSigSendType" SG_ 338 VehModMngmntSigDCUCarModeSts 0;
BA_ "GenSigSendType" SG_ 338 VehModMngmntSigDCUCarModeSubType 0;
BA_ "GenSigSendType" SG_ 338 VehModMngmntSigDCUElecEnergyLvlDCU 0;
BA_ "GenSigSendType" SG_ 338 VehModMngmntSigDCUElecPowerLvlDCU 0;
BA_ "GenSigSendType" SG_ 338 VehModMngmntSigDCUReserved1 0;
BA_ "GenSigSendType" SG_ 338 VehModMngmntSigDCUReserved2 0;
BA_ "GenSigSendType" SG_ 338 VehModMngmntSigDCUUsageModeSts 0;
BA_ "GenSigSendType" SG_ 336 VehTypeIfSPA2 0;
BA_ "GenSigSendType" SG_ 336 VehicleBatteryVoltageGS 0;
BA_ "GenSigSendType" SG_ 336 VehicleSpeedGS 0;
BA_ "GenSigSendType" SG_ 342 WasherFrontReq 0;
BA_ "GenSigSendType" SG_ 342 WasherRearReq 0;
BA_ "GenSigSendType" SG_ 338 WinFunctnAvailbltySig 0;
BA_ "GenSigSendType" SG_ 336 WindowsFuncCarCfgPinchProtectionLvl 0;
BA_ "GenSigSendType" SG_ 336 WindowsFuncCarCfgReserved0 0;
BA_ "GenSigSendType" SG_ 336 WindowsFuncCarCfgTailgateWindowTintType 0;
BA_ "GenSigSendType" SG_ 336 WindowsFuncCarCfgWindowsGlassType 0;
BA_ "GenSigSendType" SG_ 342 WiprFrntSrvModReq 0;
BA_ "GenSigSendType" SG_ 342 WiprMotIntlCmd 0;

VAL_ 336 AccrPedlPsdSts 0 "AccrPedlPsdSts_NotPsd" 1 "AccrPedlPsdSts_Psd";
VAL_ 336 BltRmnTelltl 0 "Trig1_NoTrig" 1 "Trig1_Trig";
VAL_ 336 ChdProtnActvnReqDoorDrvrRe 0 "OnOff1_Off" 1 "OnOff1_On";
VAL_ 336 ChdProtnActvnReqDoorPass 0 "OnOff1_Off" 1 "OnOff1_On";
VAL_ 336 ChdProtnActvnReqDoorPassRe 0 "OnOff1_Off" 1 "OnOff1_On";
VAL_ 336 DblLckDi 0 "OnOff1_Off" 1 "OnOff1_On";
VAL_ 336 DrvrDesDir1 0 "DrvrDesDir1_Undefd" 1 "DrvrDesDir1_Fwd" 2 "DrvrDesDir1_Rvs" 3 "DrvrDesDir1_Neut" 4 "DrvrDesDir1_Resd0" 5 "DrvrDesDir1_Resd1" 6 "DrvrDesDir1_Resd2" 7 "DrvrDesDir1_Resd3";
VAL_ 336 DynCfgStrWhlPosnForUSS 0 "DynCfgStrWhlPosnForUSS_LHD" 1 "DynCfgStrWhlPosnForUSS_RHD";
VAL_ 336 DynCfgVehTypForUSS 0 "DynCfgVehTypForUSS_Undefined" 1 "DynCfgVehTypForUSS_P519" 2 "DynCfgVehTypForUSS_V536" 3 "DynCfgVehTypForUSS_V551" 4 "DynCfgVehTypForUSS_P61A" 5 "DynCfgVehTypForUSS_Resd1" 6 "DynCfgVehTypForUSS_Resd2" 7 "DynCfgVehTypForUSS_Resd3" 8 "DynCfgVehTypForUSS_Resd4" 9 "DynCfgVehTypForUSS_Resd5" 10 "DynCfgVehTypForUSS_Resd6" 11 "DynCfgVehTypForUSS_Resd7" 12 "DynCfgVehTypForUSS_Resd8" 13 "DynCfgVehTypForUSS_Resd9" 14 "DynCfgVehTypForUSS_Resd10" 15 "DynCfgVehTypForUSS_Resd11";
VAL_ 336 FrntWiprReq 0 "FrntWiprReq_Off" 1 "FrntWiprReq_Auto" 2 "FrntWiprReq_Low" 3 "FrntWiprReq_High";
VAL_ 336 FwdLookCamHeatingReq 0 "Boolean_FALSE" 1 "Boolean_TRUE";
VAL_ 336 GlvBoxRelsBtnPsd 0 "PsdNotPsd1_NotPsd" 1 "PsdNotPsd1_Psd";
VAL_ 336 HMISts 0 "HMISts_HMINok" 1 "HMISts_HMIOk" 2 "HMISts_Resd1" 3 "HMISts_Resd2";
VAL_ 336 LcmaIndcnDrvr 0 "LcmaIndcn_NoLcmaWarn" 1 "LcmaIndcn_LcmaWarnLvl1" 2 "LcmaIndcn_NotUsed" 3 "LcmaIndcn_LcmaWarnLvl2";
VAL_ 336 LcmaIndcnPass 0 "LcmaIndcn_NoLcmaWarn" 1 "LcmaIndcn_LcmaWarnLvl1" 2 "LcmaIndcn_NotUsed" 3 "LcmaIndcn_LcmaWarnLvl2";
VAL_ 336 LockgExtReqLockActv 0 "LockActvnSafe1_LockActvnOff" 1 "LockActvnSafe1_LockActvnUnlck" 2 "LockActvnSafe1_LockActvnLock" 3 "LockActvnSafe1_LockActvnSafe" 4 "LockActvnSafe1_LockActvnUnlckByCrash1" 8 "LockActvnSafe1_LockActvnUnlckByCrash2" 12 "LockActvnSafe1_LockActvnUnlckByCrash0" 13 "LockActvnSafe1_LockActvnUnlckByCrash4" 14 "LockActvnSafe1_LockActvnUnlckByCrash3";
VAL_ 336 LockgPrsnlReq 0 "OnOffNoReq_NoReq" 1 "OnOffNoReq_On" 2 "OnOffNoReq_Off";
VAL_ 336 LockgSetgFbAudibleFeedback 0 "Boolean_FALSE" 1 "Boolean_TRUE";
VAL_ 336 LockgSetgFbVisibleFeedback 0 "Boolean_FALSE" 1 "Boolean_TRUE";
VAL_ 336 LockgSetgPasLockBySpeed 0 "Boolean_FALSE" 1 "Boolean_TRUE";
VAL_ 336 LockgSetgPasLockWalkAway 0 "Boolean_FALSE" 1 "Boolean_TRUE";
VAL_ 336 LockgSetgPasUnlockApproach 0 "Boolean_FALSE" 1 "Boolean_TRUE";
VAL_ 336 LockgSetgSngDoorUnlck 0 "Boolean_FALSE" 1 "Boolean_TRUE";
VAL_ 336 MirrAutoDimSetg 0 "OnOffSetg_Disabled" 1 "OnOffSetg_Enabled";
VAL_ 336 MirrCmdRecAtDrvrMirrFoldCmd 0 "MirrFoldCmdTyp_Idle" 1 "MirrFoldCmdTyp_FoldIn" 2 "MirrFoldCmdTyp_FoldOut";
VAL_ 336 MirrCmdRecAtDrvrMirrPosAdjCmd 0 "MirrAdjCmdTyp_Idle" 1 "MirrAdjCmdTyp_Up" 2 "MirrAdjCmdTyp_Dwn" 3 "MirrAdjCmdTyp_Le" 4 "MirrAdjCmdTyp_Ri";
VAL_ 336 MirrCmdRecAtPassMirrFoldCmd 0 "MirrFoldCmdTyp_Idle" 1 "MirrFoldCmdTyp_FoldIn" 2 "MirrFoldCmdTyp_FoldOut";
VAL_ 336 MirrCmdRecAtPassMirrPosAdjCmd 0 "MirrAdjCmdTyp_Idle" 1 "MirrAdjCmdTyp_Up" 2 "MirrAdjCmdTyp_Dwn" 3 "MirrAdjCmdTyp_Le" 4 "MirrAdjCmdTyp_Ri";
VAL_ 336 MirrDfrstType 0 "MirrDfrstType_Init" 1 "MirrDfrstType_MirrDfrstNoCamNozHeatg" 2 "MirrDfrstType_MirrDfrstCamNozHeatg";
VAL_ 336 MirrorDefrosterReq 0 "OnOffNoReq_NoReq" 1 "OnOffNoReq_On" 2 "OnOffNoReq_Off";
VAL_ 336 MirrorFuncCarCfgExtRearViewMirrorType 0 "ExtRearViewMirrorType_Init" 1 "ExtRearViewMirrorType_NonRetractableMirrors" 2 "ExtRearViewMirrorType_RetractableMirrors" 3 "ExtRearViewMirrorType_RetractableMirrorsFrameless";
VAL_ 336 MirrorFuncCarCfgRearViewMirrorDimType 0 "RearViewMirrorDimType_Init" 1 "RearViewMirrorDimType_ManualDim" 2 "RearViewMirrorDimType_AutomaticDimInnerMirror" 3 "RearViewMirrorDimType_AutomaticDimInnerOuterMirror" 4 "RearViewMirrorDimType_AutomaticDimInnerAndOutrDrvrMirror";
VAL_ 336 MirrorFuncCarCfgRearViewMirrorMemType 0 "RearViewMirrorMemoryType_Init" 1 "RearViewMirrorMemoryType_NoMirrorMemory" 2 "RearViewMirrorMemoryType_MirrorMemory";
VAL_ 336 PassAirbLmpReqPassAirbLmpReq 0 "PassAirbLmpReq_PadPaeOff" 1 "PassAirbLmpReq_PadOffPaeOn" 2 "PassAirbLmpReq_PadOnPaeOff" 3 "PassAirbLmpReq_PadOnPaeOn";
VAL_ 336 SnsrLiSnvty 0 "SnsrLiSnvty_SnvtyLo1" 1 "SnsrLiSnvty_SnvtyNorm1" 2 "SnsrLiSnvty_SnvtyHi1" 3 "SnsrLiSnvty_SnvtyLo2" 4 "SnsrLiSnvty_SnvtyNorm2" 5 "SnsrLiSnvty_SnvtyHi2" 6 "SnsrLiSnvty_Resd" 7 "SnsrLiSnvty_NotVld";
VAL_ 336 SteerWhlLocCarCfgForDCU 0 "SteerWhlLocCarCfgForDCU_Init" 1 "SteerWhlLocCarCfgForDCU_LeftHandDrive" 2 "SteerWhlLocCarCfgForDCU_RightHandDrive";
VAL_ 336 TrlrLampChkReq 0 "StrtStopReq1_Idle" 1 "StrtStopReq1_StrtReq" 2 "StrtStopReq1_StopReq" 3 "StrtStopReq1_Resd";
VAL_ 336 TrOpenerBtnAcvtnReq 0 "OpenClsStop_Idle" 1 "OpenClsStop_Open" 2 "OpenClsStop_Cls" 3 "OpenClsStop_Stop";
VAL_ 336 TwbrFoldFromHMI 0 "TwbrFoldRem_FoldIn" 1 "TwbrFoldRem_FoldOut" 2 "TwbrFoldRem_Idle" 3 "TwbrFoldRem_NotUsed";
VAL_ 336 TwliBriSts 0 "TwliBriSts1_Night" 1 "TwliBriSts1_Day";
VAL_ 336 VehAlrmExtReq 0 "VehAlrmExtReq_Idle" 1 "VehAlrmExtReq_Disarm" 2 "VehAlrmExtReq_Arm" 3 "VehAlrmExtReq_Actvt";
VAL_ 336 VehAlrmPasDeactvnReq 0 "OnOffSafe1_OnOffSafeInvld1" 1 "OnOffSafe1_OnOffSafeOn" 2 "OnOffSafe1_OnOffSafeOff" 3 "OnOffSafe1_OnOffSafeInvld2";
VAL_ 336 VehAlrmRednSts 0 "OnOffSafe1_OnOffSafeInvld1" 1 "OnOffSafe1_OnOffSafeOn" 2 "OnOffSafe1_OnOffSafeOff" 3 "OnOffSafe1_OnOffSafeInvld2";
VAL_ 336 VehTypeIfSPA2 0 "VehTypeIfSPA2_Idle" 1 "VehTypeIfSPA2_P519" 2 "VehTypeIfSPA2_V536" 3 "VehTypeIfSPA2_V551" 4 "VehTypeIfSPA2_P61A";
VAL_ 336 WindowsFuncCarCfgPinchProtectionLvl 0 "PinchProtnLvl_Init" 1 "PinchProtnLvl_Standard" 2 "PinchProtnLvl_Enhanced";
VAL_ 336 WindowsFuncCarCfgReserved0 0 "Resrvd0_reservd0" 1 "Resrvd0_reservd1";
VAL_ 336 WindowsFuncCarCfgTailgateWindowTintType 0 "WinTailGateTintType_Init" 1 "WinTailGateTintType_NotTintedTailGateWindow" 2 "WinTailGateTintType_TintedTailGateWindow";
VAL_ 336 WindowsFuncCarCfgWindowsGlassType 0 "WinGlassType_Init" 1 "WinGlassType_TemperedGlassSideAndRearWindows" 2 "WinGlassType_LaminatedGlassSideAndRearWindows";
VAL_ 338 ApplIdStsIntrEth 0 "AIDEnum_AID0" 1 "AIDEnum_AID1" 2 "AIDEnum_AID2" 3 "AIDEnum_AID3" 4 "AIDEnum_AID4" 5 "AIDEnum_AID5" 6 "AIDEnum_AID6" 7 "AIDEnum_NoAID";
VAL_ 338 BltLockStDrvr 0 "BltLockSt1_Unlock" 1 "BltLockSt1_Lock";
VAL_ 338 CarModeSyncCarMode 0 "CarMode_CarModeNormal" 1 "CarMode_CarModeTransport" 2 "CarMode_CarModeFactory" 3 "CarMode_CarModeDyno" 4 "CarMode_CarModeShow" 5 "CarMode_Spare2" 6 "CarMode_Undefined";
VAL_ 338 CarModeSyncCarModeSubtype 0 "CarModeSubtype_Normal" 1 "CarModeSubtype_FactoryPaused" 2 "CarModeSubtype_FactoryDriving" 3 "CarModeSubtype_TransportDriving" 4 "CarModeSubtype_TwoWheelDyno" 5 "CarModeSubtype_FourWheelDyno" 6 "CarModeSubtype_Reserve1" 7 "CarModeSubtype_Reserve2";
VAL_ 338 CrashModeSync 0 "OnOff1_Off" 1 "OnOff1_On";
VAL_ 338 GearLvlIndcn 0 "GearLvrIndcn2_ParkIndcn" 1 "GearLvrIndcn2_RvsIndcn" 2 "GearLvrIndcn2_NeutIndcn" 3 "GearLvrIndcn2_DrvIndcn" 4 "GearLvrIndcn2_ManModeIndcn" 5 "GearLvrIndcn2_Resd1" 6 "GearLvrIndcn2_Resd2" 7 "GearLvrIndcn2_Undefd";
VAL_ 338 IntrLiUsrPrsntDrvrSeat 0 "OccptDetdSts_Ukwn" 1 "OccptDetdSts_PosnNotPrsnt" 2 "OccptDetdSts_NotDetd" 3 "OccptDetdSts_Detd";
VAL_ 338 IntrLiUsrPrsntPassSeat 0 "OccptDetdSts_Ukwn" 1 "OccptDetdSts_PosnNotPrsnt" 2 "OccptDetdSts_NotDetd" 3 "OccptDetdSts_Detd";
VAL_ 338 IntrLiUsrPrsntReCentrSeat2nd 0 "OccptDetdSts_Ukwn" 1 "OccptDetdSts_PosnNotPrsnt" 2 "OccptDetdSts_NotDetd" 3 "OccptDetdSts_Detd";
VAL_ 338 IntrLiUsrPrsntReDrvrSeat2nd 0 "OccptDetdSts_Ukwn" 1 "OccptDetdSts_PosnNotPrsnt" 2 "OccptDetdSts_NotDetd" 3 "OccptDetdSts_Detd";
VAL_ 338 IntrLiUsrPrsntReDrvrSeat3nd 0 "OccptDetdSts_Ukwn" 1 "OccptDetdSts_PosnNotPrsnt" 2 "OccptDetdSts_NotDetd" 3 "OccptDetdSts_Detd";
VAL_ 338 IntrLiUsrPrsntRePassSeat2nd 0 "OccptDetdSts_Ukwn" 1 "OccptDetdSts_PosnNotPrsnt" 2 "OccptDetdSts_NotDetd" 3 "OccptDetdSts_Detd";
VAL_ 338 IntrLiUsrPrsntRePassSeat3nd 0 "OccptDetdSts_Ukwn" 1 "OccptDetdSts_PosnNotPrsnt" 2 "OccptDetdSts_NotDetd" 3 "OccptDetdSts_Detd";
VAL_ 338 IntrLiUsrPrsntTrAr 0 "OccptDetdSts_Ukwn" 1 "OccptDetdSts_PosnNotPrsnt" 2 "OccptDetdSts_NotDetd" 3 "OccptDetdSts_Detd";
VAL_ 338 PinionAgPinionSteerAg1Qf 0 "GenQf1_UndefindDataAccur" 1 "GenQf1_TmpUndefdData" 2 "GenQf1_DataAccurNotWithinSpcn" 3 "GenQf1_AccurData";
VAL_ 338 PowerControllerRlySyncADPMWakeUpSync 0 "OnOff1_Off" 1 "OnOff1_On";
VAL_ 338 PowerControllerRlySyncAUDWakeUpSync 0 "OnOff1_Off" 1 "OnOff1_On";
VAL_ 338 PowerControllerRlySyncClimateActuatorRelaySync 0 "OnOff1_Off" 1 "OnOff1_On";
VAL_ 338 PowerControllerRlySyncDIMWakeUpSync 0 "OnOff1_Off" 1 "OnOff1_On";
VAL_ 338 PowerControllerRlySyncExteriorLightRelaySync 0 "OnOff1_Off" 1 "OnOff1_On";
VAL_ 338 PowerControllerRlySyncIgnitionPowerRelaySync 0 "OnOff1_Off" 1 "OnOff1_On";
VAL_ 338 PowerControllerRlySyncSUMWakeUpSync 0 "OnOff1_Off" 1 "OnOff1_On";
VAL_ 338 PreApduSndIntrEth 0 "Boolean_FALSE" 1 "Boolean_TRUE";
VAL_ 338 ServiceModeSync 0 "OnOff1_Off" 1 "OnOff1_On";
VAL_ 338 SingleWipeReq 0 "OnOffNoReq_NoReq" 1 "OnOffNoReq_On" 2 "OnOffNoReq_Off";
VAL_ 338 UsageModeAvailableSync 0 "OnOff1_Off" 1 "OnOff1_On";
VAL_ 338 UsageModeAwakeSync 0 "OnOff1_Off" 1 "OnOff1_On";
VAL_ 338 UsageModeConvenienceSync 0 "OnOff1_Off" 1 "OnOff1_On";
VAL_ 338 UsageModeDrivingSync 0 "OnOff1_Off" 1 "OnOff1_On";
VAL_ 338 UsageModeMovableSync 0 "OnOff1_Off" 1 "OnOff1_On";
VAL_ 338 UsageModeResponsiveSync 0 "OnOff1_Off" 1 "OnOff1_On";
VAL_ 338 VehModMngmntSigDCUCarModeSts 0 "CarModeTypeDCU_Normal" 1 "CarModeTypeDCU_Transport" 2 "CarModeTypeDCU_Factory" 3 "CarModeTypeDCU_Dyno" 4 "CarModeTypeDCU_Show";
VAL_ 338 VehModMngmntSigDCUCarModeSubType 0 "CarModeSubTypeDCU_Normal" 1 "CarModeSubTypeDCU_TransportDriving" 2 "CarModeSubTypeDCU_FactoryDriving";
VAL_ 338 VehModMngmntSigDCUElecEnergyLvlDCU 0 "ElecEnergyLvlDCU_Normal" 1 "ElecEnergyLvlDCU_Critical" 2 "ElecEnergyLvlDCU_Unlimited";
VAL_ 338 VehModMngmntSigDCUElecPowerLvlDCU 0 "ElecPowerLvlDCU_Normal" 1 "ElecPowerLvlDCU_LowVoltageCrank" 2 "ElecPowerLvlDCU_OverVoltage" 3 "ElecPowerLvlDCU_Critical" 4 "ElecPowerLvlDCU_PreCrash";
VAL_ 338 VehModMngmntSigDCUUsageModeSts 0 "UsageModeTypeDCU_Awake" 1 "UsageModeTypeDCU_Responsive" 2 "UsageModeTypeDCU_Available" 3 "UsageModeTypeDCU_Convenience" 4 "UsageModeTypeDCU_Driving" 5 "UsageModeTypeDCU_Movable";
VAL_ 338 WinFunctnAvailbltySig 0 "WinFunctnAvailbltySig_Disabled" 1 "WinFunctnAvailbltySig_LimitedFunction" 2 "WinFunctnAvailbltySig_SupervisedMode" 3 "WinFunctnAvailbltySig_FullyFunctional" 4 "WinFunctnAvailbltySig_FactoryDriving" 5 "WinFunctnAvailbltySig_TransportDriving" 6 "WinFunctnAvailbltySig_Cranking" 7 "WinFunctnAvailbltySig_Resvd1";
VAL_ 341 ExLiLpHiDefHozlLeDLPHozlLeEna 0 "Boolean_FALSE" 1 "Boolean_TRUE";
VAL_ 341 ExLiLpHiDefHozlRiDLPHozlRiEna 0 "Boolean_FALSE" 1 "Boolean_TRUE";
VAL_ 341 ExLiLpHiDefLiLeTrafficSide 0 "SideInfo_Unkwn" 1 "SideInfo_Left" 2 "SideInfo_Right" 3 "SideInfo_Reserved";
VAL_ 341 ExLiLpHiDefLiRiTrafficSide 0 "SideInfo_Unkwn" 1 "SideInfo_Left" 2 "SideInfo_Right" 3 "SideInfo_Reserved";
VAL_ 342 DoorModuleCarCfgDDMMountInfo 0 "DriverDoorModule_Init" 1 "DriverDoorModule_Mounted" 2 "DriverDoorModule_NotMounted";
VAL_ 342 DoorModuleCarCfgPDMMountInfo 0 "PassengerDoorModule_Init" 1 "PassengerDoorModule_Mounted" 2 "PassengerDoorModule_NotMounted";
VAL_ 342 DoorModuleCarCfgRDDMMountInfo 0 "RearDriverDoorModule_Init" 1 "RearDriverDoorModule_Mounted" 2 "RearDriverDoorModule_NotMounted";
VAL_ 342 DoorModuleCarCfgRPDMMountInfo 0 "RearPassengerDoorModule_Init" 1 "RearPassengerDoorModule_Mounted" 2 "RearPassengerDoorModule_NotMounted";
VAL_ 342 ExLiHpHdlampConcealLeEna 0 "Boolean_FALSE" 1 "Boolean_TRUE";
VAL_ 342 ExLiHpHdlampConcealLeMotSply 0 "Boolean_FALSE" 1 "Boolean_TRUE";
VAL_ 342 ExLiHpHdlampConcealLePosnReq 0 "HdlampConcealPosnReq_Closed" 1 "HdlampConcealPosnReq_Open";
VAL_ 342 ExLiHpHdlampConcealLeRefForce 0 "Boolean_FALSE" 1 "Boolean_TRUE";
VAL_ 342 ExLiHpHdlampConcealLeRefOk 0 "Boolean_FALSE" 1 "Boolean_TRUE";
VAL_ 342 ExLiHpHdlampConcealRiEna 0 "Boolean_FALSE" 1 "Boolean_TRUE";
VAL_ 342 ExLiHpHdlampConcealRiMotSply 0 "Boolean_FALSE" 1 "Boolean_TRUE";
VAL_ 342 ExLiHpHdlampConcealRiPosnReq 0 "HdlampConcealPosnReq_Closed" 1 "HdlampConcealPosnReq_Open";
VAL_ 342 ExLiHpHdlampConcealRiRefForce 0 "Boolean_FALSE" 1 "Boolean_TRUE";
VAL_ 342 ExLiHpHdlampConcealRiRefOk 0 "Boolean_FALSE" 1 "Boolean_TRUE";
VAL_ 342 ExLiHpHdlampDrlPosLeShape 0 "DrlPosShape_Off" 1 "DrlPosShape_PosOn" 2 "DrlPosShape_DrlOn" 3 "DrlPosShape_PosAndDrlOn";
VAL_ 342 ExLiHpHdlampDrlPosRiShape 0 "DrlPosShape_Off" 1 "DrlPosShape_PosOn" 2 "DrlPosShape_DrlOn" 3 "DrlPosShape_PosAndDrlOn";
VAL_ 342 ExLiHpHdlampSmlLeSideMkrLe 0 "OnOff1_Off" 1 "OnOff1_On";
VAL_ 342 ExLiHpHdlampSmlRiSideMkrRi 0 "OnOff1_Off" 1 "OnOff1_On";
VAL_ 342 ExLiHpHiDefCalibrationStsLe 0 "HdCalibrationSts_Uknwn" 1 "HdCalibrationSts_Actv" 2 "HdCalibrationSts_Cmpl" 3 "HdCalibrationSts_Failr";
VAL_ 342 ExLiHpHiDefCalibrationStsRi 0 "HdCalibrationSts_Uknwn" 1 "HdCalibrationSts_Actv" 2 "HdCalibrationSts_Cmpl" 3 "HdCalibrationSts_Failr";
VAL_ 342 ExLiHpRearSmlLi 0 "OnOff1_Off" 1 "OnOff1_On";
VAL_ 342 ExLiHpTrlrLiActvnBrk 0 "OnOff1_Off" 1 "OnOff1_On";
VAL_ 342 ExLiHpTrlrLiActvnFog 0 "OnOff1_Off" 1 "OnOff1_On";
VAL_ 342 ExLiHpTrlrLiActvnPosn 0 "OnOff1_Off" 1 "OnOff1_On";
VAL_ 342 ExLiHpTrlrLiActvnRvsg 0 "OnOff1_Off" 1 "OnOff1_On";
VAL_ 342 ExLiLpHdlampLiLeBeamLeShape 0 "BeamShape_Off" 1 "BeamShape_Flat" 2 "BeamShape_LB" 3 "BeamShape_L" 4 "BeamShape_Full" 5 "BeamShape_FlatAndHBSpot" 6 "BeamShape_LBAndHBSpot" 7 "BeamShape_HBSpot" 8 "BeamShape_Reserved1" 9 "BeamShape_Reserved2" 10 "BeamShape_Reserved3" 11 "BeamShape_Reserved4" 12 "BeamShape_Reserved5" 13 "BeamShape_Reserved6" 14 "BeamShape_Reserved7" 15 "BeamShape_Reserved8";
VAL_ 342 ExLiLpHdlampLiLeLiTrfcSide 0 "SideInfo_Unkwn" 1 "SideInfo_Left" 2 "SideInfo_Right" 3 "SideInfo_Reserved";
VAL_ 342 ExLiLpHdlampLiRiBeamRiShape 0 "BeamShape_Off" 1 "BeamShape_Flat" 2 "BeamShape_LB" 3 "BeamShape_L" 4 "BeamShape_Full" 5 "BeamShape_FlatAndHBSpot" 6 "BeamShape_LBAndHBSpot" 7 "BeamShape_HBSpot" 8 "BeamShape_Reserved1" 9 "BeamShape_Reserved2" 10 "BeamShape_Reserved3" 11 "BeamShape_Reserved4" 12 "BeamShape_Reserved5" 13 "BeamShape_Reserved6" 14 "BeamShape_Reserved7" 15 "BeamShape_Reserved8";
VAL_ 342 ExLiLpHdlampLiRiLiTrfcSide 0 "SideInfo_Unkwn" 1 "SideInfo_Left" 2 "SideInfo_Right" 3 "SideInfo_Reserved";
VAL_ 342 ExLiLpHdlampLvlLeLvlLeEna 0 "Boolean_FALSE" 1 "Boolean_TRUE";
VAL_ 342 ExLiLpHdlampLvlLeLvlLeMotSply 0 "Boolean_FALSE" 1 "Boolean_TRUE";
VAL_ 342 ExLiLpHdlampLvlLeLvlLeRefForce 0 "Boolean_FALSE" 1 "Boolean_TRUE";
VAL_ 342 ExLiLpHdlampLvlLeLvlLeRefOk 0 "Boolean_FALSE" 1 "Boolean_TRUE";
VAL_ 342 ExLiLpHdlampLvlRiLvlRiEna 0 "Boolean_FALSE" 1 "Boolean_TRUE";
VAL_ 342 ExLiLpHdlampLvlRiLvlRiMotSply 0 "Boolean_FALSE" 1 "Boolean_TRUE";
VAL_ 342 ExLiLpHdlampLvlRiLvlRiRefForce 0 "Boolean_FALSE" 1 "Boolean_TRUE";
VAL_ 342 ExLiLpHdlampLvlRiLvlRiRefOk 0 "Boolean_FALSE" 1 "Boolean_TRUE";
VAL_ 342 LCMACarCfgBlisInfoSys 0 "BlisInfoSys_Init" 1 "BlisInfoSys_NoBLIS" 2 "BlisInfoSys_BLISwithCTA" 3 "BlisInfoSys_SensorAvlButNoBLIS" 4 "BlisInfoSys_BLISwithCTAandAud";
VAL_ 342 PAPGearShiftrIntv 0 "GearShiftrIntv_Undefined" 1 "GearShiftrIntv_NoGearShifrIntv" 2 "GearShiftrIntv_GearShifrIntv" 3 "GearShiftrIntv_Resd1" 4 "GearShiftrIntv_Resd2" 5 "GearShiftrIntv_Resd3" 6 "GearShiftrIntv_Resd4" 7 "GearShiftrIntv_Resd5";
VAL_ 342 PAPLoSpdMod 0 "LoSpdMod_Undefined" 1 "LoSpdMod_Inactive" 2 "LoSpdMod_Active" 3 "LoSpdMod_Resd1" 4 "LoSpdMod_Resd2" 5 "LoSpdMod_Resd3" 6 "LoSpdMod_Resd4" 7 "LoSpdMod_Resd5";
VAL_ 342 ReFogLiReq 0 "Side_Off" 1 "Side_Left" 2 "Side_Right" 3 "Side_LeftAndRight";
VAL_ 342 RegLiReq 0 "OnOff1_Off" 1 "OnOff1_On";
VAL_ 342 RePosLiReq 0 "OnOffAlt_Off" 1 "OnOffAlt_On" 2 "OnOffAlt_Alt1" 3 "OnOffAlt_Alt2";
VAL_ 342 RevLiReq 0 "OnOff1_Off" 1 "OnOff1_On";
VAL_ 342 RoadInclnQly 0 "Qly2_Flt" 1 "Qly2_NoInfo" 2 "Qly2_Vld";
VAL_ 342 WasherFrontReq 0 "Washer_Unknown" 1 "Washer_WasherOff" 2 "Washer_WasherOn";
VAL_ 342 WasherRearReq 0 "Washer_Unknown" 1 "Washer_WasherOff" 2 "Washer_WasherOn";
VAL_ 342 WiprFrntSrvModReq 0 "WiprFrntSrvModReq_NoActn" 1 "WiprFrntSrvModReq_ActvtSrvPosn" 2 "WiprFrntSrvModReq_DeActvtSrvPosn";
VAL_ 342 WiprMotIntlCmd 0 "WipgSpdIntlFromHmi_Posn0" 1 "WipgSpdIntlFromHmi_Posn1" 2 "WipgSpdIntlFromHmi_Posn2" 3 "WipgSpdIntlFromHmi_Posn3" 4 "WipgSpdIntlFromHmi_Posn4" 5 "WipgSpdIntlFromHmi_Posn5" 6 "WipgSpdIntlFromHmi_Posn6" 7 "WipgSpdIntlFromHmi_Posn7";
VAL_ 344 ExLiLpHdlampCornLeReq 0 "OnOff1_Off" 1 "OnOff1_On";
VAL_ 344 ExLiLpHdlampCornRiReq 0 "OnOff1_Off" 1 "OnOff1_On";
VAL_ 344 ExLiLpHdlampHozlLeHozlLeEna 0 "Boolean_FALSE" 1 "Boolean_TRUE";
VAL_ 344 ExLiLpHdlampHozlLeHozlLeMotSply 0 "Boolean_FALSE" 1 "Boolean_TRUE";
VAL_ 344 ExLiLpHdlampHozlLeHozlLeRefForce 0 "Boolean_FALSE" 1 "Boolean_TRUE";
VAL_ 344 ExLiLpHdlampHozlLeHozlLeRefOk 0 "Boolean_FALSE" 1 "Boolean_TRUE";
VAL_ 344 ExLiLpHdlampHozlRiHozlRiEna 0 "Boolean_FALSE" 1 "Boolean_TRUE";
VAL_ 344 ExLiLpHdlampHozlRiHozlRiMotSply 0 "Boolean_FALSE" 1 "Boolean_TRUE";
VAL_ 344 ExLiLpHdlampHozlRiHozlRiRefForce 0 "Boolean_FALSE" 1 "Boolean_TRUE";
VAL_ 344 ExLiLpHdlampHozlRiHozlRiRefOk 0 "Boolean_FALSE" 1 "Boolean_TRUE";
VAL_ 345 ExLiHpTurnIndcrLiReqDirection 0 "Side_Off" 1 "Side_Left" 2 "Side_Right" 3 "Side_LeftAndRight";
SIG_GROUP_ 338 ApduRespLpcFromIntrEth 1 : ApduRespLpcFromIntrEthByte0 ApduRespLpcFromIntrEthByte1 ApduRespLpcFromIntrEthByte2 ApduRespLpcFromIntrEthByte3 ApduRespLpcFromIntrEthByte4 ApduRespLpcFromIntrEthByte5 ApduRespLpcFromIntrEthByte6 ApduRespLpcFromIntrEthByte7;
SIG_GROUP_ 338 CarModeSync 1 : CarModeSyncCarMode CarModeSyncCarModeSubtype;
SIG_GROUP_ 336 ChdProtnActvnReq 1 : ChdProtnActvnReqDoorDrvrRe ChdProtnActvnReqDoorPass ChdProtnActvnReqDoorPassRe;
SIG_GROUP_ 342 DoorModuleCarCfg 1 : DoorModuleCarCfgDDMMountInfo DoorModuleCarCfgPDMMountInfo DoorModuleCarCfgRDDMMountInfo DoorModuleCarCfgRPDMMountInfo;
SIG_GROUP_ 342 ExLiHpHdlampConcealLe 1 : ExLiHpHdlampConcealLeChks ExLiHpHdlampConcealLeCntr ExLiHpHdlampConcealLeEna ExLiHpHdlampConcealLeMotSply ExLiHpHdlampConcealLePosnReq ExLiHpHdlampConcealLeRefForce ExLiHpHdlampConcealLeRefOk ExLiHpHdlampConcealLeSpd;
SIG_GROUP_ 342 ExLiHpHdlampConcealRi 1 : ExLiHpHdlampConcealRiChks ExLiHpHdlampConcealRiCntr ExLiHpHdlampConcealRiEna ExLiHpHdlampConcealRiMotSply ExLiHpHdlampConcealRiPosnReq ExLiHpHdlampConcealRiRefForce ExLiHpHdlampConcealRiRefOk ExLiHpHdlampConcealRiSpd;
SIG_GROUP_ 344 ExLiHpHdlampDim1 1 : ExLiHpHdlampDim1BottomAg ExLiHpHdlampDim1LeAgPrpty ExLiHpHdlampDim1LeLampLeAg ExLiHpHdlampDim1LeLampRiAg ExLiHpHdlampDim1ObjctZoneIntens ExLiHpHdlampDim1RiAgPrpty ExLiHpHdlampDim1RiLampLeAg ExLiHpHdlampDim1RiLampRiAg;
SIG_GROUP_ 344 ExLiHpHdlampDim2 1 : ExLiHpHdlampDim2BottomAg ExLiHpHdlampDim2LeAgPrpty ExLiHpHdlampDim2LeLampLeAg ExLiHpHdlampDim2LeLampRiAg ExLiHpHdlampDim2ObjctZoneIntens ExLiHpHdlampDim2RiAgPrpty ExLiHpHdlampDim2RiLampLeAg ExLiHpHdlampDim2RiLampRiAg;
SIG_GROUP_ 344 ExLiHpHdlampDim3 1 : ExLiHpHdlampDim3BottomAg ExLiHpHdlampDim3LeAgPrpty ExLiHpHdlampDim3LeLampLeAg ExLiHpHdlampDim3LeLampRiAg ExLiHpHdlampDim3ObjctZoneIntens ExLiHpHdlampDim3RiAgPrpty ExLiHpHdlampDim3RiLampLeAg ExLiHpHdlampDim3RiLampRiAg;
SIG_GROUP_ 342 ExLiHpHdlampDrlPosLe 1 : ExLiHpHdlampDrlPosLeFocus ExLiHpHdlampDrlPosLeShape ExLiHpHdlampDrlPosLeSlope ExLiHpHdlampDrlPosLeTransition;
SIG_GROUP_ 342 ExLiHpHdlampDrlPosRi 1 : ExLiHpHdlampDrlPosRiFocus ExLiHpHdlampDrlPosRiShape ExLiHpHdlampDrlPosRiSlope ExLiHpHdlampDrlPosRiTransition;
SIG_GROUP_ 342 ExLiHpHdlampSmlLe 1 : ExLiHpHdlampSmlLeSideMkrLe ExLiHpHdlampSmlLeSideMkrLeFocus ExLiHpHdlampSmlLeSideMkrLeSlope;
SIG_GROUP_ 342 ExLiHpHdlampSmlRi 1 : ExLiHpHdlampSmlRiSideMkrRi ExLiHpHdlampSmlRiSideMkrRiFocus ExLiHpHdlampSmlRiSideMkrRiSlope;
SIG_GROUP_ 342 ExLiHpTrlrLiActvn 1 : ExLiHpTrlrLiActvnBrk ExLiHpTrlrLiActvnFog ExLiHpTrlrLiActvnPosn ExLiHpTrlrLiActvnRvsg;
SIG_GROUP_ 345 ExLiHpTurnIndcrLiReq 1 : ExLiHpTurnIndcrLiReqActivePeriodTime ExLiHpTurnIndcrLiReqChks ExLiHpTurnIndcrLiReqCntr ExLiHpTurnIndcrLiReqDirection ExLiHpTurnIndcrLiReqInactivePeriodTime ExLiHpTurnIndcrLiReqIndcrSeqDownTi ExLiHpTurnIndcrLiReqIndcrSeqUpTi ExLiHpTurnIndcrLiReqSlopeDwnTi ExLiHpTurnIndcrLiReqSlopeUpTi ExLiHpTurnIndcrLiReqSyncOffTiNanoS ExLiHpTurnIndcrLiReqSyncOffTiS ExLiHpTurnIndcrLiReqSyncOnTiNanS ExLiHpTurnIndcrLiReqSyncOnTiS ExLiHpTurnIndcrLiReqTransition;
SIG_GROUP_ 344 ExLiLpHdlampCornLe 1 : ExLiLpHdlampCornLeFocus ExLiLpHdlampCornLeReq ExLiLpHdlampCornLeSlope;
SIG_GROUP_ 344 ExLiLpHdlampCornRi 1 : ExLiLpHdlampCornRiFocus ExLiLpHdlampCornRiReq ExLiLpHdlampCornRiSlope;
SIG_GROUP_ 344 ExLiLpHdlampHozlLe 1 : ExLiLpHdlampHozlLeHozlLeEna ExLiLpHdlampHozlLeHozlLeMotSply ExLiLpHdlampHozlLeHozlLeRefForce ExLiLpHdlampHozlLeHozlLeRefOk ExLiLpHdlampHozlLeHozlLeReq;
SIG_GROUP_ 344 ExLiLpHdlampHozlRi 1 : ExLiLpHdlampHozlRiHozlRiEna ExLiLpHdlampHozlRiHozlRiMotSply ExLiLpHdlampHozlRiHozlRiRefForce ExLiLpHdlampHozlRiHozlRiRefOk ExLiLpHdlampHozlRiHozlRiReq;
SIG_GROUP_ 343 ExLiLpHdlampKoz1 1 : ExLiLpHdlampKoz1BottomAg ExLiLpHdlampKoz1LeAgPrpty ExLiLpHdlampKoz1LeLampLeAg ExLiLpHdlampKoz1LeLampRiAg ExLiLpHdlampKoz1RiAgPrpty ExLiLpHdlampKoz1RiLampLeAg ExLiLpHdlampKoz1RiLampRiAg;
SIG_GROUP_ 343 ExLiLpHdlampKoz2 1 : ExLiLpHdlampKoz2BottomAg ExLiLpHdlampKoz2LeAgPrpty ExLiLpHdlampKoz2LeLampLeAg ExLiLpHdlampKoz2LeLampRiAg ExLiLpHdlampKoz2RiAgPrpty ExLiLpHdlampKoz2RiLampLeAg ExLiLpHdlampKoz2RiLampRiAg;
SIG_GROUP_ 343 ExLiLpHdlampKoz3 1 : ExLiLpHdlampKoz3BottomAg ExLiLpHdlampKoz3LeAgPrpty ExLiLpHdlampKoz3LeLampLeAg ExLiLpHdlampKoz3LeLampRiAg ExLiLpHdlampKoz3RiAgPrpty ExLiLpHdlampKoz3RiLampLeAg ExLiLpHdlampKoz3RiLampRiAg;
SIG_GROUP_ 343 ExLiLpHdlampKoz4 1 : ExLiLpHdlampKoz4BottomAg ExLiLpHdlampKoz4LeAgPrpty ExLiLpHdlampKoz4LeLampLeAg ExLiLpHdlampKoz4LeLampRiAg ExLiLpHdlampKoz4RiAgPrpty ExLiLpHdlampKoz4RiLampLeAg ExLiLpHdlampKoz4RiLampRiAg;
SIG_GROUP_ 343 ExLiLpHdlampKoz5 1 : ExLiLpHdlampKoz5BottomAg ExLiLpHdlampKoz5LeAgPrpty ExLiLpHdlampKoz5LeLampLeAg ExLiLpHdlampKoz5LeLampRiAg ExLiLpHdlampKoz5RiAgPrpty ExLiLpHdlampKoz5RiLampLeAg ExLiLpHdlampKoz5RiLampRiAg;
SIG_GROUP_ 342 ExLiLpHdlampLiLe 1 : ExLiLpHdlampLiLeBeamLeFocus ExLiLpHdlampLiLeBeamLeShape ExLiLpHdlampLiLeBeamLeSlope ExLiLpHdlampLiLeBeamLeSymbol ExLiLpHdlampLiLeBeamLeTransition ExLiLpHdlampLiLeHeadlampLeChks ExLiLpHdlampLiLeHeadlampLeCntr ExLiLpHdlampLiLeLiTrfcSide;
SIG_GROUP_ 342 ExLiLpHdlampLiRi 1 : ExLiLpHdlampLiRiBeamRiFocus ExLiLpHdlampLiRiBeamRiShape ExLiLpHdlampLiRiBeamRiSlope ExLiLpHdlampLiRiBeamRiSymbol ExLiLpHdlampLiRiBeamRiTransition ExLiLpHdlampLiRiHeadlampRiChks ExLiLpHdlampLiRiHeadlampRiCntr ExLiLpHdlampLiRiLiTrfcSide;
SIG_GROUP_ 342 ExLiLpHdlampLvlLe 1 : ExLiLpHdlampLvlLeLvlLeChks ExLiLpHdlampLvlLeLvlLeCntr ExLiLpHdlampLvlLeLvlLeEna ExLiLpHdlampLvlLeLvlLeMotSply ExLiLpHdlampLvlLeLvlLeRefForce ExLiLpHdlampLvlLeLvlLeRefOk ExLiLpHdlampLvlLeLvlLeReq;
SIG_GROUP_ 342 ExLiLpHdlampLvlRi 1 : ExLiLpHdlampLvlRiLvlRiChks ExLiLpHdlampLvlRiLvlRiCntr ExLiLpHdlampLvlRiLvlRiEna ExLiLpHdlampLvlRiLvlRiMotSply ExLiLpHdlampLvlRiLvlRiRefForce ExLiLpHdlampLvlRiLvlRiRefOk ExLiLpHdlampLvlRiLvlRiReq;
SIG_GROUP_ 341 ExLiLpHiDefHozlLe 1 : ExLiLpHiDefHozlLeDLPHozlLeEna ExLiLpHiDefHozlLeDLPHozlLeReq;
SIG_GROUP_ 341 ExLiLpHiDefHozlRi 1 : ExLiLpHiDefHozlRiDLPHozlRiEna ExLiLpHiDefHozlRiDLPHozlRiReq;
SIG_GROUP_ 341 ExLiLpHiDefLiLe 1 : ExLiLpHiDefLiLeDLPLeShape ExLiLpHiDefLiLeDLPLeSlope ExLiLpHiDefLiLeDLPLeTransition ExLiLpHiDefLiLeTrafficSide;
SIG_GROUP_ 341 ExLiLpHiDefLiRi 1 : ExLiLpHiDefLiRiDLPRiShape ExLiLpHiDefLiRiDLPRiSlope ExLiLpHiDefLiRiDLPRiTransition ExLiLpHiDefLiRiTrafficSide;
SIG_GROUP_ 340 ExLiLpHiDefZone1 1 : ExLiLpHiDefZone1BottomAg ExLiLpHiDefZone1GradWdth ExLiLpHiDefZone1LeAgPrpty ExLiLpHiDefZone1LeLampLeAg ExLiLpHiDefZone1LeLampRiAg ExLiLpHiDefZone1ObjctZoneIntens ExLiLpHiDefZone1RiAgPrpty ExLiLpHiDefZone1RiLampLeAg ExLiLpHiDefZone1RiLampRiAg ExLiLpHiDefZone1TopAg;
SIG_GROUP_ 340 ExLiLpHiDefZone2 1 : ExLiLpHiDefZone2BottomAg ExLiLpHiDefZone2GradWdth ExLiLpHiDefZone2LeAgPrpty ExLiLpHiDefZone2LeLampLeAg ExLiLpHiDefZone2LeLampRiAg ExLiLpHiDefZone2ObjctZoneIntens ExLiLpHiDefZone2RiAgPrpty ExLiLpHiDefZone2RiLampLeAg ExLiLpHiDefZone2RiLampRiAg ExLiLpHiDefZone2TopAg;
SIG_GROUP_ 340 ExLiLpHiDefZone3 1 : ExLiLpHiDefZone3BottomAg ExLiLpHiDefZone3GradWdth ExLiLpHiDefZone3LeAgPrpty ExLiLpHiDefZone3LeLampLeAg ExLiLpHiDefZone3LeLampRiAg ExLiLpHiDefZone3ObjctZoneIntens ExLiLpHiDefZone3RiAgPrpty ExLiLpHiDefZone3RiLampLeAg ExLiLpHiDefZone3RiLampRiAg ExLiLpHiDefZone3TopAg;
SIG_GROUP_ 340 ExLiLpHiDefZone4 1 : ExLiLpHiDefZone4BottomAg ExLiLpHiDefZone4GradWdth ExLiLpHiDefZone4LeAgPrpty ExLiLpHiDefZone4LeLampLeAg ExLiLpHiDefZone4LeLampRiAg ExLiLpHiDefZone4ObjctZoneIntens ExLiLpHiDefZone4RiAgPrpty ExLiLpHiDefZone4RiLampLeAg ExLiLpHiDefZone4RiLampRiAg ExLiLpHiDefZone4TopAg;
SIG_GROUP_ 340 ExLiLpHiDefZone5 1 : ExLiLpHiDefZone5BottomAg ExLiLpHiDefZone5GradWdth ExLiLpHiDefZone5LeAgPrpty ExLiLpHiDefZone5LeLampLeAg ExLiLpHiDefZone5LeLampRiAg ExLiLpHiDefZone5ObjctZoneIntens ExLiLpHiDefZone5RiAgPrpty ExLiLpHiDefZone5RiLampLeAg ExLiLpHiDefZone5RiLampRiAg ExLiLpHiDefZone5TopAg;
SIG_GROUP_ 341 ExLiLpHiDefZone6 1 : ExLiLpHiDefZone6BottomAg ExLiLpHiDefZone6GradWdth ExLiLpHiDefZone6LeAgPrpty ExLiLpHiDefZone6LeLampLeAg ExLiLpHiDefZone6LeLampRiAg ExLiLpHiDefZone6ObjctZoneIntens ExLiLpHiDefZone6RiAgPrpty ExLiLpHiDefZone6RiLampLeAg ExLiLpHiDefZone6RiLampRiAg ExLiLpHiDefZone6TopAg;
SIG_GROUP_ 341 ExLiLpHiDefZone7 1 : ExLiLpHiDefZone7BottomAg ExLiLpHiDefZone7GradWdth ExLiLpHiDefZone7LeAgPrpty ExLiLpHiDefZone7LeLampLeAg ExLiLpHiDefZone7LeLampRiAg ExLiLpHiDefZone7ObjctZoneIntens ExLiLpHiDefZone7RiAgPrpty ExLiLpHiDefZone7RiLampLeAg ExLiLpHiDefZone7RiLampRiAg ExLiLpHiDefZone7TopAg;
SIG_GROUP_ 341 ExLiLpHiDefZone8 1 : ExLiLpHiDefZone8BottomAg ExLiLpHiDefZone8GradWdth ExLiLpHiDefZone8LeAgPrpty ExLiLpHiDefZone8LeLampLeAg ExLiLpHiDefZone8LeLampRiAg ExLiLpHiDefZone8ObjctZoneIntens ExLiLpHiDefZone8RiAgPrpty ExLiLpHiDefZone8RiLampLeAg ExLiLpHiDefZone8RiLampRiAg ExLiLpHiDefZone8TopAg;
SIG_GROUP_ 342 FrntWhlAg 1 : FrntWhlAgFrntWhlAg FrntWhlAgMaxWhlAg;
SIG_GROUP_ 338 IntrLiUsrPrsnt 1 : IntrLiUsrPrsntDrvrSeat IntrLiUsrPrsntPassSeat IntrLiUsrPrsntReCentrSeat2nd IntrLiUsrPrsntReDrvrSeat2nd IntrLiUsrPrsntReDrvrSeat3nd IntrLiUsrPrsntRePassSeat2nd IntrLiUsrPrsntRePassSeat3nd IntrLiUsrPrsntTrAr;
SIG_GROUP_ 342 LCMACarCfg 1 : LCMACarCfgBlisInfoSys;
SIG_GROUP_ 336 LockgExtReq 1 : LockgExtReqLockActv LockgExtReqLockDly LockgExtReqLockRep;
SIG_GROUP_ 336 LockgSetgFb 1 : LockgSetgFbAudibleFeedback LockgSetgFbVisibleFeedback;
SIG_GROUP_ 336 LockgSetgPas 1 : LockgSetgPasLockBySpeed LockgSetgPasLockWalkAway LockgSetgPasUnlockApproach;
SIG_GROUP_ 336 MirrCmdRecAtDrvr 1 : MirrCmdRecAtDrvrMirrFoldCmd MirrCmdRecAtDrvrMirrPosAdjCmd;
SIG_GROUP_ 336 MirrCmdRecAtPass 1 : MirrCmdRecAtPassMirrFoldCmd MirrCmdRecAtPassMirrPosAdjCmd;
SIG_GROUP_ 336 MirrorFuncCarCfg 1 : MirrorFuncCarCfgExtRearViewMirrorType MirrorFuncCarCfgRearViewMirrorDimType MirrorFuncCarCfgRearViewMirrorMemType;
SIG_GROUP_ 336 MirrPosnSensTrgtValDrvr 1 : MirrPosnSensTrgtValDrvrMirrSensXPos MirrPosnSensTrgtValDrvrMirrSensYPos;
SIG_GROUP_ 336 MirrPosnSensTrgtValPass 1 : MirrPosnSensTrgtValPassMirrSensXPos MirrPosnSensTrgtValPassMirrSensYPos;
SIG_GROUP_ 336 PassAirbLmpReq 1 : PassAirbLmpReqChks PassAirbLmpReqCntr PassAirbLmpReqPassAirbLmpReq;
SIG_GROUP_ 338 PinionAg 1 : PinionAgPinionSteerAg1 PinionAgPinionSteerAg1Qf;
SIG_GROUP_ 338 PowerControllerRlySync 1 : PowerControllerRlySyncADPMWakeUpSync PowerControllerRlySyncAUDWakeUpSync PowerControllerRlySyncChks PowerControllerRlySyncClimateActuatorRelaySync PowerControllerRlySyncCntr PowerControllerRlySyncDIMWakeUpSync PowerControllerRlySyncExteriorLightRelaySync PowerControllerRlySyncIgnitionPowerRelaySync PowerControllerRlySyncSUMWakeUpSync;
SIG_GROUP_ 342 ReFogLi 1 : ReFogLiIntensity ReFogLiReq ReFogLiSlope;
SIG_GROUP_ 342 RegLi 1 : RegLiReq RegLiSlope;
SIG_GROUP_ 342 RePosLi 1 : RePosLiChks RePosLiCntr RePosLiReq RePosLiSlope RePosLiTransition;
SIG_GROUP_ 342 RevLi 1 : RevLiReq RevLiSlope;
SIG_GROUP_ 342 RoadIncln 1 : RoadInclnQly RoadInclnRoadIncln;
SIG_GROUP_ 338 VehModMngmntSigDCU 1 : VehModMngmntSigDCUCarModeSts VehModMngmntSigDCUCarModeSubType VehModMngmntSigDCUElecEnergyLvlDCU VehModMngmntSigDCUElecPowerLvlDCU VehModMngmntSigDCUReserved1 VehModMngmntSigDCUReserved2 VehModMngmntSigDCUUsageModeSts;
SIG_GROUP_ 336 WindowsFuncCarCfg 1 : WindowsFuncCarCfgPinchProtectionLvl WindowsFuncCarCfgReserved0 WindowsFuncCarCfgTailgateWindowTintType WindowsFuncCarCfgWindowsGlassType;
